VERSION "dbc-export 1 2025.20.8"

NS_ :

BS_:

BU_: ADSP APB APP APS APSB BB BMS CC CMP CMPD CP DAS DI DIF DIR DPB EPAS3P EPAS3S EPASTP EPASTS EPBL EPBR ESP GTW HVP IBST ICR IDB OCS1P ODIN PARK PCS PLG PM PMF PMR PTC RADC RCM RCM2 RCU SCCM SDCR TAS TCU TPMS TRCM UDS UI UIS UMC USM VC VCFRONT VCLEFT VCRIGHT VCSEC

BO_ 1520 USM_alertLog: 8 USM
 SG_ USM_alertID M : 0|8@1+ (1,0) [0|255] "" Vector__XXX
 SG_ USM_alertState : 15|1@1+ (1,0) [0|1] "" Vector__XXX
 SG_ USM_a001_InternalWatchdog m1 : 16|1@1+ (1,0) [0|1] "" Vector__XXX
 SG_ USM_a002_CPUUndervoltage m2 : 16|1@1+ (1,0) [0|1] "" Vector__XXX
 SG_ USM_a002_PowerOnReset m2 : 17|1@1+ (1,0) [0|1] "" Vector__XXX
 SG_ USM_a015_NVMMMemOverflow m15 : 16|1@1+ (1,0) [0|1] "" Vector__XXX
 SG_ USM_a015_NVMMFilesystemError m15 : 17|1@1+ (1,0) [0|1] "" Vector__XXX
 SG_ USM_a015_NVMMRecordIDError m15 : 18|1@1+ (1,0) [0|1] "" Vector__XXX
 SG_ USM_a057_VEH_cpControl m57 : 16|1@1+ (1,0) [0|1] "" Vector__XXX
 SG_ USM_a059_voltageDrop m59 : 16|12@1+ (0.005443676,0) [0|22.29185322] "V" Vector__XXX
 SG_ USM_a059_resistanceEstimate m59 : 28|12@1+ (0.00244,0) [0|9.9918] "Ohms" Vector__XXX
 SG_ USM_a059_current m59 : 40|12@1+ (0.05,0) [0|204.75] "A" Vector__XXX
 SG_ USM_a063_switchChannel m63 : 16|8@1+ (1,0) [0|255] "" Vector__XXX
 SG_ USM_a063_switchType m63 : 24|8@1+ (1,0) [0|255] "" Vector__XXX
 SG_ USM_a063_ADCVoltage m63 : 32|8@1+ (0.025,0) [0|6.375] "V" Vector__XXX
 SG_ USM_a063_disconnected m63 : 40|1@1+ (1,0) [0|1] "" Vector__XXX
 SG_ USM_a063_indeterminate m63 : 41|1@1+ (1,0) [0|1] "" Vector__XXX
 SG_ USM_a063_stuckActive m63 : 42|1@1+ (1,0) [0|1] "" Vector__XXX
 SG_ USM_a063_faulted m63 : 43|1@1+ (1,0) [0|1] "" Vector__XXX
 SG_ USM_a082_RIPC_epbPrivateState m82 : 16|1@1+ (1,0) [0|1] "" Vector__XXX
 SG_ USM_a082_RIPC_remoteHSD m82 : 17|1@1+ (1,0) [0|1] "" Vector__XXX
 SG_ USM_a082_RIPC_railStatus m82 : 18|1@1+ (1,0) [0|1] "" Vector__XXX
 SG_ USM_a082_RIPC_remoteMux m82 : 19|1@1+ (1,0) [0|1] "" Vector__XXX
 SG_ USM_a083_LIPC_epbPrivateState m83 : 16|1@1+ (1,0) [0|1] "" Vector__XXX
 SG_ USM_a083_LIPC_remoteHSD m83 : 17|1@1+ (1,0) [0|1] "" Vector__XXX
 SG_ USM_a083_LIPC_railStatus m83 : 18|1@1+ (1,0) [0|1] "" Vector__XXX
 SG_ USM_a083_LIPC_HSDFaults m83 : 19|1@1+ (1,0) [0|1] "" Vector__XXX
 SG_ USM_a084_CH_StatusC m84 : 16|1@1+ (1,0) [0|1] "" Vector__XXX
 SG_ USM_a085_PARTY_buttonStatus m85 : 16|1@1+ (1,0) [0|1] "" Vector__XXX
 SG_ USM_a086_VEH_LVBMS_statusHigh m86 : 16|1@1+ (1,0) [0|1] "" Vector__XXX
 SG_ USM_a086_VEH_LVBMS_statusLow m86 : 17|1@1+ (1,0) [0|1] "" Vector__XXX
 SG_ USM_a086_VEH_status m86 : 18|1@1+ (1,0) [0|1] "" Vector__XXX
 SG_ USM_a086_VEH_12VBatteryStatus m86 : 19|1@1+ (1,0) [0|1] "" Vector__XXX
 SG_ USM_a086_VEH_LVPowerState m86 : 20|1@1+ (1,0) [0|1] "" Vector__XXX
 SG_ USM_a086_VEH_lightStatus m86 : 21|1@1+ (1,0) [0|1] "" Vector__XXX
 SG_ USM_a086_VEH_systemStatus m86 : 22|1@1+ (1,0) [0|1] "" Vector__XXX
 SG_ USM_a086_VEH_thermalStatus m86 : 23|1@1+ (1,0) [0|1] "" Vector__XXX
 SG_ USM_a086_VEH_vehNm m86 : 24|1@1+ (1,0) [0|1] "" Vector__XXX
 SG_ USM_a087_VEH_temperature m87 : 16|1@1+ (1,0) [0|1] "" Vector__XXX
 SG_ USM_a087_VEH_thermalControl m87 : 17|1@1+ (1,0) [0|1] "" Vector__XXX
 SG_ USM_a087_VEH_torque m87 : 18|1@1+ (1,0) [0|1] "" Vector__XXX
 SG_ USM_a087_VEH_status m87 : 19|1@1+ (1,0) [0|1] "" Vector__XXX
 SG_ USM_a087_PARTY_torque m87 : 20|1@1+ (1,0) [0|1] "" Vector__XXX
 SG_ USM_a087_PARTY_status m87 : 21|1@1+ (1,0) [0|1] "" Vector__XXX
 SG_ USM_a087_PARTY_temperature m87 : 22|1@1+ (1,0) [0|1] "" Vector__XXX
 SG_ USM_a087_PARTY_thermalControl m87 : 23|1@1+ (1,0) [0|1] "" Vector__XXX
 SG_ USM_a088_VEH_temperature m88 : 16|1@1+ (1,0) [0|1] "" Vector__XXX
 SG_ USM_a088_VEH_thermalControl m88 : 17|1@1+ (1,0) [0|1] "" Vector__XXX
 SG_ USM_a088_VEH_torque m88 : 18|1@1+ (1,0) [0|1] "" Vector__XXX
 SG_ USM_a088_VEH_status m88 : 19|1@1+ (1,0) [0|1] "" Vector__XXX
 SG_ USM_a088_PARTY_torque m88 : 20|1@1+ (1,0) [0|1] "" Vector__XXX
 SG_ USM_a088_PARTY_status m88 : 21|1@1+ (1,0) [0|1] "" Vector__XXX
 SG_ USM_a088_PARTY_temperature m88 : 22|1@1+ (1,0) [0|1] "" Vector__XXX
 SG_ USM_a088_PARTY_thermalControl m88 : 23|1@1+ (1,0) [0|1] "" Vector__XXX
 SG_ USM_a089_PARTY_party1 m89 : 16|1@1+ (1,0) [0|1] "" Vector__XXX
 SG_ USM_a089_PARTY_status m89 : 17|1@1+ (1,0) [0|1] "" Vector__XXX
 SG_ USM_a089_VEH_status m89 : 18|1@1+ (1,0) [0|1] "" Vector__XXX
 SG_ USM_a089_BDY_party1 m89 : 19|1@1+ (1,0) [0|1] "" Vector__XXX
 SG_ USM_a089_BDY_status m89 : 20|1@1+ (1,0) [0|1] "" Vector__XXX
 SG_ USM_a089_CH_status m89 : 21|1@1+ (1,0) [0|1] "" Vector__XXX
 SG_ USM_a089_CH_party1 m89 : 22|1@1+ (1,0) [0|1] "" Vector__XXX
 SG_ USM_a089_CH_party3 m89 : 23|1@1+ (1,0) [0|1] "" Vector__XXX
 SG_ USM_a089_VEH_party1 m89 : 24|1@1+ (1,0) [0|1] "" Vector__XXX
 SG_ USM_a089_VEH_party3 m89 : 25|1@1+ (1,0) [0|1] "" Vector__XXX
 SG_ USM_a091_VEH_faultsAndExtras m91 : 16|1@1+ (1,0) [0|1] "" Vector__XXX
 SG_ USM_a091_VEH_info m91 : 17|1@1+ (1,0) [0|1] "" Vector__XXX
 SG_ USM_a091_VEH_state m91 : 18|1@1+ (1,0) [0|1] "" Vector__XXX
 SG_ USM_a092_VEH_restraintStatus m92 : 16|1@1+ (1,0) [0|1] "" Vector__XXX
 SG_ USM_a092_VEH_switchStatus m92 : 17|1@1+ (1,0) [0|1] "" Vector__XXX
 SG_ USM_a092_VEH_seatStatus2 m92 : 18|1@1+ (1,0) [0|1] "" Vector__XXX
 SG_ USM_a092_VEH_vehNm m92 : 19|1@1+ (1,0) [0|1] "" Vector__XXX
 SG_ USM_a093_VEH_restraintStatus m93 : 16|1@1+ (1,0) [0|1] "" Vector__XXX
 SG_ USM_a093_VEH_switchStatus m93 : 17|1@1+ (1,0) [0|1] "" Vector__XXX
 SG_ USM_a093_VEH_seatStatus2 m93 : 18|1@1+ (1,0) [0|1] "" Vector__XXX
 SG_ USM_a093_VEH_vehNm m93 : 19|1@1+ (1,0) [0|1] "" Vector__XXX
 SG_ USM_a094_VEH_sysStatus m94 : 16|1@1+ (1,0) [0|1] "" Vector__XXX
 SG_ USM_a094_PARTY_sysStatus m94 : 17|1@1+ (1,0) [0|1] "" Vector__XXX
 SG_ USM_a095_PT_ptNm m95 : 16|1@1+ (1,0) [0|1] "" Vector__XXX
 SG_ USM_a095_PT_status m95 : 17|1@1+ (1,0) [0|1] "" Vector__XXX
 SG_ USM_a096_VEH_status m96 : 16|1@1+ (1,0) [0|1] "" Vector__XXX
 SG_ USM_a096_CH_status m96 : 17|1@1+ (1,0) [0|1] "" Vector__XXX
 SG_ USM_a098_CH_torque m98 : 16|1@1+ (1,0) [0|1] "" Vector__XXX
 SG_ USM_a098_VEH_hvStatus m98 : 17|1@1+ (1,0) [0|1] "" Vector__XXX
 SG_ USM_a098_VEH_status m98 : 18|1@1+ (1,0) [0|1] "" Vector__XXX
 SG_ USM_a098_VEH_thermalControl m98 : 19|1@1+ (1,0) [0|1] "" Vector__XXX
 SG_ USM_a098_VEH_temperature m98 : 20|1@1+ (1,0) [0|1] "" Vector__XXX
 SG_ USM_a098_VEH_torque m98 : 21|1@1+ (1,0) [0|1] "" Vector__XXX
 SG_ USM_a098_PARTY_status m98 : 22|1@1+ (1,0) [0|1] "" Vector__XXX
 SG_ USM_a098_PARTY_temperature m98 : 23|1@1+ (1,0) [0|1] "" Vector__XXX
 SG_ USM_a098_PARTY_thermalControl m98 : 24|1@1+ (1,0) [0|1] "" Vector__XXX
 SG_ USM_a098_PARTY_torque m98 : 25|1@1+ (1,0) [0|1] "" Vector__XXX
 SG_ USM_a098_PT_thermalControl m98 : 26|1@1+ (1,0) [0|1] "" Vector__XXX
 SG_ USM_a098_PT_temperature m98 : 27|1@1+ (1,0) [0|1] "" Vector__XXX
 SG_ USM_a099_VEH_oocStatus m99 : 16|1@1+ (1,0) [0|1] "" Vector__XXX
 SG_ USM_a100_VEH m100 : 16|1@1+ (1,0) [0|1] "" Vector__XXX
 SG_ USM_a100_PARTY m100 : 17|1@1+ (1,0) [0|1] "" Vector__XXX
 SG_ USM_a100_PT m100 : 18|1@1+ (1,0) [0|1] "" Vector__XXX
 SG_ USM_a100_CH m100 : 19|1@1+ (1,0) [0|1] "" Vector__XXX
 SG_ USM_a100_OBD m100 : 20|1@1+ (1,0) [0|1] "" Vector__XXX
 SG_ USM_a101_VEH_state m101 : 16|1@1+ (1,0) [0|1] "" Vector__XXX
 SG_ USM_a101_PARTY_locState m101 : 17|1@1+ (1,0) [0|1] "" Vector__XXX
 SG_ USM_a101_LIPC_externalWatchdogHe m101 : 18|1@1+ (1,0) [0|1] "" Vector__XXX
 SG_ USM_a101_VEH_locState m101 : 19|1@1+ (1,0) [0|1] "" Vector__XXX
 SG_ USM_a101_BDY_locState m101 : 20|1@1+ (1,0) [0|1] "" Vector__XXX
 SG_ USM_a102_VEH_faultsAndExtras m102 : 16|1@1+ (1,0) [0|1] "" Vector__XXX
 SG_ USM_a102_VEH_feedbackStatus m102 : 17|1@1+ (1,0) [0|1] "" Vector__XXX
 SG_ USM_a102_VEH_sensorStatus m102 : 18|1@1+ (1,0) [0|1] "" Vector__XXX
 SG_ USM_a102_VEH_rods m102 : 19|1@1+ (1,0) [0|1] "" Vector__XXX
 SG_ USM_a103_VEH_hvsNm m103 : 16|1@1+ (1,0) [0|1] "" Vector__XXX
 SG_ USM_a103_VEH_vehNm m103 : 17|1@1+ (1,0) [0|1] "" Vector__XXX
 SG_ USM_a103_VEH_status m103 : 18|1@1+ (1,0) [0|1] "" Vector__XXX
 SG_ USM_a103_PT_ptNm m103 : 19|1@1+ (1,0) [0|1] "" Vector__XXX
 SG_ USM_a103_PT_status m103 : 20|1@1+ (1,0) [0|1] "" Vector__XXX
 SG_ USM_a103_VEH_evseStatus m103 : 21|1@1+ (1,0) [0|1] "" Vector__XXX
 SG_ USM_a105_VEH_states m105 : 16|1@1+ (1,0) [0|1] "" Vector__XXX
 SG_ USM_a105_VEH_chNm m105 : 17|1@1+ (1,0) [0|1] "" Vector__XXX
 SG_ USM_a105_VEH_dampingStates m105 : 18|1@1+ (1,0) [0|1] "" Vector__XXX
 SG_ USM_a106_VEH_dcdcStatus m106 : 16|1@1+ (1,0) [0|1] "" Vector__XXX
 SG_ USM_a106_VEH_thermalControl m106 : 17|1@1+ (1,0) [0|1] "" Vector__XXX
 SG_ USM_a106_VEH_thermalInterface m106 : 18|1@1+ (1,0) [0|1] "" Vector__XXX
 SG_ USM_a106_VEH_dcdcRailStatus m106 : 19|1@1+ (1,0) [0|1] "" Vector__XXX
 SG_ USM_a106_CH_dcdcRailStatus m106 : 20|1@1+ (1,0) [0|1] "" Vector__XXX
 SG_ USM_a106_CH_alertMatrix m106 : 21|1@1+ (1,0) [0|1] "" Vector__XXX
 SG_ USM_a107_VEH_hvsNm m107 : 16|1@1+ (1,0) [0|1] "" Vector__XXX
 SG_ USM_a107_VEH_vehNm m107 : 17|1@1+ (1,0) [0|1] "" Vector__XXX
 SG_ USM_a107_VEH_status m107 : 18|1@1+ (1,0) [0|1] "" Vector__XXX
 SG_ USM_a107_VEH_thermalStatus m107 : 19|1@1+ (1,0) [0|1] "" Vector__XXX
 SG_ USM_a107_VEH_thermalStatus2 m107 : 20|1@1+ (1,0) [0|1] "" Vector__XXX
 SG_ USM_a107_VEH_bmbMinMax m107 : 21|1@1+ (1,0) [0|1] "" Vector__XXX
 SG_ USM_a107_VEH_powerAvailable m107 : 22|1@1+ (1,0) [0|1] "" Vector__XXX
 SG_ USM_a107_PT_ptNm m107 : 23|1@1+ (1,0) [0|1] "" Vector__XXX
 SG_ USM_a107_PT_status m107 : 24|1@1+ (1,0) [0|1] "" Vector__XXX
 SG_ USM_a107_PT_thermalStatus m107 : 25|1@1+ (1,0) [0|1] "" Vector__XXX
 SG_ USM_a107_PT_socStatus m107 : 26|1@1+ (1,0) [0|1] "" Vector__XXX
 SG_ USM_a107_VEH_socStatus m107 : 27|1@1+ (1,0) [0|1] "" Vector__XXX
 SG_ USM_a107_VEH_packConfig m107 : 28|1@1+ (1,0) [0|1] "" Vector__XXX
 SG_ USM_a107_VEH_energyStatus m107 : 29|1@1+ (1,0) [0|1] "" Vector__XXX
 SG_ USM_a107_VEH_chargeInfo m107 : 30|1@1+ (1,0) [0|1] "" Vector__XXX
 SG_ USM_a108_VEH_hvStatus m108 : 16|1@1+ (1,0) [0|1] "" Vector__XXX
 SG_ USM_a108_VEH_temperature m108 : 17|1@1+ (1,0) [0|1] "" Vector__XXX
 SG_ USM_a108_VEH_thermalControl m108 : 18|1@1+ (1,0) [0|1] "" Vector__XXX
 SG_ USM_a108_VEH_torque m108 : 19|1@1+ (1,0) [0|1] "" Vector__XXX
 SG_ USM_a108_VEH_status m108 : 20|1@1+ (1,0) [0|1] "" Vector__XXX
 SG_ USM_a108_PARTY_torque m108 : 21|1@1+ (1,0) [0|1] "" Vector__XXX
 SG_ USM_a108_PARTY_status m108 : 22|1@1+ (1,0) [0|1] "" Vector__XXX
 SG_ USM_a108_PARTY_temperature m108 : 23|1@1+ (1,0) [0|1] "" Vector__XXX
 SG_ USM_a108_PARTY_thermalControl m108 : 24|1@1+ (1,0) [0|1] "" Vector__XXX
 SG_ USM_a108_PT_temperature m108 : 25|1@1+ (1,0) [0|1] "" Vector__XXX
 SG_ USM_a108_PT_thermalControl m108 : 26|1@1+ (1,0) [0|1] "" Vector__XXX
 SG_ USM_a109_PARTY_status m109 : 16|1@1+ (1,0) [0|1] "" Vector__XXX
 SG_ USM_a109_PARTY_inertial2 m109 : 17|1@1+ (1,0) [0|1] "" Vector__XXX
 SG_ USM_a109_PARTY_nearDeploy m109 : 18|1@1+ (1,0) [0|1] "" Vector__XXX
 SG_ USM_a109_PARTY_collision m109 : 19|1@1+ (1,0) [0|1] "" Vector__XXX
 SG_ USM_a109_VEH_status m109 : 20|1@1+ (1,0) [0|1] "" Vector__XXX
 SG_ USM_a109_VEH_imuOffsets m109 : 21|1@1+ (1,0) [0|1] "" Vector__XXX
 SG_ USM_a109_PARTY_inertial1 m109 : 22|1@1+ (1,0) [0|1] "" Vector__XXX
 SG_ USM_a109_BDY_imuOffsets m109 : 23|1@1+ (1,0) [0|1] "" Vector__XXX
 SG_ USM_a109_BDY_inertial1 m109 : 24|1@1+ (1,0) [0|1] "" Vector__XXX
 SG_ USM_a109_BDY_inertial2 m109 : 25|1@1+ (1,0) [0|1] "" Vector__XXX
 SG_ USM_a109_BDY_status m109 : 26|1@1+ (1,0) [0|1] "" Vector__XXX
 SG_ USM_a109_VEH_inertial1 m109 : 27|1@1+ (1,0) [0|1] "" Vector__XXX
 SG_ USM_a109_VEH_inertial2 m109 : 28|1@1+ (1,0) [0|1] "" Vector__XXX
 SG_ USM_a109_CH_inertial1 m109 : 29|1@1+ (1,0) [0|1] "" Vector__XXX
 SG_ USM_a109_CH_inertial2 m109 : 30|1@1+ (1,0) [0|1] "" Vector__XXX
 SG_ USM_a109_CH_status m109 : 31|1@1+ (1,0) [0|1] "" Vector__XXX
 SG_ USM_a110_VEH_carState m110 : 16|1@1+ (1,0) [0|1] "" Vector__XXX
 SG_ USM_a110_VEH_carConfig m110 : 17|1@1+ (1,0) [0|1] "" Vector__XXX
 SG_ USM_a110_VEH_time m110 : 18|1@1+ (1,0) [0|1] "" Vector__XXX
 SG_ USM_a110_VEH_updateStatus m110 : 19|1@1+ (1,0) [0|1] "" Vector__XXX
 SG_ USM_a110_VEH_vehNm m110 : 20|1@1+ (1,0) [0|1] "" Vector__XXX
 SG_ USM_a110_VEH_mismatchFault m110 : 21|1@1+ (1,0) [0|1] "" Vector__XXX
 SG_ USM_a110_VEH_vin m110 : 22|1@1+ (1,0) [0|1] "" Vector__XXX
 SG_ USM_a110_VEH_bmpDebug m110 : 23|1@1+ (1,0) [0|1] "" Vector__XXX
 SG_ USM_a110_VEH_gearControl m110 : 24|1@1+ (1,0) [0|1] "" Vector__XXX
 SG_ USM_a110_VEH_canLogAvailability m110 : 25|1@1+ (1,0) [0|1] "" Vector__XXX
 SG_ USM_a110_CH_airbagCutoffStatus m110 : 26|1@1+ (1,0) [0|1] "" Vector__XXX
 SG_ USM_a110_CH_carConfig m110 : 27|1@1+ (1,0) [0|1] "" Vector__XXX
 SG_ USM_a110_CH_carState m110 : 28|1@1+ (1,0) [0|1] "" Vector__XXX
 SG_ USM_a110_CH_vin m110 : 29|1@1+ (1,0) [0|1] "" Vector__XXX
 SG_ USM_a110_CH_chNm m110 : 30|1@1+ (1,0) [0|1] "" Vector__XXX
 SG_ USM_a110_CH_epochTimeGtw m110 : 31|1@1+ (1,0) [0|1] "" Vector__XXX
 SG_ USM_a111_VEH_internalStatus m111 : 16|1@1+ (1,0) [0|1] "" Vector__XXX
 SG_ USM_a111_VEH_status m111 : 17|1@1+ (1,0) [0|1] "" Vector__XXX
 SG_ USM_a111_VEH_vehNm m111 : 18|1@1+ (1,0) [0|1] "" Vector__XXX
 SG_ USM_a111_RIPC_LVPowerState m111 : 19|1@1+ (1,0) [0|1] "" Vector__XXX
 SG_ USM_a111_RIPC_epbPrivateState m111 : 20|1@1+ (1,0) [0|1] "" Vector__XXX
 SG_ USM_a111_RIPC_railStatus m111 : 21|1@1+ (1,0) [0|1] "" Vector__XXX
 SG_ USM_a111_RIPC_remoteADC m111 : 22|1@1+ (1,0) [0|1] "" Vector__XXX
 SG_ USM_a111_RIPC_switchStatus m111 : 23|1@1+ (1,0) [0|1] "" Vector__XXX
 SG_ USM_a111_VEH_LVPowerState m111 : 24|1@1+ (1,0) [0|1] "" Vector__XXX
 SG_ USM_a111_VEH_seatStatus m111 : 25|1@1+ (1,0) [0|1] "" Vector__XXX
 SG_ USM_a111_PARTY_status m111 : 26|1@1+ (1,0) [0|1] "" Vector__XXX
 SG_ USM_a111_CH_status m111 : 27|1@1+ (1,0) [0|1] "" Vector__XXX
 SG_ USM_a112_VEH_internalStatus m112 : 16|1@1+ (1,0) [0|1] "" Vector__XXX
 SG_ USM_a112_VEH_status m112 : 17|1@1+ (1,0) [0|1] "" Vector__XXX
 SG_ USM_a112_VEH_vehNm m112 : 18|1@1+ (1,0) [0|1] "" Vector__XXX
 SG_ USM_a112_LIPC_LVPowerState m112 : 19|1@1+ (1,0) [0|1] "" Vector__XXX
 SG_ USM_a112_LIPC_epbPrivateState m112 : 20|1@1+ (1,0) [0|1] "" Vector__XXX
 SG_ USM_a112_LIPC_railStatus m112 : 21|1@1+ (1,0) [0|1] "" Vector__XXX
 SG_ USM_a112_LIPC_remoteADC m112 : 22|1@1+ (1,0) [0|1] "" Vector__XXX
 SG_ USM_a112_LIPC_switchStatus m112 : 23|1@1+ (1,0) [0|1] "" Vector__XXX
 SG_ USM_a112_VEH_LVPowerState m112 : 24|1@1+ (1,0) [0|1] "" Vector__XXX
 SG_ USM_a112_PARTY_status m112 : 25|1@1+ (1,0) [0|1] "" Vector__XXX
 SG_ USM_a112_CH_status m112 : 26|1@1+ (1,0) [0|1] "" Vector__XXX
 SG_ USM_a114_PARTY_status m114 : 16|1@1+ (1,0) [0|1] "" Vector__XXX
 SG_ USM_a114_PARTY_wheelSpeeds m114 : 17|1@1+ (1,0) [0|1] "" Vector__XXX
 SG_ USM_a114_VEH_wheelSpeeds m114 : 18|1@1+ (1,0) [0|1] "" Vector__XXX
 SG_ USM_a114_CH_wheelSpeeds m114 : 19|1@1+ (1,0) [0|1] "" Vector__XXX
 SG_ USM_a114_PARTY_party3 m114 : 20|1@1+ (1,0) [0|1] "" Vector__XXX
 SG_ USM_a114_VEH_party3 m114 : 21|1@1+ (1,0) [0|1] "" Vector__XXX
 SG_ USM_a114_VEH_status m114 : 22|1@1+ (1,0) [0|1] "" Vector__XXX
 SG_ USM_a114_PARTY_wheelRotation m114 : 23|1@1+ (1,0) [0|1] "" Vector__XXX
 SG_ USM_a114_CH_wheelRotation m114 : 24|1@1+ (1,0) [0|1] "" Vector__XXX
 SG_ USM_a114_VEH_wheelRotation m114 : 25|1@1+ (1,0) [0|1] "" Vector__XXX
 SG_ USM_a114_PARTY_brakeTorque m114 : 26|1@1+ (1,0) [0|1] "" Vector__XXX
 SG_ USM_a114_PARTY_offsets m114 : 27|1@1+ (1,0) [0|1] "" Vector__XXX
 SG_ USM_a114_BDY_offsets m114 : 28|1@1+ (1,0) [0|1] "" Vector__XXX
 SG_ USM_a114_BDY_party3 m114 : 29|1@1+ (1,0) [0|1] "" Vector__XXX
 SG_ USM_a114_BDY_status m114 : 30|1@1+ (1,0) [0|1] "" Vector__XXX
 SG_ USM_a114_BDY_wheelRotation m114 : 31|1@1+ (1,0) [0|1] "" Vector__XXX
 SG_ USM_a114_BDY_wheelSpeeds m114 : 32|1@1+ (1,0) [0|1] "" Vector__XXX
 SG_ USM_a114_CH_party1 m114 : 33|1@1+ (1,0) [0|1] "" Vector__XXX
 SG_ USM_a114_CH_party3 m114 : 34|1@1+ (1,0) [0|1] "" Vector__XXX
 SG_ USM_a114_CH_status m114 : 35|1@1+ (1,0) [0|1] "" Vector__XXX
 SG_ USM_a115_VEH_vehNm m115 : 16|1@1+ (1,0) [0|1] "" Vector__XXX
 SG_ USM_a115_VEH_authentication m115 : 17|1@1+ (1,0) [0|1] "" Vector__XXX
 SG_ USM_a115_VEH_BLEResetRequest m115 : 18|1@1+ (1,0) [0|1] "" Vector__XXX
 SG_ USM_a115_VEH_requests m115 : 19|1@1+ (1,0) [0|1] "" Vector__XXX
 SG_ USM_a115_VEH_requests2 m115 : 20|1@1+ (1,0) [0|1] "" Vector__XXX
 SG_ USM_a115_REM_authentication m115 : 21|1@1+ (1,0) [0|1] "" Vector__XXX
 SG_ USM_a115_UI_corianderVehicleCont m115 : 22|1@1+ (1,0) [0|1] "" Vector__XXX
 SG_ USM_a115_CH_TPMSDisplay m115 : 23|1@1+ (1,0) [0|1] "" Vector__XXX
 SG_ USM_a116_PARTY_epbmStatus m116 : 16|1@1+ (1,0) [0|1] "" Vector__XXX
 SG_ USM_a116_VEH_vehNm m116 : 17|1@1+ (1,0) [0|1] "" Vector__XXX
 SG_ USM_a116_VEH_hvacRequest m116 : 18|1@1+ (1,0) [0|1] "" Vector__XXX
 SG_ USM_a116_VEH_hvacStatus m116 : 19|1@1+ (1,0) [0|1] "" Vector__XXX
 SG_ USM_a116_VEH_LVPowerState m116 : 20|1@1+ (1,0) [0|1] "" Vector__XXX
 SG_ USM_a116_VEH_lightStatus m116 : 21|1@1+ (1,0) [0|1] "" Vector__XXX
 SG_ USM_a116_VEH_seatStatus m116 : 22|1@1+ (1,0) [0|1] "" Vector__XXX
 SG_ USM_a116_VEH_thsStatus m116 : 23|1@1+ (1,0) [0|1] "" Vector__XXX
 SG_ USM_a116_VEH_doorStatus m116 : 24|1@1+ (1,0) [0|1] "" Vector__XXX
 SG_ USM_a116_VEH_seatHeatStatus m116 : 25|1@1+ (1,0) [0|1] "" Vector__XXX
 SG_ USM_a116_VEH_restraintStatus m116 : 26|1@1+ (1,0) [0|1] "" Vector__XXX
 SG_ USM_a116_VEH_switchStatus m116 : 27|1@1+ (1,0) [0|1] "" Vector__XXX
 SG_ USM_a116_VEH_logging1Hz m116 : 28|1@1+ (1,0) [0|1] "" Vector__XXX
 SG_ USM_a116_VEH_seatStatus2 m116 : 29|1@1+ (1,0) [0|1] "" Vector__XXX
 SG_ USM_a116_VEH_status m116 : 30|1@1+ (1,0) [0|1] "" Vector__XXX
 SG_ USM_a116_VEH_thermalCommand m116 : 31|1@1+ (1,0) [0|1] "" Vector__XXX
 SG_ USM_a116_VEH_windowStatus m116 : 32|1@1+ (1,0) [0|1] "" Vector__XXX
 SG_ USM_a116_PARTY_restraintStatus m116 : 33|1@1+ (1,0) [0|1] "" Vector__XXX
 SG_ USM_a116_PARTY_doorStatus m116 : 34|1@1+ (1,0) [0|1] "" Vector__XXX
 SG_ USM_a116_BDY_epbmStatus m116 : 35|1@1+ (1,0) [0|1] "" Vector__XXX
 SG_ USM_a116_BDY_restraintStatus m116 : 36|1@1+ (1,0) [0|1] "" Vector__XXX
 SG_ USM_a117_BDY_epbmStatus m117 : 16|1@1+ (1,0) [0|1] "" Vector__XXX
 SG_ USM_a117_BDY_restraintStatus m117 : 17|1@1+ (1,0) [0|1] "" Vector__XXX
 SG_ USM_a117_VEH_prndStatus m117 : 18|1@1+ (1,0) [0|1] "" Vector__XXX
 SG_ USM_a117_PARTY_epbmStatus m117 : 19|1@1+ (1,0) [0|1] "" Vector__XXX
 SG_ USM_a117_VEH_vehNm m117 : 20|1@1+ (1,0) [0|1] "" Vector__XXX
 SG_ USM_a117_VEH_hvacBlowerFdb m117 : 21|1@1+ (1,0) [0|1] "" Vector__XXX
 SG_ USM_a117_VEH_LVPowerState m117 : 22|1@1+ (1,0) [0|1] "" Vector__XXX
 SG_ USM_a117_VEH_restraintStatus m117 : 23|1@1+ (1,0) [0|1] "" Vector__XXX
 SG_ USM_a117_VEH_lightStatus m117 : 24|1@1+ (1,0) [0|1] "" Vector__XXX
 SG_ USM_a117_VEH_seatStatus m117 : 25|1@1+ (1,0) [0|1] "" Vector__XXX
 SG_ USM_a117_BDY_falconSwitchStatus m117 : 26|1@1+ (1,0) [0|1] "" Vector__XXX
 SG_ USM_a117_VEH_doorStatus m117 : 27|1@1+ (1,0) [0|1] "" Vector__XXX
 SG_ USM_a117_VEH_doorStatus2 m117 : 28|1@1+ (1,0) [0|1] "" Vector__XXX
 SG_ USM_a117_VEH_windowStatus m117 : 29|1@1+ (1,0) [0|1] "" Vector__XXX
 SG_ USM_a117_VEH_switchStatus m117 : 30|1@1+ (1,0) [0|1] "" Vector__XXX
 SG_ USM_a117_VEH_intrusionSensorStat m117 : 31|1@1+ (1,0) [0|1] "" Vector__XXX
 SG_ USM_a117_VEH_liftgateStatus m117 : 32|1@1+ (1,0) [0|1] "" Vector__XXX
 SG_ USM_a117_VEH_seatStatus2 m117 : 33|1@1+ (1,0) [0|1] "" Vector__XXX
 SG_ USM_a117_PARTY_restraintStatus m117 : 34|1@1+ (1,0) [0|1] "" Vector__XXX
 SG_ USM_a117_VEH_thermalStatus m117 : 35|1@1+ (1,0) [0|1] "" Vector__XXX
 SG_ USM_a117_PARTY_doorStatus m117 : 36|1@1+ (1,0) [0|1] "" Vector__XXX
 SG_ USM_a117_VEH_status m117 : 37|1@1+ (1,0) [0|1] "" Vector__XXX
 SG_ USM_a117_PARTY_prndStatus m117 : 38|1@1+ (1,0) [0|1] "" Vector__XXX
 SG_ USM_a118_VEH_vehNm m118 : 16|1@1+ (1,0) [0|1] "" Vector__XXX
 SG_ USM_a118_VEH_lighting m118 : 17|1@1+ (1,0) [0|1] "" Vector__XXX
 SG_ USM_a118_VEH_sensors m118 : 18|1@1+ (1,0) [0|1] "" Vector__XXX
 SG_ USM_a118_VEH_status m118 : 19|1@1+ (1,0) [0|1] "" Vector__XXX
 SG_ USM_a118_VEH_okToUseHighPwr m118 : 20|1@1+ (1,0) [0|1] "" Vector__XXX
 SG_ USM_a118_VEH_LVPowerState m118 : 21|1@1+ (1,0) [0|1] "" Vector__XXX
 SG_ USM_a118_VEH_coolant m118 : 22|1@1+ (1,0) [0|1] "" Vector__XXX
 SG_ USM_a118_VEH_vehicleStatus m118 : 23|1@1+ (1,0) [0|1] "" Vector__XXX
 SG_ USM_a118_VEH_12VBatteryStatus m118 : 24|1@1+ (1,0) [0|1] "" Vector__XXX
 SG_ USM_a118_VEH_systemStatus m118 : 25|1@1+ (1,0) [0|1] "" Vector__XXX
 SG_ USM_a118_PARTY_LVPowerState m118 : 26|1@1+ (1,0) [0|1] "" Vector__XXX
 SG_ USM_a118_PARTY_outputPowerStatus m118 : 27|1@1+ (1,0) [0|1] "" Vector__XXX
 SG_ USM_a118_PARTY_vehicleTime m118 : 28|1@1+ (1,0) [0|1] "" Vector__XXX
 SG_ USM_a118_VEH_thermalCommand m118 : 29|1@1+ (1,0) [0|1] "" Vector__XXX
 SG_ USM_a118_CH_LVPowerState m118 : 30|1@1+ (1,0) [0|1] "" Vector__XXX
 SG_ USM_a118_PARTY_sensors m118 : 31|1@1+ (1,0) [0|1] "" Vector__XXX
 SG_ USM_a118_CH_sensors m118 : 32|1@1+ (1,0) [0|1] "" Vector__XXX
 SG_ USM_a118_VEH_interNodeResistance m118 : 33|1@1+ (1,0) [0|1] "" Vector__XXX
 SG_ USM_a118_CH_lighting m118 : 34|1@1+ (1,0) [0|1] "" Vector__XXX
 SG_ USM_a118_VEH_lightStatus m118 : 35|1@1+ (1,0) [0|1] "" Vector__XXX
 SG_ USM_a118_PARTY_vehNm m118 : 36|1@1+ (1,0) [0|1] "" Vector__XXX
 SG_ USM_a118_CH_12VBatteryStatus m118 : 37|1@1+ (1,0) [0|1] "" Vector__XXX
 SG_ USM_a118_CH_LVBMS_statusHigh m118 : 38|1@1+ (1,0) [0|1] "" Vector__XXX
 SG_ USM_a118_CH_alertMatrix m118 : 39|1@1+ (1,0) [0|1] "" Vector__XXX
 SG_ USM_a118_BDY_outputPowerStatus m118 : 40|1@1+ (1,0) [0|1] "" Vector__XXX
 SG_ USM_a118_BDY_vehicleTime m118 : 41|1@1+ (1,0) [0|1] "" Vector__XXX
 SG_ USM_a118_PARTY_AP_vehicleState1H m118 : 42|1@1+ (1,0) [0|1] "" Vector__XXX
 SG_ USM_a118_BDY_AP_vehicleState1HzM m118 : 43|1@1+ (1,0) [0|1] "" Vector__XXX
 SG_ USM_a119_VEH_steerAngle m119 : 16|1@1+ (1,0) [0|1] "" Vector__XXX
 SG_ USM_a119_VEH_leftStalk m119 : 17|1@1+ (1,0) [0|1] "" Vector__XXX
 SG_ USM_a119_VEH_rightStalk m119 : 18|1@1+ (1,0) [0|1] "" Vector__XXX
 SG_ USM_a119_PARTY_rightStalk m119 : 19|1@1+ (1,0) [0|1] "" Vector__XXX
 SG_ USM_a119_CH_steerAngle m119 : 20|1@1+ (1,0) [0|1] "" Vector__XXX
 SG_ USM_a119_PARTY_steerAngle m119 : 21|1@1+ (1,0) [0|1] "" Vector__XXX
 SG_ USM_a120_PARTY_chassisCntl m120 : 16|1@1+ (1,0) [0|1] "" Vector__XXX
 SG_ USM_a120_VEH_systemStatus m120 : 17|1@1+ (1,0) [0|1] "" Vector__XXX
 SG_ USM_a120_CH_chassisCntl m120 : 18|1@1+ (1,0) [0|1] "" Vector__XXX
 SG_ USM_a120_PARTY_systemStatus m120 : 19|1@1+ (1,0) [0|1] "" Vector__XXX
 SG_ USM_a120_PARTY_torque m120 : 20|1@1+ (1,0) [0|1] "" Vector__XXX
 SG_ USM_a120_VEH_torque m120 : 21|1@1+ (1,0) [0|1] "" Vector__XXX
 SG_ USM_a120_PARTY_locStatus m120 : 22|1@1+ (1,0) [0|1] "" Vector__XXX
 SG_ USM_a120_PARTY_speed m120 : 23|1@1+ (1,0) [0|1] "" Vector__XXX
 SG_ USM_a120_VEH_speed m120 : 24|1@1+ (1,0) [0|1] "" Vector__XXX
 SG_ USM_a120_PARTY_status m120 : 25|1@1+ (1,0) [0|1] "" Vector__XXX
 SG_ USM_a120_PT_speed m120 : 26|1@1+ (1,0) [0|1] "" Vector__XXX
 SG_ USM_a120_PT_systemStatus m120 : 27|1@1+ (1,0) [0|1] "" Vector__XXX
 SG_ USM_a120_PARTY_vehicleEstimates m120 : 28|1@1+ (1,0) [0|1] "" Vector__XXX
 SG_ USM_a120_VEH_aggregatedAxleSpeed m120 : 29|1@1+ (1,0) [0|1] "" Vector__XXX
 SG_ USM_a120_PARTY_aggregatedAxleSpe m120 : 30|1@1+ (1,0) [0|1] "" Vector__XXX
 SG_ USM_a120_VEH_systemPower m120 : 31|1@1+ (1,0) [0|1] "" Vector__XXX
 SG_ USM_a120_PT_systemPower m120 : 32|1@1+ (1,0) [0|1] "" Vector__XXX
 SG_ USM_a120_PARTY_stalklessInterfac m120 : 33|1@1+ (1,0) [0|1] "" Vector__XXX
 SG_ USM_a120_CH_speed m120 : 34|1@1+ (1,0) [0|1] "" Vector__XXX
 SG_ USM_a120_VEH_estimatedBrakeTemp m120 : 35|1@1+ (1,0) [0|1] "" Vector__XXX
 SG_ USM_a120_PARTY_prndControl m120 : 36|1@1+ (1,0) [0|1] "" Vector__XXX
 SG_ USM_a120_PARTY_locStatus2 m120 : 37|1@1+ (1,0) [0|1] "" Vector__XXX
 SG_ USM_a120_VEH_chassisCntl m120 : 38|1@1+ (1,0) [0|1] "" Vector__XXX
 SG_ USM_a120_VEH_locStatus m120 : 39|1@1+ (1,0) [0|1] "" Vector__XXX
 SG_ USM_a120_VEH_locStatus2 m120 : 40|1@1+ (1,0) [0|1] "" Vector__XXX
 SG_ USM_a120_VEH_prndControl m120 : 41|1@1+ (1,0) [0|1] "" Vector__XXX
 SG_ USM_a120_VEH_vehicleEstimates m120 : 42|1@1+ (1,0) [0|1] "" Vector__XXX
 SG_ USM_a131_inDrivePowerState m131 : 16|1@1+ (1,0) [0|1] "" Vector__XXX
 SG_ USM_a131_timeSinceInit m131 : 24|16@1+ (1,0) [0|65535] "secs" Vector__XXX
 SG_ USM_a131_timeSincePwrStateTransi m131 : 40|16@1+ (1,0) [0|65535] "secs" Vector__XXX
 SG_ USM_a131_numComErrSinceInit m131 : 56|8@1+ (1,0) [0|255] "" Vector__XXX
 SG_ USM_a132_inDrivePowerState m132 : 16|1@1+ (1,0) [0|1] "" Vector__XXX
 SG_ USM_a132_timeSinceInit m132 : 24|16@1+ (1,0) [0|65535] "secs" Vector__XXX
 SG_ USM_a132_timeSincePwrStateTransi m132 : 40|16@1+ (1,0) [0|65535] "secs" Vector__XXX
 SG_ USM_a132_numComErrSinceInit m132 : 56|8@1+ (1,0) [0|255] "" Vector__XXX
 SG_ USM_a133_inDrivePowerState m133 : 16|1@1+ (1,0) [0|1] "" Vector__XXX
 SG_ USM_a133_timeSinceInit m133 : 24|16@1+ (1,0) [0|65535] "secs" Vector__XXX
 SG_ USM_a133_timeSincePwrStateTransi m133 : 40|16@1+ (1,0) [0|65535] "secs" Vector__XXX
 SG_ USM_a133_numComErrSinceInit m133 : 56|8@1+ (1,0) [0|255] "" Vector__XXX
 SG_ USM_a134_inDrivePowerState m134 : 16|1@1+ (1,0) [0|1] "" Vector__XXX
 SG_ USM_a134_timeSinceInit m134 : 24|16@1+ (1,0) [0|65535] "secs" Vector__XXX
 SG_ USM_a134_timeSincePwrStateTransi m134 : 40|16@1+ (1,0) [0|65535] "secs" Vector__XXX
 SG_ USM_a134_numComErrSinceInit m134 : 56|8@1+ (1,0) [0|255] "" Vector__XXX
 SG_ USM_a135_inDrivePowerState m135 : 16|1@1+ (1,0) [0|1] "" Vector__XXX
 SG_ USM_a135_timeSinceInit m135 : 24|16@1+ (1,0) [0|65535] "secs" Vector__XXX
 SG_ USM_a135_timeSincePwrStateTransi m135 : 40|16@1+ (1,0) [0|65535] "secs" Vector__XXX
 SG_ USM_a135_numComErrSinceInit m135 : 56|8@1+ (1,0) [0|255] "" Vector__XXX
 SG_ USM_a136_inDrivePowerState m136 : 16|1@1+ (1,0) [0|1] "" Vector__XXX
 SG_ USM_a136_timeSinceInit m136 : 24|16@1+ (1,0) [0|65535] "secs" Vector__XXX
 SG_ USM_a136_timeSincePwrStateTransi m136 : 40|16@1+ (1,0) [0|65535] "secs" Vector__XXX
 SG_ USM_a136_numComErrSinceInit m136 : 56|8@1+ (1,0) [0|255] "" Vector__XXX
 SG_ USM_a137_inDrivePowerState m137 : 16|1@1+ (1,0) [0|1] "" Vector__XXX
 SG_ USM_a137_timeSinceInit m137 : 24|16@1+ (1,0) [0|65535] "secs" Vector__XXX
 SG_ USM_a137_timeSincePwrStateTransi m137 : 40|16@1+ (1,0) [0|65535] "secs" Vector__XXX
 SG_ USM_a137_numComErrSinceInit m137 : 56|8@1+ (1,0) [0|255] "" Vector__XXX
 SG_ USM_a138_inDrivePowerState m138 : 16|1@1+ (1,0) [0|1] "" Vector__XXX
 SG_ USM_a138_timeSinceInit m138 : 24|16@1+ (1,0) [0|65535] "secs" Vector__XXX
 SG_ USM_a138_timeSincePwrStateTransi m138 : 40|16@1+ (1,0) [0|65535] "secs" Vector__XXX
 SG_ USM_a138_numComErrSinceInit m138 : 56|8@1+ (1,0) [0|255] "" Vector__XXX
 SG_ USM_a139_inDrivePowerState m139 : 16|1@1+ (1,0) [0|1] "" Vector__XXX
 SG_ USM_a139_timeSinceInit m139 : 24|16@1+ (1,0) [0|65535] "secs" Vector__XXX
 SG_ USM_a139_timeSincePwrStateTransi m139 : 40|16@1+ (1,0) [0|65535] "secs" Vector__XXX
 SG_ USM_a139_numComErrSinceInit m139 : 56|8@1+ (1,0) [0|255] "" Vector__XXX
 SG_ USM_a140_inDrivePowerState m140 : 16|1@1+ (1,0) [0|1] "" Vector__XXX
 SG_ USM_a140_timeSinceInit m140 : 24|16@1+ (1,0) [0|65535] "secs" Vector__XXX
 SG_ USM_a140_timeSincePwrStateTransi m140 : 40|16@1+ (1,0) [0|65535] "secs" Vector__XXX
 SG_ USM_a140_numComErrSinceInit m140 : 56|8@1+ (1,0) [0|255] "" Vector__XXX
 SG_ USM_a141_inDrivePowerState m141 : 16|1@1+ (1,0) [0|1] "" Vector__XXX
 SG_ USM_a141_timeSinceInit m141 : 24|16@1+ (1,0) [0|65535] "secs" Vector__XXX
 SG_ USM_a141_timeSincePwrStateTransi m141 : 40|16@1+ (1,0) [0|65535] "secs" Vector__XXX
 SG_ USM_a141_numComErrSinceInit m141 : 56|8@1+ (1,0) [0|255] "" Vector__XXX
 SG_ USM_a142_inDrivePowerState m142 : 16|1@1+ (1,0) [0|1] "" Vector__XXX
 SG_ USM_a142_timeSinceInit m142 : 24|16@1+ (1,0) [0|65535] "secs" Vector__XXX
 SG_ USM_a142_timeSincePwrStateTransi m142 : 40|16@1+ (1,0) [0|65535] "secs" Vector__XXX
 SG_ USM_a142_numComErrSinceInit m142 : 56|8@1+ (1,0) [0|255] "" Vector__XXX
 SG_ USM_a143_inDrivePowerState m143 : 16|1@1+ (1,0) [0|1] "" Vector__XXX
 SG_ USM_a143_timeSinceInit m143 : 24|16@1+ (1,0) [0|65535] "secs" Vector__XXX
 SG_ USM_a143_timeSincePwrStateTransi m143 : 40|16@1+ (1,0) [0|65535] "secs" Vector__XXX
 SG_ USM_a143_numHwErrSinceInit m143 : 56|8@1+ (1,0) [0|255] "" Vector__XXX
 SG_ USM_a144_inDrivePowerState m144 : 16|1@1+ (1,0) [0|1] "" Vector__XXX
 SG_ USM_a144_timeSinceInit m144 : 24|16@1+ (1,0) [0|65535] "secs" Vector__XXX
 SG_ USM_a144_timeSincePwrStateTransi m144 : 40|16@1+ (1,0) [0|65535] "secs" Vector__XXX
 SG_ USM_a144_numHwErrSinceInit m144 : 56|8@1+ (1,0) [0|255] "" Vector__XXX
 SG_ USM_a145_inDrivePowerState m145 : 16|1@1+ (1,0) [0|1] "" Vector__XXX
 SG_ USM_a145_timeSinceInit m145 : 24|16@1+ (1,0) [0|65535] "secs" Vector__XXX
 SG_ USM_a145_timeSincePwrStateTransi m145 : 40|16@1+ (1,0) [0|65535] "secs" Vector__XXX
 SG_ USM_a145_numHwErrSinceInit m145 : 56|8@1+ (1,0) [0|255] "" Vector__XXX
 SG_ USM_a146_inDrivePowerState m146 : 16|1@1+ (1,0) [0|1] "" Vector__XXX
 SG_ USM_a146_timeSinceInit m146 : 24|16@1+ (1,0) [0|65535] "secs" Vector__XXX
 SG_ USM_a146_timeSincePwrStateTransi m146 : 40|16@1+ (1,0) [0|65535] "secs" Vector__XXX
 SG_ USM_a146_numHwErrSinceInit m146 : 56|8@1+ (1,0) [0|255] "" Vector__XXX
 SG_ USM_a147_inDrivePowerState m147 : 16|1@1+ (1,0) [0|1] "" Vector__XXX
 SG_ USM_a147_timeSinceInit m147 : 24|16@1+ (1,0) [0|65535] "secs" Vector__XXX
 SG_ USM_a147_timeSincePwrStateTransi m147 : 40|16@1+ (1,0) [0|65535] "secs" Vector__XXX
 SG_ USM_a147_numHwErrSinceInit m147 : 56|8@1+ (1,0) [0|255] "" Vector__XXX
 SG_ USM_a148_inDrivePowerState m148 : 16|1@1+ (1,0) [0|1] "" Vector__XXX
 SG_ USM_a148_timeSinceInit m148 : 24|16@1+ (1,0) [0|65535] "secs" Vector__XXX
 SG_ USM_a148_timeSincePwrStateTransi m148 : 40|16@1+ (1,0) [0|65535] "secs" Vector__XXX
 SG_ USM_a148_numHwErrSinceInit m148 : 56|8@1+ (1,0) [0|255] "" Vector__XXX
 SG_ USM_a149_inDrivePowerState m149 : 16|1@1+ (1,0) [0|1] "" Vector__XXX
 SG_ USM_a149_timeSinceInit m149 : 24|16@1+ (1,0) [0|65535] "secs" Vector__XXX
 SG_ USM_a149_timeSincePwrStateTransi m149 : 40|16@1+ (1,0) [0|65535] "secs" Vector__XXX
 SG_ USM_a149_numHwErrSinceInit m149 : 56|8@1+ (1,0) [0|255] "" Vector__XXX
 SG_ USM_a150_inDrivePowerState m150 : 16|1@1+ (1,0) [0|1] "" Vector__XXX
 SG_ USM_a150_timeSinceInit m150 : 24|16@1+ (1,0) [0|65535] "secs" Vector__XXX
 SG_ USM_a150_timeSincePwrStateTransi m150 : 40|16@1+ (1,0) [0|65535] "secs" Vector__XXX
 SG_ USM_a150_numHwErrSinceInit m150 : 56|8@1+ (1,0) [0|255] "" Vector__XXX
 SG_ USM_a151_inDrivePowerState m151 : 16|1@1+ (1,0) [0|1] "" Vector__XXX
 SG_ USM_a151_timeSinceInit m151 : 24|16@1+ (1,0) [0|65535] "secs" Vector__XXX
 SG_ USM_a151_timeSincePwrStateTransi m151 : 40|16@1+ (1,0) [0|65535] "secs" Vector__XXX
 SG_ USM_a151_numHwErrSinceInit m151 : 56|8@1+ (1,0) [0|255] "" Vector__XXX
 SG_ USM_a152_inDrivePowerState m152 : 16|1@1+ (1,0) [0|1] "" Vector__XXX
 SG_ USM_a152_timeSinceInit m152 : 24|16@1+ (1,0) [0|65535] "secs" Vector__XXX
 SG_ USM_a152_timeSincePwrStateTransi m152 : 40|16@1+ (1,0) [0|65535] "secs" Vector__XXX
 SG_ USM_a152_numHwErrSinceInit m152 : 56|8@1+ (1,0) [0|255] "" Vector__XXX
 SG_ USM_a153_inDrivePowerState m153 : 16|1@1+ (1,0) [0|1] "" Vector__XXX
 SG_ USM_a153_timeSinceInit m153 : 24|16@1+ (1,0) [0|65535] "secs" Vector__XXX
 SG_ USM_a153_timeSincePwrStateTransi m153 : 40|16@1+ (1,0) [0|65535] "secs" Vector__XXX
 SG_ USM_a153_numHwErrSinceInit m153 : 56|8@1+ (1,0) [0|255] "" Vector__XXX
 SG_ USM_a154_inDrivePowerState m154 : 16|1@1+ (1,0) [0|1] "" Vector__XXX
 SG_ USM_a154_timeSinceInit m154 : 24|16@1+ (1,0) [0|65535] "secs" Vector__XXX
 SG_ USM_a154_timeSincePwrStateTransi m154 : 40|16@1+ (1,0) [0|65535] "secs" Vector__XXX
 SG_ USM_a154_numHwErrSinceInit m154 : 56|8@1+ (1,0) [0|255] "" Vector__XXX
 SG_ USM_a155_temperature m155 : 16|8@1- (1,33) [-95|160] "degC" Vector__XXX
 SG_ USM_a156_temperature m156 : 16|8@1- (1,33) [-95|160] "degC" Vector__XXX
 SG_ USM_a157_temperature m157 : 16|8@1- (1,33) [-95|160] "degC" Vector__XXX
 SG_ USM_a158_temperature m158 : 16|8@1- (1,33) [-95|160] "degC" Vector__XXX
 SG_ USM_a159_temperature m159 : 16|8@1- (1,33) [-95|160] "degC" Vector__XXX
 SG_ USM_a160_temperature m160 : 16|8@1- (1,33) [-95|160] "degC" Vector__XXX
 SG_ USM_a161_temperature m161 : 16|8@1- (1,33) [-95|160] "degC" Vector__XXX
 SG_ USM_a162_temperature m162 : 16|8@1- (1,33) [-95|160] "degC" Vector__XXX
 SG_ USM_a163_temperature m163 : 16|8@1- (1,33) [-95|160] "degC" Vector__XXX
 SG_ USM_a164_temperature m164 : 16|8@1- (1,33) [-95|160] "degC" Vector__XXX
 SG_ USM_a165_temperature m165 : 16|8@1- (1,33) [-95|160] "degC" Vector__XXX
 SG_ USM_a166_temperature m166 : 16|8@1- (1,33) [-95|160] "degC" Vector__XXX
 SG_ USM_a177_rtmCompensated m177 : 16|8@1+ (8,0) [0|2040] "us" Vector__XXX
 SG_ USM_a177_rtmOffset m177 : 24|8@1- (2,0) [-256|254] "us" Vector__XXX
 SG_ USM_a177_rtmOffsetFromInit m177 : 32|1@1+ (1,0) [0|1] "" Vector__XXX
 SG_ USM_a177_ambientTemperature m177 : 40|8@1+ (0.5,-40) [-39.5|87.5] "degC" Vector__XXX
 SG_ USM_a177_sensorTemperature m177 : 48|8@1- (1,33) [-95|160] "degC" Vector__XXX
 SG_ USM_a178_rtmCompensated m178 : 16|8@1+ (8,0) [0|2040] "us" Vector__XXX
 SG_ USM_a178_rtmOffset m178 : 24|8@1- (2,0) [-256|254] "us" Vector__XXX
 SG_ USM_a178_rtmOffsetFromInit m178 : 32|1@1+ (1,0) [0|1] "" Vector__XXX
 SG_ USM_a178_ambientTemperature m178 : 40|8@1+ (0.5,-40) [-39.5|87.5] "degC" Vector__XXX
 SG_ USM_a178_sensorTemperature m178 : 48|8@1- (1,33) [-95|160] "degC" Vector__XXX
 SG_ USM_a179_rtmCompensated m179 : 16|8@1+ (8,0) [0|2040] "us" Vector__XXX
 SG_ USM_a179_rtmOffset m179 : 24|8@1- (2,0) [-256|254] "us" Vector__XXX
 SG_ USM_a179_rtmOffsetFromInit m179 : 32|1@1+ (1,0) [0|1] "" Vector__XXX
 SG_ USM_a179_ambientTemperature m179 : 40|8@1+ (0.5,-40) [-39.5|87.5] "degC" Vector__XXX
 SG_ USM_a179_sensorTemperature m179 : 48|8@1- (1,33) [-95|160] "degC" Vector__XXX
 SG_ USM_a180_rtmCompensated m180 : 16|8@1+ (8,0) [0|2040] "us" Vector__XXX
 SG_ USM_a180_rtmOffset m180 : 24|8@1- (2,0) [-256|254] "us" Vector__XXX
 SG_ USM_a180_rtmOffsetFromInit m180 : 32|1@1+ (1,0) [0|1] "" Vector__XXX
 SG_ USM_a180_ambientTemperature m180 : 40|8@1+ (0.5,-40) [-39.5|87.5] "degC" Vector__XXX
 SG_ USM_a180_sensorTemperature m180 : 48|8@1- (1,33) [-95|160] "degC" Vector__XXX
 SG_ USM_a181_rtmCompensated m181 : 16|8@1+ (8,0) [0|2040] "us" Vector__XXX
 SG_ USM_a181_rtmOffset m181 : 24|8@1- (2,0) [-256|254] "us" Vector__XXX
 SG_ USM_a181_rtmOffsetFromInit m181 : 32|1@1+ (1,0) [0|1] "" Vector__XXX
 SG_ USM_a181_ambientTemperature m181 : 40|8@1+ (0.5,-40) [-39.5|87.5] "degC" Vector__XXX
 SG_ USM_a181_sensorTemperature m181 : 48|8@1- (1,33) [-95|160] "degC" Vector__XXX
 SG_ USM_a182_rtmCompensated m182 : 16|8@1+ (8,0) [0|2040] "us" Vector__XXX
 SG_ USM_a182_rtmOffset m182 : 24|8@1- (2,0) [-256|254] "us" Vector__XXX
 SG_ USM_a182_rtmOffsetFromInit m182 : 32|1@1+ (1,0) [0|1] "" Vector__XXX
 SG_ USM_a182_ambientTemperature m182 : 40|8@1+ (0.5,-40) [-39.5|87.5] "degC" Vector__XXX
 SG_ USM_a182_sensorTemperature m182 : 48|8@1- (1,33) [-95|160] "degC" Vector__XXX
 SG_ USM_a183_rtmCompensated m183 : 16|8@1+ (8,0) [0|2040] "us" Vector__XXX
 SG_ USM_a183_rtmOffset m183 : 24|8@1- (2,0) [-256|254] "us" Vector__XXX
 SG_ USM_a183_rtmOffsetFromInit m183 : 32|1@1+ (1,0) [0|1] "" Vector__XXX
 SG_ USM_a183_ambientTemperature m183 : 40|8@1+ (0.5,-40) [-39.5|87.5] "degC" Vector__XXX
 SG_ USM_a183_sensorTemperature m183 : 48|8@1- (1,33) [-95|160] "degC" Vector__XXX
 SG_ USM_a184_rtmCompensated m184 : 16|8@1+ (8,0) [0|2040] "us" Vector__XXX
 SG_ USM_a184_rtmOffset m184 : 24|8@1- (2,0) [-256|254] "us" Vector__XXX
 SG_ USM_a184_rtmOffsetFromInit m184 : 32|1@1+ (1,0) [0|1] "" Vector__XXX
 SG_ USM_a184_ambientTemperature m184 : 40|8@1+ (0.5,-40) [-39.5|87.5] "degC" Vector__XXX
 SG_ USM_a184_sensorTemperature m184 : 48|8@1- (1,33) [-95|160] "degC" Vector__XXX
 SG_ USM_a185_rtmCompensated m185 : 16|8@1+ (8,0) [0|2040] "us" Vector__XXX
 SG_ USM_a185_rtmOffset m185 : 24|8@1- (2,0) [-256|254] "us" Vector__XXX
 SG_ USM_a185_rtmOffsetFromInit m185 : 32|1@1+ (1,0) [0|1] "" Vector__XXX
 SG_ USM_a185_ambientTemperature m185 : 40|8@1+ (0.5,-40) [-39.5|87.5] "degC" Vector__XXX
 SG_ USM_a185_sensorTemperature m185 : 48|8@1- (1,33) [-95|160] "degC" Vector__XXX
 SG_ USM_a186_rtmCompensated m186 : 16|8@1+ (8,0) [0|2040] "us" Vector__XXX
 SG_ USM_a186_rtmOffset m186 : 24|8@1- (2,0) [-256|254] "us" Vector__XXX
 SG_ USM_a186_rtmOffsetFromInit m186 : 32|1@1+ (1,0) [0|1] "" Vector__XXX
 SG_ USM_a186_ambientTemperature m186 : 40|8@1+ (0.5,-40) [-39.5|87.5] "degC" Vector__XXX
 SG_ USM_a186_sensorTemperature m186 : 48|8@1- (1,33) [-95|160] "degC" Vector__XXX
 SG_ USM_a187_rtmCompensated m187 : 16|8@1+ (8,0) [0|2040] "us" Vector__XXX
 SG_ USM_a187_rtmOffset m187 : 24|8@1- (2,0) [-256|254] "us" Vector__XXX
 SG_ USM_a187_rtmOffsetFromInit m187 : 32|1@1+ (1,0) [0|1] "" Vector__XXX
 SG_ USM_a187_ambientTemperature m187 : 40|8@1+ (0.5,-40) [-39.5|87.5] "degC" Vector__XXX
 SG_ USM_a187_sensorTemperature m187 : 48|8@1- (1,33) [-95|160] "degC" Vector__XXX
 SG_ USM_a188_rtmCompensated m188 : 16|8@1+ (8,0) [0|2040] "us" Vector__XXX
 SG_ USM_a188_rtmOffset m188 : 24|8@1- (2,0) [-256|254] "us" Vector__XXX
 SG_ USM_a188_rtmOffsetFromInit m188 : 32|1@1+ (1,0) [0|1] "" Vector__XXX
 SG_ USM_a188_ambientTemperature m188 : 40|8@1+ (0.5,-40) [-39.5|87.5] "degC" Vector__XXX
 SG_ USM_a188_sensorTemperature m188 : 48|8@1- (1,33) [-95|160] "degC" Vector__XXX
 SG_ USM_a201_channel m201 : 16|2@1+ (1,0) [0|3] "" Vector__XXX
 SG_ USM_a201_OT m201 : 18|1@1+ (1,0) [0|1] "" Vector__XXX
 SG_ USM_a201_VCCUV_RFCB m201 : 19|1@1+ (1,0) [0|1] "" Vector__XXX
 SG_ USM_a201_CLKREF_ERROR m201 : 20|1@1+ (1,0) [0|1] "" Vector__XXX
 SG_ USM_a201_CMD_INC m201 : 21|1@1+ (1,0) [0|1] "" Vector__XXX
 SG_ USM_a201_CRC_ERROR m201 : 22|1@1+ (1,0) [0|1] "" Vector__XXX
 SG_ USM_a201_UND_CMD m201 : 23|1@1+ (1,0) [0|1] "" Vector__XXX
 SG_ USM_a201_DSI1_CMD_OVR m201 : 24|1@1+ (1,0) [0|1] "" Vector__XXX
 SG_ USM_a201_DSI2_CMD_OVR m201 : 25|1@1+ (1,0) [0|1] "" Vector__XXX
 SG_ USM_a201_DSI1_UV m201 : 26|1@1+ (1,0) [0|1] "" Vector__XXX
 SG_ USM_a201_DSI2_UV m201 : 27|1@1+ (1,0) [0|1] "" Vector__XXX
 SG_ USM_a201_DSI1_ND m201 : 28|1@1+ (1,0) [0|1] "" Vector__XXX
 SG_ USM_a201_DSI2_ND m201 : 29|1@1+ (1,0) [0|1] "" Vector__XXX
 SG_ USM_a201_DSI1_OR m201 : 30|1@1+ (1,0) [0|1] "" Vector__XXX
 SG_ USM_a201_DSI2_OR m201 : 31|1@1+ (1,0) [0|1] "" Vector__XXX
 SG_ USM_a201_DSI1_DL m201 : 32|1@1+ (1,0) [0|1] "" Vector__XXX
 SG_ USM_a201_DSI2_DL m201 : 33|1@1+ (1,0) [0|1] "" Vector__XXX
 SG_ USM_a201_DSI1_PC m201 : 34|1@1+ (1,0) [0|1] "" Vector__XXX
 SG_ USM_a201_DSI2_PC m201 : 35|1@1+ (1,0) [0|1] "" Vector__XXX
 SG_ USM_a202_channel m202 : 16|4@1+ (1,0) [0|15] "" Vector__XXX
 SG_ USM_a202_EE m202 : 20|1@1+ (1,0) [0|1] "" Vector__XXX
 SG_ USM_a202_LE m202 : 21|1@1+ (1,0) [0|1] "" Vector__XXX
 SG_ USM_a202_SC m202 : 22|1@1+ (1,0) [0|1] "" Vector__XXX
 SG_ USM_a202_CR m202 : 23|1@1+ (1,0) [0|1] "" Vector__XXX
 SG_ USM_a202_SP m202 : 24|1@1+ (1,0) [0|1] "" Vector__XXX
 SG_ USM_a202_SE m202 : 25|1@1+ (1,0) [0|1] "" Vector__XXX
 SG_ USM_a202_UV m202 : 26|1@1+ (1,0) [0|1] "" Vector__XXX
 SG_ USM_a202_CE m202 : 27|1@1+ (1,0) [0|1] "" Vector__XXX
 SG_ USM_a227_reset m227 : 16|1@1+ (1,0) [0|1] "" Vector__XXX
 SG_ USM_a227_otpCrcError m227 : 17|1@1+ (1,0) [0|1] "" Vector__XXX
 SG_ USM_a227_trimRegParityErr m227 : 18|1@1+ (1,0) [0|1] "" Vector__XXX
 SG_ USM_a227_sramParityErr m227 : 19|1@1+ (1,0) [0|1] "" Vector__XXX
 SG_ USM_a227_crcMismatchInOtp m227 : 20|1@1+ (1,0) [0|1] "" Vector__XXX
 SG_ USM_a227_crcMismatchInSysrom m227 : 21|1@1+ (1,0) [0|1] "" Vector__XXX
 SG_ USM_a227_crcMismatchInEeprom m227 : 22|1@1+ (1,0) [0|1] "" Vector__XXX
 SG_ USM_a227_capLossVdddOutOfRange m227 : 23|1@1+ (1,0) [0|1] "" Vector__XXX
 SG_ USM_a227_capLossVddaOutOfRange m227 : 24|1@1+ (1,0) [0|1] "" Vector__XXX
 SG_ USM_a227_referenceVoltOutOfRange m227 : 25|1@1+ (1,0) [0|1] "" Vector__XXX
 SG_ USM_a227_vdddVoltOutOfRange m227 : 26|1@1+ (1,0) [0|1] "" Vector__XXX
 SG_ USM_a227_vrefVoldOfOtpOutOfRange m227 : 27|1@1+ (1,0) [0|1] "" Vector__XXX
 SG_ USM_a227_eepromProgFail m227 : 28|1@1+ (1,0) [0|1] "" Vector__XXX
 SG_ USM_a227_eepromProgBuys m227 : 29|1@1+ (1,0) [0|1] "" Vector__XXX
 SG_ USM_a227_vsupVoltOutOfRange m227 : 30|1@1+ (1,0) [0|1] "" Vector__XXX
 SG_ USM_a227_tempSensOutOfRange m227 : 31|1@1+ (1,0) [0|1] "" Vector__XXX
 SG_ USM_a227_underVoltAtVtankDuringB m227 : 32|1@1+ (1,0) [0|1] "" Vector__XXX
 SG_ USM_a227_overVoltAtVtankDuringBu m227 : 33|1@1+ (1,0) [0|1] "" Vector__XXX
 SG_ USM_a227_drvsFailDuringBurst m227 : 34|1@1+ (1,0) [0|1] "" Vector__XXX
 SG_ USM_a227_drv1FailDuringBurst m227 : 35|1@1+ (1,0) [0|1] "" Vector__XXX
 SG_ USM_a227_drv2FailDuringBurst m227 : 36|1@1+ (1,0) [0|1] "" Vector__XXX
 SG_ USM_a227_crcMismatchInRam m227 : 37|1@1+ (1,0) [0|1] "" Vector__XXX
 SG_ USM_a227_verificationOfConfigAnd m227 : 38|1@1+ (1,0) [0|1] "" Vector__XXX
 SG_ USM_a227_wdgClockFreqOutOfRange m227 : 39|1@1+ (1,0) [0|1] "" Vector__XXX
 SG_ USM_a227_atgNoiseMeasOutOfRange m227 : 40|1@1+ (1,0) [0|1] "" Vector__XXX
 SG_ USM_a227_syncCountError m227 : 41|1@1+ (1,0) [0|1] "" Vector__XXX
 SG_ USM_a227_invalidStartEdge m227 : 42|1@1+ (1,0) [0|1] "" Vector__XXX
 SG_ USM_a227_receiverReachedErrorSta m227 : 43|1@1+ (1,0) [0|1] "" Vector__XXX
 SG_ USM_a227_pdcmPulseInvalid m227 : 44|1@1+ (1,0) [0|1] "" Vector__XXX
 SG_ USM_a227_crcOfReceivedCmdInvalid m227 : 45|1@1+ (1,0) [0|1] "" Vector__XXX
 SG_ USM_a227_passwordWrong m227 : 46|1@1+ (1,0) [0|1] "" Vector__XXX
 SG_ USM_a227_timeIntBetween2PulsesEr m227 : 47|1@1+ (1,0) [0|1] "" Vector__XXX
 SG_ USM_a227_numInvalidStartEdgeSinc m227 : 48|4@1+ (1,0) [0|15] "" Vector__XXX
 SG_ USM_a227_numAtgNoiseErrorsSinceI m227 : 52|4@1+ (1,0) [0|15] "" Vector__XXX
 SG_ USM_a228_reset m228 : 16|1@1+ (1,0) [0|1] "" Vector__XXX
 SG_ USM_a228_otpCrcError m228 : 17|1@1+ (1,0) [0|1] "" Vector__XXX
 SG_ USM_a228_trimRegParityErr m228 : 18|1@1+ (1,0) [0|1] "" Vector__XXX
 SG_ USM_a228_sramParityErr m228 : 19|1@1+ (1,0) [0|1] "" Vector__XXX
 SG_ USM_a228_crcMismatchInOtp m228 : 20|1@1+ (1,0) [0|1] "" Vector__XXX
 SG_ USM_a228_crcMismatchInSysrom m228 : 21|1@1+ (1,0) [0|1] "" Vector__XXX
 SG_ USM_a228_crcMismatchInEeprom m228 : 22|1@1+ (1,0) [0|1] "" Vector__XXX
 SG_ USM_a228_capLossVdddOutOfRange m228 : 23|1@1+ (1,0) [0|1] "" Vector__XXX
 SG_ USM_a228_capLossVddaOutOfRange m228 : 24|1@1+ (1,0) [0|1] "" Vector__XXX
 SG_ USM_a228_referenceVoltOutOfRange m228 : 25|1@1+ (1,0) [0|1] "" Vector__XXX
 SG_ USM_a228_vdddVoltOutOfRange m228 : 26|1@1+ (1,0) [0|1] "" Vector__XXX
 SG_ USM_a228_vrefVoldOfOtpOutOfRange m228 : 27|1@1+ (1,0) [0|1] "" Vector__XXX
 SG_ USM_a228_eepromProgFail m228 : 28|1@1+ (1,0) [0|1] "" Vector__XXX
 SG_ USM_a228_eepromProgBuys m228 : 29|1@1+ (1,0) [0|1] "" Vector__XXX
 SG_ USM_a228_vsupVoltOutOfRange m228 : 30|1@1+ (1,0) [0|1] "" Vector__XXX
 SG_ USM_a228_tempSensOutOfRange m228 : 31|1@1+ (1,0) [0|1] "" Vector__XXX
 SG_ USM_a228_underVoltAtVtankDuringB m228 : 32|1@1+ (1,0) [0|1] "" Vector__XXX
 SG_ USM_a228_overVoltAtVtankDuringBu m228 : 33|1@1+ (1,0) [0|1] "" Vector__XXX
 SG_ USM_a228_drvsFailDuringBurst m228 : 34|1@1+ (1,0) [0|1] "" Vector__XXX
 SG_ USM_a228_drv1FailDuringBurst m228 : 35|1@1+ (1,0) [0|1] "" Vector__XXX
 SG_ USM_a228_drv2FailDuringBurst m228 : 36|1@1+ (1,0) [0|1] "" Vector__XXX
 SG_ USM_a228_crcMismatchInRam m228 : 37|1@1+ (1,0) [0|1] "" Vector__XXX
 SG_ USM_a228_verificationOfConfigAnd m228 : 38|1@1+ (1,0) [0|1] "" Vector__XXX
 SG_ USM_a228_wdgClockFreqOutOfRange m228 : 39|1@1+ (1,0) [0|1] "" Vector__XXX
 SG_ USM_a228_atgNoiseMeasOutOfRange m228 : 40|1@1+ (1,0) [0|1] "" Vector__XXX
 SG_ USM_a228_syncCountError m228 : 41|1@1+ (1,0) [0|1] "" Vector__XXX
 SG_ USM_a228_invalidStartEdge m228 : 42|1@1+ (1,0) [0|1] "" Vector__XXX
 SG_ USM_a228_receiverReachedErrorSta m228 : 43|1@1+ (1,0) [0|1] "" Vector__XXX
 SG_ USM_a228_pdcmPulseInvalid m228 : 44|1@1+ (1,0) [0|1] "" Vector__XXX
 SG_ USM_a228_crcOfReceivedCmdInvalid m228 : 45|1@1+ (1,0) [0|1] "" Vector__XXX
 SG_ USM_a228_passwordWrong m228 : 46|1@1+ (1,0) [0|1] "" Vector__XXX
 SG_ USM_a228_timeIntBetween2PulsesEr m228 : 47|1@1+ (1,0) [0|1] "" Vector__XXX
 SG_ USM_a228_numInvalidStartEdgeSinc m228 : 48|4@1+ (1,0) [0|15] "" Vector__XXX
 SG_ USM_a228_numAtgNoiseErrorsSinceI m228 : 52|4@1+ (1,0) [0|15] "" Vector__XXX
 SG_ USM_a229_reset m229 : 16|1@1+ (1,0) [0|1] "" Vector__XXX
 SG_ USM_a229_otpCrcError m229 : 17|1@1+ (1,0) [0|1] "" Vector__XXX
 SG_ USM_a229_trimRegParityErr m229 : 18|1@1+ (1,0) [0|1] "" Vector__XXX
 SG_ USM_a229_sramParityErr m229 : 19|1@1+ (1,0) [0|1] "" Vector__XXX
 SG_ USM_a229_crcMismatchInOtp m229 : 20|1@1+ (1,0) [0|1] "" Vector__XXX
 SG_ USM_a229_crcMismatchInSysrom m229 : 21|1@1+ (1,0) [0|1] "" Vector__XXX
 SG_ USM_a229_crcMismatchInEeprom m229 : 22|1@1+ (1,0) [0|1] "" Vector__XXX
 SG_ USM_a229_capLossVdddOutOfRange m229 : 23|1@1+ (1,0) [0|1] "" Vector__XXX
 SG_ USM_a229_capLossVddaOutOfRange m229 : 24|1@1+ (1,0) [0|1] "" Vector__XXX
 SG_ USM_a229_referenceVoltOutOfRange m229 : 25|1@1+ (1,0) [0|1] "" Vector__XXX
 SG_ USM_a229_vdddVoltOutOfRange m229 : 26|1@1+ (1,0) [0|1] "" Vector__XXX
 SG_ USM_a229_vrefVoldOfOtpOutOfRange m229 : 27|1@1+ (1,0) [0|1] "" Vector__XXX
 SG_ USM_a229_eepromProgFail m229 : 28|1@1+ (1,0) [0|1] "" Vector__XXX
 SG_ USM_a229_eepromProgBuys m229 : 29|1@1+ (1,0) [0|1] "" Vector__XXX
 SG_ USM_a229_vsupVoltOutOfRange m229 : 30|1@1+ (1,0) [0|1] "" Vector__XXX
 SG_ USM_a229_tempSensOutOfRange m229 : 31|1@1+ (1,0) [0|1] "" Vector__XXX
 SG_ USM_a229_underVoltAtVtankDuringB m229 : 32|1@1+ (1,0) [0|1] "" Vector__XXX
 SG_ USM_a229_overVoltAtVtankDuringBu m229 : 33|1@1+ (1,0) [0|1] "" Vector__XXX
 SG_ USM_a229_drvsFailDuringBurst m229 : 34|1@1+ (1,0) [0|1] "" Vector__XXX
 SG_ USM_a229_drv1FailDuringBurst m229 : 35|1@1+ (1,0) [0|1] "" Vector__XXX
 SG_ USM_a229_drv2FailDuringBurst m229 : 36|1@1+ (1,0) [0|1] "" Vector__XXX
 SG_ USM_a229_crcMismatchInRam m229 : 37|1@1+ (1,0) [0|1] "" Vector__XXX
 SG_ USM_a229_verificationOfConfigAnd m229 : 38|1@1+ (1,0) [0|1] "" Vector__XXX
 SG_ USM_a229_wdgClockFreqOutOfRange m229 : 39|1@1+ (1,0) [0|1] "" Vector__XXX
 SG_ USM_a229_atgNoiseMeasOutOfRange m229 : 40|1@1+ (1,0) [0|1] "" Vector__XXX
 SG_ USM_a229_syncCountError m229 : 41|1@1+ (1,0) [0|1] "" Vector__XXX
 SG_ USM_a229_invalidStartEdge m229 : 42|1@1+ (1,0) [0|1] "" Vector__XXX
 SG_ USM_a229_receiverReachedErrorSta m229 : 43|1@1+ (1,0) [0|1] "" Vector__XXX
 SG_ USM_a229_pdcmPulseInvalid m229 : 44|1@1+ (1,0) [0|1] "" Vector__XXX
 SG_ USM_a229_crcOfReceivedCmdInvalid m229 : 45|1@1+ (1,0) [0|1] "" Vector__XXX
 SG_ USM_a229_passwordWrong m229 : 46|1@1+ (1,0) [0|1] "" Vector__XXX
 SG_ USM_a229_timeIntBetween2PulsesEr m229 : 47|1@1+ (1,0) [0|1] "" Vector__XXX
 SG_ USM_a229_numInvalidStartEdgeSinc m229 : 48|4@1+ (1,0) [0|15] "" Vector__XXX
 SG_ USM_a229_numAtgNoiseErrorsSinceI m229 : 52|4@1+ (1,0) [0|15] "" Vector__XXX
 SG_ USM_a230_reset m230 : 16|1@1+ (1,0) [0|1] "" Vector__XXX
 SG_ USM_a230_otpCrcError m230 : 17|1@1+ (1,0) [0|1] "" Vector__XXX
 SG_ USM_a230_trimRegParityErr m230 : 18|1@1+ (1,0) [0|1] "" Vector__XXX
 SG_ USM_a230_sramParityErr m230 : 19|1@1+ (1,0) [0|1] "" Vector__XXX
 SG_ USM_a230_crcMismatchInOtp m230 : 20|1@1+ (1,0) [0|1] "" Vector__XXX
 SG_ USM_a230_crcMismatchInSysrom m230 : 21|1@1+ (1,0) [0|1] "" Vector__XXX
 SG_ USM_a230_crcMismatchInEeprom m230 : 22|1@1+ (1,0) [0|1] "" Vector__XXX
 SG_ USM_a230_capLossVdddOutOfRange m230 : 23|1@1+ (1,0) [0|1] "" Vector__XXX
 SG_ USM_a230_capLossVddaOutOfRange m230 : 24|1@1+ (1,0) [0|1] "" Vector__XXX
 SG_ USM_a230_referenceVoltOutOfRange m230 : 25|1@1+ (1,0) [0|1] "" Vector__XXX
 SG_ USM_a230_vdddVoltOutOfRange m230 : 26|1@1+ (1,0) [0|1] "" Vector__XXX
 SG_ USM_a230_vrefVoldOfOtpOutOfRange m230 : 27|1@1+ (1,0) [0|1] "" Vector__XXX
 SG_ USM_a230_eepromProgFail m230 : 28|1@1+ (1,0) [0|1] "" Vector__XXX
 SG_ USM_a230_eepromProgBuys m230 : 29|1@1+ (1,0) [0|1] "" Vector__XXX
 SG_ USM_a230_vsupVoltOutOfRange m230 : 30|1@1+ (1,0) [0|1] "" Vector__XXX
 SG_ USM_a230_tempSensOutOfRange m230 : 31|1@1+ (1,0) [0|1] "" Vector__XXX
 SG_ USM_a230_underVoltAtVtankDuringB m230 : 32|1@1+ (1,0) [0|1] "" Vector__XXX
 SG_ USM_a230_overVoltAtVtankDuringBu m230 : 33|1@1+ (1,0) [0|1] "" Vector__XXX
 SG_ USM_a230_drvsFailDuringBurst m230 : 34|1@1+ (1,0) [0|1] "" Vector__XXX
 SG_ USM_a230_drv1FailDuringBurst m230 : 35|1@1+ (1,0) [0|1] "" Vector__XXX
 SG_ USM_a230_drv2FailDuringBurst m230 : 36|1@1+ (1,0) [0|1] "" Vector__XXX
 SG_ USM_a230_crcMismatchInRam m230 : 37|1@1+ (1,0) [0|1] "" Vector__XXX
 SG_ USM_a230_verificationOfConfigAnd m230 : 38|1@1+ (1,0) [0|1] "" Vector__XXX
 SG_ USM_a230_wdgClockFreqOutOfRange m230 : 39|1@1+ (1,0) [0|1] "" Vector__XXX
 SG_ USM_a230_atgNoiseMeasOutOfRange m230 : 40|1@1+ (1,0) [0|1] "" Vector__XXX
 SG_ USM_a230_syncCountError m230 : 41|1@1+ (1,0) [0|1] "" Vector__XXX
 SG_ USM_a230_invalidStartEdge m230 : 42|1@1+ (1,0) [0|1] "" Vector__XXX
 SG_ USM_a230_receiverReachedErrorSta m230 : 43|1@1+ (1,0) [0|1] "" Vector__XXX
 SG_ USM_a230_pdcmPulseInvalid m230 : 44|1@1+ (1,0) [0|1] "" Vector__XXX
 SG_ USM_a230_crcOfReceivedCmdInvalid m230 : 45|1@1+ (1,0) [0|1] "" Vector__XXX
 SG_ USM_a230_passwordWrong m230 : 46|1@1+ (1,0) [0|1] "" Vector__XXX
 SG_ USM_a230_timeIntBetween2PulsesEr m230 : 47|1@1+ (1,0) [0|1] "" Vector__XXX
 SG_ USM_a230_numInvalidStartEdgeSinc m230 : 48|4@1+ (1,0) [0|15] "" Vector__XXX
 SG_ USM_a230_numAtgNoiseErrorsSinceI m230 : 52|4@1+ (1,0) [0|15] "" Vector__XXX
 SG_ USM_a231_reset m231 : 16|1@1+ (1,0) [0|1] "" Vector__XXX
 SG_ USM_a231_otpCrcError m231 : 17|1@1+ (1,0) [0|1] "" Vector__XXX
 SG_ USM_a231_trimRegParityErr m231 : 18|1@1+ (1,0) [0|1] "" Vector__XXX
 SG_ USM_a231_sramParityErr m231 : 19|1@1+ (1,0) [0|1] "" Vector__XXX
 SG_ USM_a231_crcMismatchInOtp m231 : 20|1@1+ (1,0) [0|1] "" Vector__XXX
 SG_ USM_a231_crcMismatchInSysrom m231 : 21|1@1+ (1,0) [0|1] "" Vector__XXX
 SG_ USM_a231_crcMismatchInEeprom m231 : 22|1@1+ (1,0) [0|1] "" Vector__XXX
 SG_ USM_a231_capLossVdddOutOfRange m231 : 23|1@1+ (1,0) [0|1] "" Vector__XXX
 SG_ USM_a231_capLossVddaOutOfRange m231 : 24|1@1+ (1,0) [0|1] "" Vector__XXX
 SG_ USM_a231_referenceVoltOutOfRange m231 : 25|1@1+ (1,0) [0|1] "" Vector__XXX
 SG_ USM_a231_vdddVoltOutOfRange m231 : 26|1@1+ (1,0) [0|1] "" Vector__XXX
 SG_ USM_a231_vrefVoldOfOtpOutOfRange m231 : 27|1@1+ (1,0) [0|1] "" Vector__XXX
 SG_ USM_a231_eepromProgFail m231 : 28|1@1+ (1,0) [0|1] "" Vector__XXX
 SG_ USM_a231_eepromProgBuys m231 : 29|1@1+ (1,0) [0|1] "" Vector__XXX
 SG_ USM_a231_vsupVoltOutOfRange m231 : 30|1@1+ (1,0) [0|1] "" Vector__XXX
 SG_ USM_a231_tempSensOutOfRange m231 : 31|1@1+ (1,0) [0|1] "" Vector__XXX
 SG_ USM_a231_underVoltAtVtankDuringB m231 : 32|1@1+ (1,0) [0|1] "" Vector__XXX
 SG_ USM_a231_overVoltAtVtankDuringBu m231 : 33|1@1+ (1,0) [0|1] "" Vector__XXX
 SG_ USM_a231_drvsFailDuringBurst m231 : 34|1@1+ (1,0) [0|1] "" Vector__XXX
 SG_ USM_a231_drv1FailDuringBurst m231 : 35|1@1+ (1,0) [0|1] "" Vector__XXX
 SG_ USM_a231_drv2FailDuringBurst m231 : 36|1@1+ (1,0) [0|1] "" Vector__XXX
 SG_ USM_a231_crcMismatchInRam m231 : 37|1@1+ (1,0) [0|1] "" Vector__XXX
 SG_ USM_a231_verificationOfConfigAnd m231 : 38|1@1+ (1,0) [0|1] "" Vector__XXX
 SG_ USM_a231_wdgClockFreqOutOfRange m231 : 39|1@1+ (1,0) [0|1] "" Vector__XXX
 SG_ USM_a231_atgNoiseMeasOutOfRange m231 : 40|1@1+ (1,0) [0|1] "" Vector__XXX
 SG_ USM_a231_syncCountError m231 : 41|1@1+ (1,0) [0|1] "" Vector__XXX
 SG_ USM_a231_invalidStartEdge m231 : 42|1@1+ (1,0) [0|1] "" Vector__XXX
 SG_ USM_a231_receiverReachedErrorSta m231 : 43|1@1+ (1,0) [0|1] "" Vector__XXX
 SG_ USM_a231_pdcmPulseInvalid m231 : 44|1@1+ (1,0) [0|1] "" Vector__XXX
 SG_ USM_a231_crcOfReceivedCmdInvalid m231 : 45|1@1+ (1,0) [0|1] "" Vector__XXX
 SG_ USM_a231_passwordWrong m231 : 46|1@1+ (1,0) [0|1] "" Vector__XXX
 SG_ USM_a231_timeIntBetween2PulsesEr m231 : 47|1@1+ (1,0) [0|1] "" Vector__XXX
 SG_ USM_a231_numInvalidStartEdgeSinc m231 : 48|4@1+ (1,0) [0|15] "" Vector__XXX
 SG_ USM_a231_numAtgNoiseErrorsSinceI m231 : 52|4@1+ (1,0) [0|15] "" Vector__XXX
 SG_ USM_a232_reset m232 : 16|1@1+ (1,0) [0|1] "" Vector__XXX
 SG_ USM_a232_otpCrcError m232 : 17|1@1+ (1,0) [0|1] "" Vector__XXX
 SG_ USM_a232_trimRegParityErr m232 : 18|1@1+ (1,0) [0|1] "" Vector__XXX
 SG_ USM_a232_sramParityErr m232 : 19|1@1+ (1,0) [0|1] "" Vector__XXX
 SG_ USM_a232_crcMismatchInOtp m232 : 20|1@1+ (1,0) [0|1] "" Vector__XXX
 SG_ USM_a232_crcMismatchInSysrom m232 : 21|1@1+ (1,0) [0|1] "" Vector__XXX
 SG_ USM_a232_crcMismatchInEeprom m232 : 22|1@1+ (1,0) [0|1] "" Vector__XXX
 SG_ USM_a232_capLossVdddOutOfRange m232 : 23|1@1+ (1,0) [0|1] "" Vector__XXX
 SG_ USM_a232_capLossVddaOutOfRange m232 : 24|1@1+ (1,0) [0|1] "" Vector__XXX
 SG_ USM_a232_referenceVoltOutOfRange m232 : 25|1@1+ (1,0) [0|1] "" Vector__XXX
 SG_ USM_a232_vdddVoltOutOfRange m232 : 26|1@1+ (1,0) [0|1] "" Vector__XXX
 SG_ USM_a232_vrefVoldOfOtpOutOfRange m232 : 27|1@1+ (1,0) [0|1] "" Vector__XXX
 SG_ USM_a232_eepromProgFail m232 : 28|1@1+ (1,0) [0|1] "" Vector__XXX
 SG_ USM_a232_eepromProgBuys m232 : 29|1@1+ (1,0) [0|1] "" Vector__XXX
 SG_ USM_a232_vsupVoltOutOfRange m232 : 30|1@1+ (1,0) [0|1] "" Vector__XXX
 SG_ USM_a232_tempSensOutOfRange m232 : 31|1@1+ (1,0) [0|1] "" Vector__XXX
 SG_ USM_a232_underVoltAtVtankDuringB m232 : 32|1@1+ (1,0) [0|1] "" Vector__XXX
 SG_ USM_a232_overVoltAtVtankDuringBu m232 : 33|1@1+ (1,0) [0|1] "" Vector__XXX
 SG_ USM_a232_drvsFailDuringBurst m232 : 34|1@1+ (1,0) [0|1] "" Vector__XXX
 SG_ USM_a232_drv1FailDuringBurst m232 : 35|1@1+ (1,0) [0|1] "" Vector__XXX
 SG_ USM_a232_drv2FailDuringBurst m232 : 36|1@1+ (1,0) [0|1] "" Vector__XXX
 SG_ USM_a232_crcMismatchInRam m232 : 37|1@1+ (1,0) [0|1] "" Vector__XXX
 SG_ USM_a232_verificationOfConfigAnd m232 : 38|1@1+ (1,0) [0|1] "" Vector__XXX
 SG_ USM_a232_wdgClockFreqOutOfRange m232 : 39|1@1+ (1,0) [0|1] "" Vector__XXX
 SG_ USM_a232_atgNoiseMeasOutOfRange m232 : 40|1@1+ (1,0) [0|1] "" Vector__XXX
 SG_ USM_a232_syncCountError m232 : 41|1@1+ (1,0) [0|1] "" Vector__XXX
 SG_ USM_a232_invalidStartEdge m232 : 42|1@1+ (1,0) [0|1] "" Vector__XXX
 SG_ USM_a232_receiverReachedErrorSta m232 : 43|1@1+ (1,0) [0|1] "" Vector__XXX
 SG_ USM_a232_pdcmPulseInvalid m232 : 44|1@1+ (1,0) [0|1] "" Vector__XXX
 SG_ USM_a232_crcOfReceivedCmdInvalid m232 : 45|1@1+ (1,0) [0|1] "" Vector__XXX
 SG_ USM_a232_passwordWrong m232 : 46|1@1+ (1,0) [0|1] "" Vector__XXX
 SG_ USM_a232_timeIntBetween2PulsesEr m232 : 47|1@1+ (1,0) [0|1] "" Vector__XXX
 SG_ USM_a232_numInvalidStartEdgeSinc m232 : 48|4@1+ (1,0) [0|15] "" Vector__XXX
 SG_ USM_a232_numAtgNoiseErrorsSinceI m232 : 52|4@1+ (1,0) [0|15] "" Vector__XXX
 SG_ USM_a233_reset m233 : 16|1@1+ (1,0) [0|1] "" Vector__XXX
 SG_ USM_a233_otpCrcError m233 : 17|1@1+ (1,0) [0|1] "" Vector__XXX
 SG_ USM_a233_trimRegParityErr m233 : 18|1@1+ (1,0) [0|1] "" Vector__XXX
 SG_ USM_a233_sramParityErr m233 : 19|1@1+ (1,0) [0|1] "" Vector__XXX
 SG_ USM_a233_crcMismatchInOtp m233 : 20|1@1+ (1,0) [0|1] "" Vector__XXX
 SG_ USM_a233_crcMismatchInSysrom m233 : 21|1@1+ (1,0) [0|1] "" Vector__XXX
 SG_ USM_a233_crcMismatchInEeprom m233 : 22|1@1+ (1,0) [0|1] "" Vector__XXX
 SG_ USM_a233_capLossVdddOutOfRange m233 : 23|1@1+ (1,0) [0|1] "" Vector__XXX
 SG_ USM_a233_capLossVddaOutOfRange m233 : 24|1@1+ (1,0) [0|1] "" Vector__XXX
 SG_ USM_a233_referenceVoltOutOfRange m233 : 25|1@1+ (1,0) [0|1] "" Vector__XXX
 SG_ USM_a233_vdddVoltOutOfRange m233 : 26|1@1+ (1,0) [0|1] "" Vector__XXX
 SG_ USM_a233_vrefVoldOfOtpOutOfRange m233 : 27|1@1+ (1,0) [0|1] "" Vector__XXX
 SG_ USM_a233_eepromProgFail m233 : 28|1@1+ (1,0) [0|1] "" Vector__XXX
 SG_ USM_a233_eepromProgBuys m233 : 29|1@1+ (1,0) [0|1] "" Vector__XXX
 SG_ USM_a233_vsupVoltOutOfRange m233 : 30|1@1+ (1,0) [0|1] "" Vector__XXX
 SG_ USM_a233_tempSensOutOfRange m233 : 31|1@1+ (1,0) [0|1] "" Vector__XXX
 SG_ USM_a233_underVoltAtVtankDuringB m233 : 32|1@1+ (1,0) [0|1] "" Vector__XXX
 SG_ USM_a233_overVoltAtVtankDuringBu m233 : 33|1@1+ (1,0) [0|1] "" Vector__XXX
 SG_ USM_a233_drvsFailDuringBurst m233 : 34|1@1+ (1,0) [0|1] "" Vector__XXX
 SG_ USM_a233_drv1FailDuringBurst m233 : 35|1@1+ (1,0) [0|1] "" Vector__XXX
 SG_ USM_a233_drv2FailDuringBurst m233 : 36|1@1+ (1,0) [0|1] "" Vector__XXX
 SG_ USM_a233_crcMismatchInRam m233 : 37|1@1+ (1,0) [0|1] "" Vector__XXX
 SG_ USM_a233_verificationOfConfigAnd m233 : 38|1@1+ (1,0) [0|1] "" Vector__XXX
 SG_ USM_a233_wdgClockFreqOutOfRange m233 : 39|1@1+ (1,0) [0|1] "" Vector__XXX
 SG_ USM_a233_atgNoiseMeasOutOfRange m233 : 40|1@1+ (1,0) [0|1] "" Vector__XXX
 SG_ USM_a233_syncCountError m233 : 41|1@1+ (1,0) [0|1] "" Vector__XXX
 SG_ USM_a233_invalidStartEdge m233 : 42|1@1+ (1,0) [0|1] "" Vector__XXX
 SG_ USM_a233_receiverReachedErrorSta m233 : 43|1@1+ (1,0) [0|1] "" Vector__XXX
 SG_ USM_a233_pdcmPulseInvalid m233 : 44|1@1+ (1,0) [0|1] "" Vector__XXX
 SG_ USM_a233_crcOfReceivedCmdInvalid m233 : 45|1@1+ (1,0) [0|1] "" Vector__XXX
 SG_ USM_a233_passwordWrong m233 : 46|1@1+ (1,0) [0|1] "" Vector__XXX
 SG_ USM_a233_timeIntBetween2PulsesEr m233 : 47|1@1+ (1,0) [0|1] "" Vector__XXX
 SG_ USM_a233_numInvalidStartEdgeSinc m233 : 48|4@1+ (1,0) [0|15] "" Vector__XXX
 SG_ USM_a233_numAtgNoiseErrorsSinceI m233 : 52|4@1+ (1,0) [0|15] "" Vector__XXX
 SG_ USM_a234_reset m234 : 16|1@1+ (1,0) [0|1] "" Vector__XXX
 SG_ USM_a234_otpCrcError m234 : 17|1@1+ (1,0) [0|1] "" Vector__XXX
 SG_ USM_a234_trimRegParityErr m234 : 18|1@1+ (1,0) [0|1] "" Vector__XXX
 SG_ USM_a234_sramParityErr m234 : 19|1@1+ (1,0) [0|1] "" Vector__XXX
 SG_ USM_a234_crcMismatchInOtp m234 : 20|1@1+ (1,0) [0|1] "" Vector__XXX
 SG_ USM_a234_crcMismatchInSysrom m234 : 21|1@1+ (1,0) [0|1] "" Vector__XXX
 SG_ USM_a234_crcMismatchInEeprom m234 : 22|1@1+ (1,0) [0|1] "" Vector__XXX
 SG_ USM_a234_capLossVdddOutOfRange m234 : 23|1@1+ (1,0) [0|1] "" Vector__XXX
 SG_ USM_a234_capLossVddaOutOfRange m234 : 24|1@1+ (1,0) [0|1] "" Vector__XXX
 SG_ USM_a234_referenceVoltOutOfRange m234 : 25|1@1+ (1,0) [0|1] "" Vector__XXX
 SG_ USM_a234_vdddVoltOutOfRange m234 : 26|1@1+ (1,0) [0|1] "" Vector__XXX
 SG_ USM_a234_vrefVoldOfOtpOutOfRange m234 : 27|1@1+ (1,0) [0|1] "" Vector__XXX
 SG_ USM_a234_eepromProgFail m234 : 28|1@1+ (1,0) [0|1] "" Vector__XXX
 SG_ USM_a234_eepromProgBuys m234 : 29|1@1+ (1,0) [0|1] "" Vector__XXX
 SG_ USM_a234_vsupVoltOutOfRange m234 : 30|1@1+ (1,0) [0|1] "" Vector__XXX
 SG_ USM_a234_tempSensOutOfRange m234 : 31|1@1+ (1,0) [0|1] "" Vector__XXX
 SG_ USM_a234_underVoltAtVtankDuringB m234 : 32|1@1+ (1,0) [0|1] "" Vector__XXX
 SG_ USM_a234_overVoltAtVtankDuringBu m234 : 33|1@1+ (1,0) [0|1] "" Vector__XXX
 SG_ USM_a234_drvsFailDuringBurst m234 : 34|1@1+ (1,0) [0|1] "" Vector__XXX
 SG_ USM_a234_drv1FailDuringBurst m234 : 35|1@1+ (1,0) [0|1] "" Vector__XXX
 SG_ USM_a234_drv2FailDuringBurst m234 : 36|1@1+ (1,0) [0|1] "" Vector__XXX
 SG_ USM_a234_crcMismatchInRam m234 : 37|1@1+ (1,0) [0|1] "" Vector__XXX
 SG_ USM_a234_verificationOfConfigAnd m234 : 38|1@1+ (1,0) [0|1] "" Vector__XXX
 SG_ USM_a234_wdgClockFreqOutOfRange m234 : 39|1@1+ (1,0) [0|1] "" Vector__XXX
 SG_ USM_a234_atgNoiseMeasOutOfRange m234 : 40|1@1+ (1,0) [0|1] "" Vector__XXX
 SG_ USM_a234_syncCountError m234 : 41|1@1+ (1,0) [0|1] "" Vector__XXX
 SG_ USM_a234_invalidStartEdge m234 : 42|1@1+ (1,0) [0|1] "" Vector__XXX
 SG_ USM_a234_receiverReachedErrorSta m234 : 43|1@1+ (1,0) [0|1] "" Vector__XXX
 SG_ USM_a234_pdcmPulseInvalid m234 : 44|1@1+ (1,0) [0|1] "" Vector__XXX
 SG_ USM_a234_crcOfReceivedCmdInvalid m234 : 45|1@1+ (1,0) [0|1] "" Vector__XXX
 SG_ USM_a234_passwordWrong m234 : 46|1@1+ (1,0) [0|1] "" Vector__XXX
 SG_ USM_a234_timeIntBetween2PulsesEr m234 : 47|1@1+ (1,0) [0|1] "" Vector__XXX
 SG_ USM_a234_numInvalidStartEdgeSinc m234 : 48|4@1+ (1,0) [0|15] "" Vector__XXX
 SG_ USM_a234_numAtgNoiseErrorsSinceI m234 : 52|4@1+ (1,0) [0|15] "" Vector__XXX
 SG_ USM_a235_reset m235 : 16|1@1+ (1,0) [0|1] "" Vector__XXX
 SG_ USM_a235_otpCrcError m235 : 17|1@1+ (1,0) [0|1] "" Vector__XXX
 SG_ USM_a235_trimRegParityErr m235 : 18|1@1+ (1,0) [0|1] "" Vector__XXX
 SG_ USM_a235_sramParityErr m235 : 19|1@1+ (1,0) [0|1] "" Vector__XXX
 SG_ USM_a235_crcMismatchInOtp m235 : 20|1@1+ (1,0) [0|1] "" Vector__XXX
 SG_ USM_a235_crcMismatchInSysrom m235 : 21|1@1+ (1,0) [0|1] "" Vector__XXX
 SG_ USM_a235_crcMismatchInEeprom m235 : 22|1@1+ (1,0) [0|1] "" Vector__XXX
 SG_ USM_a235_capLossVdddOutOfRange m235 : 23|1@1+ (1,0) [0|1] "" Vector__XXX
 SG_ USM_a235_capLossVddaOutOfRange m235 : 24|1@1+ (1,0) [0|1] "" Vector__XXX
 SG_ USM_a235_referenceVoltOutOfRange m235 : 25|1@1+ (1,0) [0|1] "" Vector__XXX
 SG_ USM_a235_vdddVoltOutOfRange m235 : 26|1@1+ (1,0) [0|1] "" Vector__XXX
 SG_ USM_a235_vrefVoldOfOtpOutOfRange m235 : 27|1@1+ (1,0) [0|1] "" Vector__XXX
 SG_ USM_a235_eepromProgFail m235 : 28|1@1+ (1,0) [0|1] "" Vector__XXX
 SG_ USM_a235_eepromProgBuys m235 : 29|1@1+ (1,0) [0|1] "" Vector__XXX
 SG_ USM_a235_vsupVoltOutOfRange m235 : 30|1@1+ (1,0) [0|1] "" Vector__XXX
 SG_ USM_a235_tempSensOutOfRange m235 : 31|1@1+ (1,0) [0|1] "" Vector__XXX
 SG_ USM_a235_underVoltAtVtankDuringB m235 : 32|1@1+ (1,0) [0|1] "" Vector__XXX
 SG_ USM_a235_overVoltAtVtankDuringBu m235 : 33|1@1+ (1,0) [0|1] "" Vector__XXX
 SG_ USM_a235_drvsFailDuringBurst m235 : 34|1@1+ (1,0) [0|1] "" Vector__XXX
 SG_ USM_a235_drv1FailDuringBurst m235 : 35|1@1+ (1,0) [0|1] "" Vector__XXX
 SG_ USM_a235_drv2FailDuringBurst m235 : 36|1@1+ (1,0) [0|1] "" Vector__XXX
 SG_ USM_a235_crcMismatchInRam m235 : 37|1@1+ (1,0) [0|1] "" Vector__XXX
 SG_ USM_a235_verificationOfConfigAnd m235 : 38|1@1+ (1,0) [0|1] "" Vector__XXX
 SG_ USM_a235_wdgClockFreqOutOfRange m235 : 39|1@1+ (1,0) [0|1] "" Vector__XXX
 SG_ USM_a235_atgNoiseMeasOutOfRange m235 : 40|1@1+ (1,0) [0|1] "" Vector__XXX
 SG_ USM_a235_syncCountError m235 : 41|1@1+ (1,0) [0|1] "" Vector__XXX
 SG_ USM_a235_invalidStartEdge m235 : 42|1@1+ (1,0) [0|1] "" Vector__XXX
 SG_ USM_a235_receiverReachedErrorSta m235 : 43|1@1+ (1,0) [0|1] "" Vector__XXX
 SG_ USM_a235_pdcmPulseInvalid m235 : 44|1@1+ (1,0) [0|1] "" Vector__XXX
 SG_ USM_a235_crcOfReceivedCmdInvalid m235 : 45|1@1+ (1,0) [0|1] "" Vector__XXX
 SG_ USM_a235_passwordWrong m235 : 46|1@1+ (1,0) [0|1] "" Vector__XXX
 SG_ USM_a235_timeIntBetween2PulsesEr m235 : 47|1@1+ (1,0) [0|1] "" Vector__XXX
 SG_ USM_a235_numInvalidStartEdgeSinc m235 : 48|4@1+ (1,0) [0|15] "" Vector__XXX
 SG_ USM_a235_numAtgNoiseErrorsSinceI m235 : 52|4@1+ (1,0) [0|15] "" Vector__XXX
 SG_ USM_a236_reset m236 : 16|1@1+ (1,0) [0|1] "" Vector__XXX
 SG_ USM_a236_otpCrcError m236 : 17|1@1+ (1,0) [0|1] "" Vector__XXX
 SG_ USM_a236_trimRegParityErr m236 : 18|1@1+ (1,0) [0|1] "" Vector__XXX
 SG_ USM_a236_sramParityErr m236 : 19|1@1+ (1,0) [0|1] "" Vector__XXX
 SG_ USM_a236_crcMismatchInOtp m236 : 20|1@1+ (1,0) [0|1] "" Vector__XXX
 SG_ USM_a236_crcMismatchInSysrom m236 : 21|1@1+ (1,0) [0|1] "" Vector__XXX
 SG_ USM_a236_crcMismatchInEeprom m236 : 22|1@1+ (1,0) [0|1] "" Vector__XXX
 SG_ USM_a236_capLossVdddOutOfRange m236 : 23|1@1+ (1,0) [0|1] "" Vector__XXX
 SG_ USM_a236_capLossVddaOutOfRange m236 : 24|1@1+ (1,0) [0|1] "" Vector__XXX
 SG_ USM_a236_referenceVoltOutOfRange m236 : 25|1@1+ (1,0) [0|1] "" Vector__XXX
 SG_ USM_a236_vdddVoltOutOfRange m236 : 26|1@1+ (1,0) [0|1] "" Vector__XXX
 SG_ USM_a236_vrefVoldOfOtpOutOfRange m236 : 27|1@1+ (1,0) [0|1] "" Vector__XXX
 SG_ USM_a236_eepromProgFail m236 : 28|1@1+ (1,0) [0|1] "" Vector__XXX
 SG_ USM_a236_eepromProgBuys m236 : 29|1@1+ (1,0) [0|1] "" Vector__XXX
 SG_ USM_a236_vsupVoltOutOfRange m236 : 30|1@1+ (1,0) [0|1] "" Vector__XXX
 SG_ USM_a236_tempSensOutOfRange m236 : 31|1@1+ (1,0) [0|1] "" Vector__XXX
 SG_ USM_a236_underVoltAtVtankDuringB m236 : 32|1@1+ (1,0) [0|1] "" Vector__XXX
 SG_ USM_a236_overVoltAtVtankDuringBu m236 : 33|1@1+ (1,0) [0|1] "" Vector__XXX
 SG_ USM_a236_drvsFailDuringBurst m236 : 34|1@1+ (1,0) [0|1] "" Vector__XXX
 SG_ USM_a236_drv1FailDuringBurst m236 : 35|1@1+ (1,0) [0|1] "" Vector__XXX
 SG_ USM_a236_drv2FailDuringBurst m236 : 36|1@1+ (1,0) [0|1] "" Vector__XXX
 SG_ USM_a236_crcMismatchInRam m236 : 37|1@1+ (1,0) [0|1] "" Vector__XXX
 SG_ USM_a236_verificationOfConfigAnd m236 : 38|1@1+ (1,0) [0|1] "" Vector__XXX
 SG_ USM_a236_wdgClockFreqOutOfRange m236 : 39|1@1+ (1,0) [0|1] "" Vector__XXX
 SG_ USM_a236_atgNoiseMeasOutOfRange m236 : 40|1@1+ (1,0) [0|1] "" Vector__XXX
 SG_ USM_a236_syncCountError m236 : 41|1@1+ (1,0) [0|1] "" Vector__XXX
 SG_ USM_a236_invalidStartEdge m236 : 42|1@1+ (1,0) [0|1] "" Vector__XXX
 SG_ USM_a236_receiverReachedErrorSta m236 : 43|1@1+ (1,0) [0|1] "" Vector__XXX
 SG_ USM_a236_pdcmPulseInvalid m236 : 44|1@1+ (1,0) [0|1] "" Vector__XXX
 SG_ USM_a236_crcOfReceivedCmdInvalid m236 : 45|1@1+ (1,0) [0|1] "" Vector__XXX
 SG_ USM_a236_passwordWrong m236 : 46|1@1+ (1,0) [0|1] "" Vector__XXX
 SG_ USM_a236_timeIntBetween2PulsesEr m236 : 47|1@1+ (1,0) [0|1] "" Vector__XXX
 SG_ USM_a236_numInvalidStartEdgeSinc m236 : 48|4@1+ (1,0) [0|15] "" Vector__XXX
 SG_ USM_a236_numAtgNoiseErrorsSinceI m236 : 52|4@1+ (1,0) [0|15] "" Vector__XXX
 SG_ USM_a237_reset m237 : 16|1@1+ (1,0) [0|1] "" Vector__XXX
 SG_ USM_a237_otpCrcError m237 : 17|1@1+ (1,0) [0|1] "" Vector__XXX
 SG_ USM_a237_trimRegParityErr m237 : 18|1@1+ (1,0) [0|1] "" Vector__XXX
 SG_ USM_a237_sramParityErr m237 : 19|1@1+ (1,0) [0|1] "" Vector__XXX
 SG_ USM_a237_crcMismatchInOtp m237 : 20|1@1+ (1,0) [0|1] "" Vector__XXX
 SG_ USM_a237_crcMismatchInSysrom m237 : 21|1@1+ (1,0) [0|1] "" Vector__XXX
 SG_ USM_a237_crcMismatchInEeprom m237 : 22|1@1+ (1,0) [0|1] "" Vector__XXX
 SG_ USM_a237_capLossVdddOutOfRange m237 : 23|1@1+ (1,0) [0|1] "" Vector__XXX
 SG_ USM_a237_capLossVddaOutOfRange m237 : 24|1@1+ (1,0) [0|1] "" Vector__XXX
 SG_ USM_a237_referenceVoltOutOfRange m237 : 25|1@1+ (1,0) [0|1] "" Vector__XXX
 SG_ USM_a237_vdddVoltOutOfRange m237 : 26|1@1+ (1,0) [0|1] "" Vector__XXX
 SG_ USM_a237_vrefVoldOfOtpOutOfRange m237 : 27|1@1+ (1,0) [0|1] "" Vector__XXX
 SG_ USM_a237_eepromProgFail m237 : 28|1@1+ (1,0) [0|1] "" Vector__XXX
 SG_ USM_a237_eepromProgBuys m237 : 29|1@1+ (1,0) [0|1] "" Vector__XXX
 SG_ USM_a237_vsupVoltOutOfRange m237 : 30|1@1+ (1,0) [0|1] "" Vector__XXX
 SG_ USM_a237_tempSensOutOfRange m237 : 31|1@1+ (1,0) [0|1] "" Vector__XXX
 SG_ USM_a237_underVoltAtVtankDuringB m237 : 32|1@1+ (1,0) [0|1] "" Vector__XXX
 SG_ USM_a237_overVoltAtVtankDuringBu m237 : 33|1@1+ (1,0) [0|1] "" Vector__XXX
 SG_ USM_a237_drvsFailDuringBurst m237 : 34|1@1+ (1,0) [0|1] "" Vector__XXX
 SG_ USM_a237_drv1FailDuringBurst m237 : 35|1@1+ (1,0) [0|1] "" Vector__XXX
 SG_ USM_a237_drv2FailDuringBurst m237 : 36|1@1+ (1,0) [0|1] "" Vector__XXX
 SG_ USM_a237_crcMismatchInRam m237 : 37|1@1+ (1,0) [0|1] "" Vector__XXX
 SG_ USM_a237_verificationOfConfigAnd m237 : 38|1@1+ (1,0) [0|1] "" Vector__XXX
 SG_ USM_a237_wdgClockFreqOutOfRange m237 : 39|1@1+ (1,0) [0|1] "" Vector__XXX
 SG_ USM_a237_atgNoiseMeasOutOfRange m237 : 40|1@1+ (1,0) [0|1] "" Vector__XXX
 SG_ USM_a237_syncCountError m237 : 41|1@1+ (1,0) [0|1] "" Vector__XXX
 SG_ USM_a237_invalidStartEdge m237 : 42|1@1+ (1,0) [0|1] "" Vector__XXX
 SG_ USM_a237_receiverReachedErrorSta m237 : 43|1@1+ (1,0) [0|1] "" Vector__XXX
 SG_ USM_a237_pdcmPulseInvalid m237 : 44|1@1+ (1,0) [0|1] "" Vector__XXX
 SG_ USM_a237_crcOfReceivedCmdInvalid m237 : 45|1@1+ (1,0) [0|1] "" Vector__XXX
 SG_ USM_a237_passwordWrong m237 : 46|1@1+ (1,0) [0|1] "" Vector__XXX
 SG_ USM_a237_timeIntBetween2PulsesEr m237 : 47|1@1+ (1,0) [0|1] "" Vector__XXX
 SG_ USM_a237_numInvalidStartEdgeSinc m237 : 48|4@1+ (1,0) [0|15] "" Vector__XXX
 SG_ USM_a237_numAtgNoiseErrorsSinceI m237 : 52|4@1+ (1,0) [0|15] "" Vector__XXX
 SG_ USM_a238_reset m238 : 16|1@1+ (1,0) [0|1] "" Vector__XXX
 SG_ USM_a238_otpCrcError m238 : 17|1@1+ (1,0) [0|1] "" Vector__XXX
 SG_ USM_a238_trimRegParityErr m238 : 18|1@1+ (1,0) [0|1] "" Vector__XXX
 SG_ USM_a238_sramParityErr m238 : 19|1@1+ (1,0) [0|1] "" Vector__XXX
 SG_ USM_a238_crcMismatchInOtp m238 : 20|1@1+ (1,0) [0|1] "" Vector__XXX
 SG_ USM_a238_crcMismatchInSysrom m238 : 21|1@1+ (1,0) [0|1] "" Vector__XXX
 SG_ USM_a238_crcMismatchInEeprom m238 : 22|1@1+ (1,0) [0|1] "" Vector__XXX
 SG_ USM_a238_capLossVdddOutOfRange m238 : 23|1@1+ (1,0) [0|1] "" Vector__XXX
 SG_ USM_a238_capLossVddaOutOfRange m238 : 24|1@1+ (1,0) [0|1] "" Vector__XXX
 SG_ USM_a238_referenceVoltOutOfRange m238 : 25|1@1+ (1,0) [0|1] "" Vector__XXX
 SG_ USM_a238_vdddVoltOutOfRange m238 : 26|1@1+ (1,0) [0|1] "" Vector__XXX
 SG_ USM_a238_vrefVoldOfOtpOutOfRange m238 : 27|1@1+ (1,0) [0|1] "" Vector__XXX
 SG_ USM_a238_eepromProgFail m238 : 28|1@1+ (1,0) [0|1] "" Vector__XXX
 SG_ USM_a238_eepromProgBuys m238 : 29|1@1+ (1,0) [0|1] "" Vector__XXX
 SG_ USM_a238_vsupVoltOutOfRange m238 : 30|1@1+ (1,0) [0|1] "" Vector__XXX
 SG_ USM_a238_tempSensOutOfRange m238 : 31|1@1+ (1,0) [0|1] "" Vector__XXX
 SG_ USM_a238_underVoltAtVtankDuringB m238 : 32|1@1+ (1,0) [0|1] "" Vector__XXX
 SG_ USM_a238_overVoltAtVtankDuringBu m238 : 33|1@1+ (1,0) [0|1] "" Vector__XXX
 SG_ USM_a238_drvsFailDuringBurst m238 : 34|1@1+ (1,0) [0|1] "" Vector__XXX
 SG_ USM_a238_drv1FailDuringBurst m238 : 35|1@1+ (1,0) [0|1] "" Vector__XXX
 SG_ USM_a238_drv2FailDuringBurst m238 : 36|1@1+ (1,0) [0|1] "" Vector__XXX
 SG_ USM_a238_crcMismatchInRam m238 : 37|1@1+ (1,0) [0|1] "" Vector__XXX
 SG_ USM_a238_verificationOfConfigAnd m238 : 38|1@1+ (1,0) [0|1] "" Vector__XXX
 SG_ USM_a238_wdgClockFreqOutOfRange m238 : 39|1@1+ (1,0) [0|1] "" Vector__XXX
 SG_ USM_a238_atgNoiseMeasOutOfRange m238 : 40|1@1+ (1,0) [0|1] "" Vector__XXX
 SG_ USM_a238_syncCountError m238 : 41|1@1+ (1,0) [0|1] "" Vector__XXX
 SG_ USM_a238_invalidStartEdge m238 : 42|1@1+ (1,0) [0|1] "" Vector__XXX
 SG_ USM_a238_receiverReachedErrorSta m238 : 43|1@1+ (1,0) [0|1] "" Vector__XXX
 SG_ USM_a238_pdcmPulseInvalid m238 : 44|1@1+ (1,0) [0|1] "" Vector__XXX
 SG_ USM_a238_crcOfReceivedCmdInvalid m238 : 45|1@1+ (1,0) [0|1] "" Vector__XXX
 SG_ USM_a238_passwordWrong m238 : 46|1@1+ (1,0) [0|1] "" Vector__XXX
 SG_ USM_a238_timeIntBetween2PulsesEr m238 : 47|1@1+ (1,0) [0|1] "" Vector__XXX
 SG_ USM_a238_numInvalidStartEdgeSinc m238 : 48|4@1+ (1,0) [0|15] "" Vector__XXX
 SG_ USM_a238_numAtgNoiseErrorsSinceI m238 : 52|4@1+ (1,0) [0|15] "" Vector__XXX

BO_ 609 VCFRONT_12VBatteryStatus: 8 VCFRONT
 SG_ VCFRONT_12VBatteryStatusIndex M : 0|3@1+ (1,0) [0|7] "" Vector__XXX
 SG_ VCFRONT_good12VforUpdate : 46|1@1+ (1,0) [0|1] "" Vector__XXX
 SG_ VCFRONT_LVLoadRequest : 47|1@1+ (1,0) [0|1] "" Vector__XXX
 SG_ VCFRONT_12VBatteryStatusCounter : 52|4@1+ (1,0) [0|15] "" Vector__XXX
 SG_ VCFRONT_12VBatteryStatusChecksum : 56|8@1+ (1,0) [0|255] "" Vector__XXX
 SG_ VCFRONT_batterySupportRequest m1 : 3|1@1+ (1,0) [0|1] "" Vector__XXX
 SG_ VCFRONT_batterySMState m1 : 4|4@1+ (1,0) [0|15] "" Vector__XXX
 SG_ VCFRONT_eFuseRecoveryStateDBG m1 : 8|3@1+ (1,0) [0|7] "" Vector__XXX
 SG_ VCFRONT_batteryLINScheduleDBG m1 : 11|3@1+ (1,0) [0|6] "" Vector__XXX
 SG_ VCFRONT_resistanceEstimationTest m1 : 14|2@1+ (1,0) [0|3] "" Vector__XXX
 SG_ VCFRONT_IBSCurrent m1 : 16|16@1- (0.005,0) [-163.84|163.835] "A" Vector__XXX
 SG_ VCFRONT_IBSVoltage m1 : 32|14@1+ (0.005443676,0) [0|65.535] "V" Vector__XXX
 SG_ VCFRONT_reverseBatteryFault m1 : 48|1@1+ (1,0) [0|1] "" Vector__XXX
 SG_ VCFRONT_LVBatterySupported m1 : 49|1@1+ (1,0) [0|1] "" Vector__XXX
 SG_ VCFRONT_LVBatteryCannotSupportVe m1 : 50|1@1+ (1,0) [0|1] "" Vector__XXX
 SG_ VCFRONT_goodTemp12VforUpdate m1 : 51|1@1+ (1,0) [0|1] "" Vector__XXX
 SG_ VCFRONT_12VBatteryTargetVoltage m2 : 3|13@1+ (0.01,0) [0|65.535] "V" Vector__XXX
 SG_ VCFRONT_IBSTemperature m2 : 16|11@1+ (0.1,-24) [-24|124] "degC" Vector__XXX
 SG_ VCFRONT_currentSensorMismatchLea m2 : 27|7@1+ (2,0) [0|254] "PCT" Vector__XXX
 SG_ VCFRONT_LVBatteryEnergyRemaining m2 : 37|7@1+ (1,0) [0|127] "%" Vector__XXX
 SG_ VCFRONT_LVBatteryStatusForDrive m2 : 44|2@1+ (1,0) [0|3] "" Vector__XXX
 SG_ VCFRONT_LVBatteryType m2 : 48|3@1+ (1,0) [0|7] "" Vector__XXX
 SG_ VCFRONT_resistanceEstimationNeed m2 : 51|1@1+ (1,0) [0|1] "" Vector__XXX
 SG_ VCFRONT_IBSVoltageFiltered m3 : 3|14@1+ (0.005443676,0) [0|65.535] "V" Vector__XXX
 SG_ VCFRONT_LVBMS_LVBusVoltageSource m3 : 17|2@1+ (1,0) [0|3] "" Vector__XXX
 SG_ VCFRONT_LVBMS_LVPackCurrentSourc m3 : 19|2@1+ (1,0) [0|3] "" Vector__XXX
 SG_ VCFRONT_LVBatterySupportRqrdTrig m3 : 24|14@1+ (1,0) [0|16383] "" Vector__XXX
 SG_ VCFRONT_goodForPCSPowerCycleLeak m3 : 40|5@1+ (0.0005,0) [0|0.0155] "Ah" Vector__XXX
 SG_ VCFRONT_LVBusControlsFutile m3 : 45|1@1+ (1,0) [0|1] "" Vector__XXX
 SG_ VCFRONT_resistanceEstimatio_0001 m3 : 48|1@1+ (1,0) [0|1] "" Vector__XXX
 SG_ VCFRONT_resistanceEstimatio_0002 m3 : 49|1@1+ (1,0) [0|1] "" Vector__XXX
 SG_ VCFRONT_goodLVChargeForUpdate m3 : 50|1@1+ (1,0) [0|1] "" Vector__XXX
 SG_ VCFRONT_opportunisticDCRTestNeed m3 : 51|1@1+ (1,0) [0|1] "" Vector__XXX
 SG_ VCFRONT_voltageProfile m4 : 3|2@1+ (1,0) [0|3] "" Vector__XXX
 SG_ VCFRONT_IBSAmpHours m4 : 5|14@1- (0.005,0) [-40.96|40.955] "Ah" Vector__XXX
 SG_ VCFRONT_IBSVoltageRawDBG m4 : 19|14@1+ (0.005443676,0) [0|65.535] "V" Vector__XXX
 SG_ VCFRONT_LVBatteryLINCommsDetecte m4 : 33|1@1+ (1,0) [0|1] "" Vector__XXX
 SG_ VCFRONT_voltageSensorMismatchLea m4 : 34|7@1+ (2,0) [0|254] "PCT" Vector__XXX
 SG_ VCFRONT_LVBatteryFctryLimOverrid m4 : 50|1@1+ (1,0) [0|1] "" Vector__XXX
 SG_ VCFRONT_LVBatterySPICommsDetecte m4 : 51|1@1+ (1,0) [0|1] "" Vector__XXX
 SG_ VCFRONT_targetCurrent m5 : 3|11@1+ (0.125,-127) [0|120] "A" Vector__XXX
 SG_ VCFRONT_PCSMia m5 : 14|1@1+ (1,0) [0|1] "" Vector__XXX
 SG_ VCFRONT_chargeNeeded m5 : 15|1@1+ (1,0) [0|1] "" Vector__XXX
 SG_ VCFRONT_voltageControlLoopIntegr m5 : 16|14@1+ (0.006,0) [0|65.535] "V" Vector__XXX
 SG_ VCFRONT_currentControlLoopIntegr m5 : 30|14@1+ (0.006,0) [0|65.535] "V" Vector__XXX

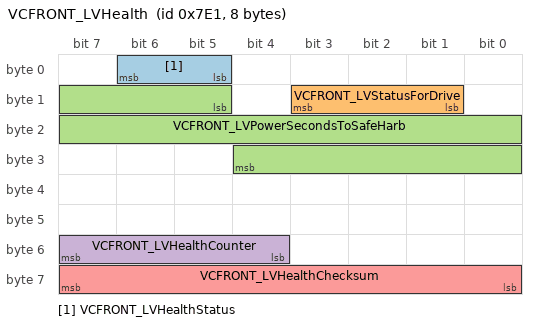
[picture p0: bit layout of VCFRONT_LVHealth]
BO_ 2017 VCFRONT_LVHealth: 8 VCFRONT
 SG_ VCFRONT_LVHealthStatus : 5|2@1+ (1,0) [0|3] "" Vector__XXX
 SG_ VCFRONT_LVStatusForDrive : 9|3@1+ (1,0) [0|7] "" Vector__XXX
 SG_ VCFRONT_LVPowerSecondsToSafeHarb : 13|16@1+ (1,0) [0|65535] "" Vector__XXX
 SG_ VCFRONT_LVHealthCounter : 52|4@1+ (1,0) [0|15] "" Vector__XXX
 SG_ VCFRONT_LVHealthChecksum : 56|8@1+ (1,0) [0|255] "" Vector__XXX

BO_TX_BU_ 1520 : USM;
BO_TX_BU_ 609 : VCFRONT;
BO_TX_BU_ 2017 : VCFRONT;
CM_ BO_ 1520 "USM ECU message: alert log";
CM_ SG_ 1520 USM_alertID "USM ECU: alert ID";
CM_ SG_ 1520 USM_alertState "USM ECU: alert state";
CM_ SG_ 1520 USM_a001_InternalWatchdog "USM ECU: a001 internal watchdog";
CM_ SG_ 1520 USM_a002_CPUUndervoltage "USM ECU: a002 CPU undervoltage";
CM_ SG_ 1520 USM_a002_PowerOnReset "USM ECU: a002 power on reset";
CM_ SG_ 1520 USM_a015_NVMMMemOverflow "USM ECU: a015 NVMM mem overflow";
CM_ SG_ 1520 USM_a015_NVMMFilesystemError "USM ECU: a015 NVMM filesystem error";
CM_ SG_ 1520 USM_a015_NVMMRecordIDError "USM ECU: a015 NVMM record ID error";
CM_ SG_ 1520 USM_a057_VEH_cpControl "USM ECU: a057 VEH cp control";
CM_ SG_ 1520 USM_a059_voltageDrop "USM ECU: a059 voltage drop";
CM_ SG_ 1520 USM_a059_resistanceEstimate "USM ECU: a059 resistance estimate";
CM_ SG_ 1520 USM_a059_current "USM ECU: a059 current";
CM_ SG_ 1520 USM_a063_switchChannel "USM ECU: a063 switch channel";
CM_ SG_ 1520 USM_a063_switchType "USM ECU: a063 switch type";
CM_ SG_ 1520 USM_a063_ADCVoltage "USM ECU: a063 ADC voltage";
CM_ SG_ 1520 USM_a063_disconnected "USM ECU: a063 disconnected";
CM_ SG_ 1520 USM_a063_indeterminate "USM ECU: a063 indeterminate";
CM_ SG_ 1520 USM_a063_stuckActive "USM ECU: a063 stuck active";
CM_ SG_ 1520 USM_a063_faulted "USM ECU: a063 faulted";
CM_ SG_ 1520 USM_a082_RIPC_epbPrivateState "USM ECU: a082 RIPC epb private state";
CM_ SG_ 1520 USM_a082_RIPC_remoteHSD "USM ECU: a082 RIPC remote HSD";
CM_ SG_ 1520 USM_a082_RIPC_railStatus "USM ECU: a082 RIPC rail status";
CM_ SG_ 1520 USM_a082_RIPC_remoteMux "USM ECU: a082 RIPC remote mux";
CM_ SG_ 1520 USM_a083_LIPC_epbPrivateState "USM ECU: a083 LIPC epb private state";
CM_ SG_ 1520 USM_a083_LIPC_remoteHSD "USM ECU: a083 LIPC remote HSD";
CM_ SG_ 1520 USM_a083_LIPC_railStatus "USM ECU: a083 LIPC rail status";
CM_ SG_ 1520 USM_a083_LIPC_HSDFaults "USM ECU: a083 LIPC HSD faults";
CM_ SG_ 1520 USM_a084_CH_StatusC "USM ECU: a084 CH status c";
CM_ SG_ 1520 USM_a085_PARTY_buttonStatus "USM ECU: a085 PARTY button status";
CM_ SG_ 1520 USM_a086_VEH_LVBMS_statusHigh "USM ECU: a086 VEH LVBMS status high";
CM_ SG_ 1520 USM_a086_VEH_LVBMS_statusLow "USM ECU: a086 VEH LVBMS status low";
CM_ SG_ 1520 USM_a086_VEH_status "USM ECU: a086 VEH status";
CM_ SG_ 1520 USM_a086_VEH_12VBatteryStatus "USM ECU: a086 VEH 12 v battery status";
CM_ SG_ 1520 USM_a086_VEH_LVPowerState "USM ECU: a086 VEH LV power state";
CM_ SG_ 1520 USM_a086_VEH_lightStatus "USM ECU: a086 VEH light status";
CM_ SG_ 1520 USM_a086_VEH_systemStatus "USM ECU: a086 VEH system status";
CM_ SG_ 1520 USM_a086_VEH_thermalStatus "USM ECU: a086 VEH thermal status";
CM_ SG_ 1520 USM_a086_VEH_vehNm "USM ECU: a086 VEH veh nm";
CM_ SG_ 1520 USM_a087_VEH_temperature "USM ECU: a087 VEH temperature";
CM_ SG_ 1520 USM_a087_VEH_thermalControl "USM ECU: a087 VEH thermal control";
CM_ SG_ 1520 USM_a087_VEH_torque "USM ECU: a087 VEH torque";
CM_ SG_ 1520 USM_a087_VEH_status "USM ECU: a087 VEH status";
CM_ SG_ 1520 USM_a087_PARTY_torque "USM ECU: a087 PARTY torque";
CM_ SG_ 1520 USM_a087_PARTY_status "USM ECU: a087 PARTY status";
CM_ SG_ 1520 USM_a087_PARTY_temperature "USM ECU: a087 PARTY temperature";
CM_ SG_ 1520 USM_a087_PARTY_thermalControl "USM ECU: a087 PARTY thermal control";
CM_ SG_ 1520 USM_a088_VEH_temperature "USM ECU: a088 VEH temperature";
CM_ SG_ 1520 USM_a088_VEH_thermalControl "USM ECU: a088 VEH thermal control";
CM_ SG_ 1520 USM_a088_VEH_torque "USM ECU: a088 VEH torque";
CM_ SG_ 1520 USM_a088_VEH_status "USM ECU: a088 VEH status";
CM_ SG_ 1520 USM_a088_PARTY_torque "USM ECU: a088 PARTY torque";
CM_ SG_ 1520 USM_a088_PARTY_status "USM ECU: a088 PARTY status";
CM_ SG_ 1520 USM_a088_PARTY_temperature "USM ECU: a088 PARTY temperature";
CM_ SG_ 1520 USM_a088_PARTY_thermalControl "USM ECU: a088 PARTY thermal control";
CM_ SG_ 1520 USM_a089_PARTY_party1 "USM ECU: a089 PARTY party1";
CM_ SG_ 1520 USM_a089_PARTY_status "USM ECU: a089 PARTY status";
CM_ SG_ 1520 USM_a089_VEH_status "USM ECU: a089 VEH status";
CM_ SG_ 1520 USM_a089_BDY_party1 "USM ECU: a089 BDY party1";
CM_ SG_ 1520 USM_a089_BDY_status "USM ECU: a089 BDY status";
CM_ SG_ 1520 USM_a089_CH_status "USM ECU: a089 CH status";
CM_ SG_ 1520 USM_a089_CH_party1 "USM ECU: a089 CH party1";
CM_ SG_ 1520 USM_a089_CH_party3 "USM ECU: a089 CH party3";
CM_ SG_ 1520 USM_a089_VEH_party1 "USM ECU: a089 VEH party1";
CM_ SG_ 1520 USM_a089_VEH_party3 "USM ECU: a089 VEH party3";
CM_ SG_ 1520 USM_a091_VEH_faultsAndExtras "USM ECU: a091 VEH faults and extras";
CM_ SG_ 1520 USM_a091_VEH_info "USM ECU: a091 VEH info";
CM_ SG_ 1520 USM_a091_VEH_state "USM ECU: a091 VEH state";
CM_ SG_ 1520 USM_a092_VEH_restraintStatus "USM ECU: a092 VEH restraint status";
CM_ SG_ 1520 USM_a092_VEH_switchStatus "USM ECU: a092 VEH switch status";
CM_ SG_ 1520 USM_a092_VEH_seatStatus2 "USM ECU: a092 VEH seat status2";
CM_ SG_ 1520 USM_a092_VEH_vehNm "USM ECU: a092 VEH veh nm";
CM_ SG_ 1520 USM_a093_VEH_restraintStatus "USM ECU: a093 VEH restraint status";
CM_ SG_ 1520 USM_a093_VEH_switchStatus "USM ECU: a093 VEH switch status";
CM_ SG_ 1520 USM_a093_VEH_seatStatus2 "USM ECU: a093 VEH seat status2";
CM_ SG_ 1520 USM_a093_VEH_vehNm "USM ECU: a093 VEH veh nm";
CM_ SG_ 1520 USM_a094_VEH_sysStatus "USM ECU: a094 VEH sys status";
CM_ SG_ 1520 USM_a094_PARTY_sysStatus "USM ECU: a094 PARTY sys status";
CM_ SG_ 1520 USM_a095_PT_ptNm "USM ECU: a095 PT pt nm";
CM_ SG_ 1520 USM_a095_PT_status "USM ECU: a095 PT status";
CM_ SG_ 1520 USM_a096_VEH_status "USM ECU: a096 VEH status";
CM_ SG_ 1520 USM_a096_CH_status "USM ECU: a096 CH status";
CM_ SG_ 1520 USM_a098_CH_torque "USM ECU: a098 CH torque";
CM_ SG_ 1520 USM_a098_VEH_hvStatus "USM ECU: a098 VEH hv status";
CM_ SG_ 1520 USM_a098_VEH_status "USM ECU: a098 VEH status";
CM_ SG_ 1520 USM_a098_VEH_thermalControl "USM ECU: a098 VEH thermal control";
CM_ SG_ 1520 USM_a098_VEH_temperature "USM ECU: a098 VEH temperature";
CM_ SG_ 1520 USM_a098_VEH_torque "USM ECU: a098 VEH torque";
CM_ SG_ 1520 USM_a098_PARTY_status "USM ECU: a098 PARTY status";
CM_ SG_ 1520 USM_a098_PARTY_temperature "USM ECU: a098 PARTY temperature";
CM_ SG_ 1520 USM_a098_PARTY_thermalControl "USM ECU: a098 PARTY thermal control";
CM_ SG_ 1520 USM_a098_PARTY_torque "USM ECU: a098 PARTY torque";
CM_ SG_ 1520 USM_a098_PT_thermalControl "USM ECU: a098 PT thermal control";
CM_ SG_ 1520 USM_a098_PT_temperature "USM ECU: a098 PT temperature";
CM_ SG_ 1520 USM_a099_VEH_oocStatus "USM ECU: a099 VEH ooc status";
CM_ SG_ 1520 USM_a100_VEH "USM ECU: a100 VEH";
CM_ SG_ 1520 USM_a100_PARTY "USM ECU: a100 PARTY";
CM_ SG_ 1520 USM_a100_PT "USM ECU: a100 PT";
CM_ SG_ 1520 USM_a100_CH "USM ECU: a100 CH";
CM_ SG_ 1520 USM_a100_OBD "USM ECU: a100 OBD";
CM_ SG_ 1520 USM_a101_VEH_state "USM ECU: a101 VEH state";
CM_ SG_ 1520 USM_a101_PARTY_locState "USM ECU: a101 PARTY loc state";
CM_ SG_ 1520 USM_a101_LIPC_externalWatchdogHe "USM ECU: a101 LIPC external watchdog heart beat";
CM_ SG_ 1520 USM_a101_VEH_locState "USM ECU: a101 VEH loc state";
CM_ SG_ 1520 USM_a101_BDY_locState "USM ECU: a101 BDY loc state";
CM_ SG_ 1520 USM_a102_VEH_faultsAndExtras "USM ECU: a102 VEH faults and extras";
CM_ SG_ 1520 USM_a102_VEH_feedbackStatus "USM ECU: a102 VEH feedback status";
CM_ SG_ 1520 USM_a102_VEH_sensorStatus "USM ECU: a102 VEH sensor status";
CM_ SG_ 1520 USM_a102_VEH_rods "USM ECU: a102 VEH rods";
CM_ SG_ 1520 USM_a103_VEH_hvsNm "USM ECU: a103 VEH hvs nm";
CM_ SG_ 1520 USM_a103_VEH_vehNm "USM ECU: a103 VEH veh nm";
CM_ SG_ 1520 USM_a103_VEH_status "USM ECU: a103 VEH status";
CM_ SG_ 1520 USM_a103_PT_ptNm "USM ECU: a103 PT pt nm";
CM_ SG_ 1520 USM_a103_PT_status "USM ECU: a103 PT status";
CM_ SG_ 1520 USM_a103_VEH_evseStatus "USM ECU: a103 VEH evse status";
CM_ SG_ 1520 USM_a105_VEH_states "USM ECU: a105 VEH states";
CM_ SG_ 1520 USM_a105_VEH_chNm "USM ECU: a105 VEH ch nm";
CM_ SG_ 1520 USM_a105_VEH_dampingStates "USM ECU: a105 VEH damping states";
CM_ SG_ 1520 USM_a106_VEH_dcdcStatus "USM ECU: a106 VEH dcdc status";
CM_ SG_ 1520 USM_a106_VEH_thermalControl "USM ECU: a106 VEH thermal control";
CM_ SG_ 1520 USM_a106_VEH_thermalInterface "USM ECU: a106 VEH thermal interface";
CM_ SG_ 1520 USM_a106_VEH_dcdcRailStatus "USM ECU: a106 VEH dcdc rail status";
CM_ SG_ 1520 USM_a106_CH_dcdcRailStatus "USM ECU: a106 CH dcdc rail status";
CM_ SG_ 1520 USM_a106_CH_alertMatrix "USM ECU: a106 CH alert matrix";
CM_ SG_ 1520 USM_a107_VEH_hvsNm "USM ECU: a107 VEH hvs nm";
CM_ SG_ 1520 USM_a107_VEH_vehNm "USM ECU: a107 VEH veh nm";
CM_ SG_ 1520 USM_a107_VEH_status "USM ECU: a107 VEH status";
CM_ SG_ 1520 USM_a107_VEH_thermalStatus "USM ECU: a107 VEH thermal status";
CM_ SG_ 1520 USM_a107_VEH_thermalStatus2 "USM ECU: a107 VEH thermal status2";
CM_ SG_ 1520 USM_a107_VEH_bmbMinMax "USM ECU: a107 VEH bmb min max";
CM_ SG_ 1520 USM_a107_VEH_powerAvailable "USM ECU: a107 VEH power available";
CM_ SG_ 1520 USM_a107_PT_ptNm "USM ECU: a107 PT pt nm";
CM_ SG_ 1520 USM_a107_PT_status "USM ECU: a107 PT status";
CM_ SG_ 1520 USM_a107_PT_thermalStatus "USM ECU: a107 PT thermal status";
CM_ SG_ 1520 USM_a107_PT_socStatus "USM ECU: a107 PT soc status";
CM_ SG_ 1520 USM_a107_VEH_socStatus "USM ECU: a107 VEH soc status";
CM_ SG_ 1520 USM_a107_VEH_packConfig "USM ECU: a107 VEH pack config";
CM_ SG_ 1520 USM_a107_VEH_energyStatus "USM ECU: a107 VEH energy status";
CM_ SG_ 1520 USM_a107_VEH_chargeInfo "USM ECU: a107 VEH charge info";
CM_ SG_ 1520 USM_a108_VEH_hvStatus "USM ECU: a108 VEH hv status";
CM_ SG_ 1520 USM_a108_VEH_temperature "USM ECU: a108 VEH temperature";
CM_ SG_ 1520 USM_a108_VEH_thermalControl "USM ECU: a108 VEH thermal control";
CM_ SG_ 1520 USM_a108_VEH_torque "USM ECU: a108 VEH torque";
CM_ SG_ 1520 USM_a108_VEH_status "USM ECU: a108 VEH status";
CM_ SG_ 1520 USM_a108_PARTY_torque "USM ECU: a108 PARTY torque";
CM_ SG_ 1520 USM_a108_PARTY_status "USM ECU: a108 PARTY status";
CM_ SG_ 1520 USM_a108_PARTY_temperature "USM ECU: a108 PARTY temperature";
CM_ SG_ 1520 USM_a108_PARTY_thermalControl "USM ECU: a108 PARTY thermal control";
CM_ SG_ 1520 USM_a108_PT_temperature "USM ECU: a108 PT temperature";
CM_ SG_ 1520 USM_a108_PT_thermalControl "USM ECU: a108 PT thermal control";
CM_ SG_ 1520 USM_a109_PARTY_status "USM ECU: a109 PARTY status";
CM_ SG_ 1520 USM_a109_PARTY_inertial2 "USM ECU: a109 PARTY inertial2";
CM_ SG_ 1520 USM_a109_PARTY_nearDeploy "USM ECU: a109 PARTY near deploy";
CM_ SG_ 1520 USM_a109_PARTY_collision "USM ECU: a109 PARTY collision";
CM_ SG_ 1520 USM_a109_VEH_status "USM ECU: a109 VEH status";
CM_ SG_ 1520 USM_a109_VEH_imuOffsets "USM ECU: a109 VEH imu offsets";
CM_ SG_ 1520 USM_a109_PARTY_inertial1 "USM ECU: a109 PARTY inertial1";
CM_ SG_ 1520 USM_a109_BDY_imuOffsets "USM ECU: a109 BDY imu offsets";
CM_ SG_ 1520 USM_a109_BDY_inertial1 "USM ECU: a109 BDY inertial1";
CM_ SG_ 1520 USM_a109_BDY_inertial2 "USM ECU: a109 BDY inertial2";
CM_ SG_ 1520 USM_a109_BDY_status "USM ECU: a109 BDY status";
CM_ SG_ 1520 USM_a109_VEH_inertial1 "USM ECU: a109 VEH inertial1";
CM_ SG_ 1520 USM_a109_VEH_inertial2 "USM ECU: a109 VEH inertial2";
CM_ SG_ 1520 USM_a109_CH_inertial1 "USM ECU: a109 CH inertial1";
CM_ SG_ 1520 USM_a109_CH_inertial2 "USM ECU: a109 CH inertial2";
CM_ SG_ 1520 USM_a109_CH_status "USM ECU: a109 CH status";
CM_ SG_ 1520 USM_a110_VEH_carState "USM ECU: a110 VEH car state";
CM_ SG_ 1520 USM_a110_VEH_carConfig "USM ECU: a110 VEH car config";
CM_ SG_ 1520 USM_a110_VEH_time "USM ECU: a110 VEH time";
CM_ SG_ 1520 USM_a110_VEH_updateStatus "USM ECU: a110 VEH update status";
CM_ SG_ 1520 USM_a110_VEH_vehNm "USM ECU: a110 VEH veh nm";
CM_ SG_ 1520 USM_a110_VEH_mismatchFault "USM ECU: a110 VEH mismatch fault";
CM_ SG_ 1520 USM_a110_VEH_vin "USM ECU: a110 VEH vin";
CM_ SG_ 1520 USM_a110_VEH_bmpDebug "USM ECU: a110 VEH bmp debug";
CM_ SG_ 1520 USM_a110_VEH_gearControl "USM ECU: a110 VEH gear control";
CM_ SG_ 1520 USM_a110_VEH_canLogAvailability "USM ECU: a110 VEH can log availability";
CM_ SG_ 1520 USM_a110_CH_airbagCutoffStatus "USM ECU: a110 CH airbag cutoff status";
CM_ SG_ 1520 USM_a110_CH_carConfig "USM ECU: a110 CH car config";
CM_ SG_ 1520 USM_a110_CH_carState "USM ECU: a110 CH car state";
CM_ SG_ 1520 USM_a110_CH_vin "USM ECU: a110 CH vin";
CM_ SG_ 1520 USM_a110_CH_chNm "USM ECU: a110 CH ch nm";
CM_ SG_ 1520 USM_a110_CH_epochTimeGtw "USM ECU: a110 CH epoch time gtw";
CM_ SG_ 1520 USM_a111_VEH_internalStatus "USM ECU: a111 VEH internal status";
CM_ SG_ 1520 USM_a111_VEH_status "USM ECU: a111 VEH status";
CM_ SG_ 1520 USM_a111_VEH_vehNm "USM ECU: a111 VEH veh nm";
CM_ SG_ 1520 USM_a111_RIPC_LVPowerState "USM ECU: a111 RIPC LV power state";
CM_ SG_ 1520 USM_a111_RIPC_epbPrivateState "USM ECU: a111 RIPC epb private state";
CM_ SG_ 1520 USM_a111_RIPC_railStatus "USM ECU: a111 RIPC rail status";
CM_ SG_ 1520 USM_a111_RIPC_remoteADC "USM ECU: a111 RIPC remote ADC";
CM_ SG_ 1520 USM_a111_RIPC_switchStatus "USM ECU: a111 RIPC switch status";
CM_ SG_ 1520 USM_a111_VEH_LVPowerState "USM ECU: a111 VEH LV power state";
CM_ SG_ 1520 USM_a111_VEH_seatStatus "USM ECU: a111 VEH seat status";
CM_ SG_ 1520 USM_a111_PARTY_status "USM ECU: a111 PARTY status";
CM_ SG_ 1520 USM_a111_CH_status "USM ECU: a111 CH status";
CM_ SG_ 1520 USM_a112_VEH_internalStatus "USM ECU: a112 VEH internal status";
CM_ SG_ 1520 USM_a112_VEH_status "USM ECU: a112 VEH status";
CM_ SG_ 1520 USM_a112_VEH_vehNm "USM ECU: a112 VEH veh nm";
CM_ SG_ 1520 USM_a112_LIPC_LVPowerState "USM ECU: a112 LIPC LV power state";
CM_ SG_ 1520 USM_a112_LIPC_epbPrivateState "USM ECU: a112 LIPC epb private state";
CM_ SG_ 1520 USM_a112_LIPC_railStatus "USM ECU: a112 LIPC rail status";
CM_ SG_ 1520 USM_a112_LIPC_remoteADC "USM ECU: a112 LIPC remote ADC";
CM_ SG_ 1520 USM_a112_LIPC_switchStatus "USM ECU: a112 LIPC switch status";
CM_ SG_ 1520 USM_a112_VEH_LVPowerState "USM ECU: a112 VEH LV power state";
CM_ SG_ 1520 USM_a112_PARTY_status "USM ECU: a112 PARTY status";
CM_ SG_ 1520 USM_a112_CH_status "USM ECU: a112 CH status";
CM_ SG_ 1520 USM_a114_PARTY_status "USM ECU: a114 PARTY status";
CM_ SG_ 1520 USM_a114_PARTY_wheelSpeeds "USM ECU: a114 PARTY wheel speeds";
CM_ SG_ 1520 USM_a114_VEH_wheelSpeeds "USM ECU: a114 VEH wheel speeds";
CM_ SG_ 1520 USM_a114_CH_wheelSpeeds "USM ECU: a114 CH wheel speeds";
CM_ SG_ 1520 USM_a114_PARTY_party3 "USM ECU: a114 PARTY party3";
CM_ SG_ 1520 USM_a114_VEH_party3 "USM ECU: a114 VEH party3";
CM_ SG_ 1520 USM_a114_VEH_status "USM ECU: a114 VEH status";
CM_ SG_ 1520 USM_a114_PARTY_wheelRotation "USM ECU: a114 PARTY wheel rotation";
CM_ SG_ 1520 USM_a114_CH_wheelRotation "USM ECU: a114 CH wheel rotation";
CM_ SG_ 1520 USM_a114_VEH_wheelRotation "USM ECU: a114 VEH wheel rotation";
CM_ SG_ 1520 USM_a114_PARTY_brakeTorque "USM ECU: a114 PARTY brake torque";
CM_ SG_ 1520 USM_a114_PARTY_offsets "USM ECU: a114 PARTY offsets";
CM_ SG_ 1520 USM_a114_BDY_offsets "USM ECU: a114 BDY offsets";
CM_ SG_ 1520 USM_a114_BDY_party3 "USM ECU: a114 BDY party3";
CM_ SG_ 1520 USM_a114_BDY_status "USM ECU: a114 BDY status";
CM_ SG_ 1520 USM_a114_BDY_wheelRotation "USM ECU: a114 BDY wheel rotation";
CM_ SG_ 1520 USM_a114_BDY_wheelSpeeds "USM ECU: a114 BDY wheel speeds";
CM_ SG_ 1520 USM_a114_CH_party1 "USM ECU: a114 CH party1";
CM_ SG_ 1520 USM_a114_CH_party3 "USM ECU: a114 CH party3";
CM_ SG_ 1520 USM_a114_CH_status "USM ECU: a114 CH status";
CM_ SG_ 1520 USM_a115_VEH_vehNm "USM ECU: a115 VEH veh nm";
CM_ SG_ 1520 USM_a115_VEH_authentication "USM ECU: a115 VEH authentication";
CM_ SG_ 1520 USM_a115_VEH_BLEResetRequest "USM ECU: a115 VEH BLE reset request";
CM_ SG_ 1520 USM_a115_VEH_requests "USM ECU: a115 VEH requests";
CM_ SG_ 1520 USM_a115_VEH_requests2 "USM ECU: a115 VEH requests2";
CM_ SG_ 1520 USM_a115_REM_authentication "USM ECU: a115 REM authentication";
CM_ SG_ 1520 USM_a115_UI_corianderVehicleCont "USM ECU: a115 UI coriander vehicle control";
CM_ SG_ 1520 USM_a115_CH_TPMSDisplay "USM ECU: a115 CH TPMS display";
CM_ SG_ 1520 USM_a116_PARTY_epbmStatus "USM ECU: a116 PARTY epbm status";
CM_ SG_ 1520 USM_a116_VEH_vehNm "USM ECU: a116 VEH veh nm";
CM_ SG_ 1520 USM_a116_VEH_hvacRequest "USM ECU: a116 VEH hvac request";
CM_ SG_ 1520 USM_a116_VEH_hvacStatus "USM ECU: a116 VEH hvac status";
CM_ SG_ 1520 USM_a116_VEH_LVPowerState "USM ECU: a116 VEH LV power state";
CM_ SG_ 1520 USM_a116_VEH_lightStatus "USM ECU: a116 VEH light status";
CM_ SG_ 1520 USM_a116_VEH_seatStatus "USM ECU: a116 VEH seat status";
CM_ SG_ 1520 USM_a116_VEH_thsStatus "USM ECU: a116 VEH ths status";
CM_ SG_ 1520 USM_a116_VEH_doorStatus "USM ECU: a116 VEH door status";
CM_ SG_ 1520 USM_a116_VEH_seatHeatStatus "USM ECU: a116 VEH seat heat status";
CM_ SG_ 1520 USM_a116_VEH_restraintStatus "USM ECU: a116 VEH restraint status";
CM_ SG_ 1520 USM_a116_VEH_switchStatus "USM ECU: a116 VEH switch status";
CM_ SG_ 1520 USM_a116_VEH_logging1Hz "USM ECU: a116 VEH logging1 hz";
CM_ SG_ 1520 USM_a116_VEH_seatStatus2 "USM ECU: a116 VEH seat status2";
CM_ SG_ 1520 USM_a116_VEH_status "USM ECU: a116 VEH status";
CM_ SG_ 1520 USM_a116_VEH_thermalCommand "USM ECU: a116 VEH thermal command";
CM_ SG_ 1520 USM_a116_VEH_windowStatus "USM ECU: a116 VEH window status";
CM_ SG_ 1520 USM_a116_PARTY_restraintStatus "USM ECU: a116 PARTY restraint status";
CM_ SG_ 1520 USM_a116_PARTY_doorStatus "USM ECU: a116 PARTY door status";
CM_ SG_ 1520 USM_a116_BDY_epbmStatus "USM ECU: a116 BDY epbm status";
CM_ SG_ 1520 USM_a116_BDY_restraintStatus "USM ECU: a116 BDY restraint status";
CM_ SG_ 1520 USM_a117_BDY_epbmStatus "USM ECU: a117 BDY epbm status";
CM_ SG_ 1520 USM_a117_BDY_restraintStatus "USM ECU: a117 BDY restraint status";
CM_ SG_ 1520 USM_a117_VEH_prndStatus "USM ECU: a117 VEH prnd status";
CM_ SG_ 1520 USM_a117_PARTY_epbmStatus "USM ECU: a117 PARTY epbm status";
CM_ SG_ 1520 USM_a117_VEH_vehNm "USM ECU: a117 VEH veh nm";
CM_ SG_ 1520 USM_a117_VEH_hvacBlowerFdb "USM ECU: a117 VEH hvac blower fdb";
CM_ SG_ 1520 USM_a117_VEH_LVPowerState "USM ECU: a117 VEH LV power state";
CM_ SG_ 1520 USM_a117_VEH_restraintStatus "USM ECU: a117 VEH restraint status";
CM_ SG_ 1520 USM_a117_VEH_lightStatus "USM ECU: a117 VEH light status";
CM_ SG_ 1520 USM_a117_VEH_seatStatus "USM ECU: a117 VEH seat status";
CM_ SG_ 1520 USM_a117_BDY_falconSwitchStatus "USM ECU: a117 BDY falcon switch status";
CM_ SG_ 1520 USM_a117_VEH_doorStatus "USM ECU: a117 VEH door status";
CM_ SG_ 1520 USM_a117_VEH_doorStatus2 "USM ECU: a117 VEH door status2";
CM_ SG_ 1520 USM_a117_VEH_windowStatus "USM ECU: a117 VEH window status";
CM_ SG_ 1520 USM_a117_VEH_switchStatus "USM ECU: a117 VEH switch status";
CM_ SG_ 1520 USM_a117_VEH_intrusionSensorStat "USM ECU: a117 VEH intrusion sensor status";
CM_ SG_ 1520 USM_a117_VEH_liftgateStatus "USM ECU: a117 VEH liftgate status";
CM_ SG_ 1520 USM_a117_VEH_seatStatus2 "USM ECU: a117 VEH seat status2";
CM_ SG_ 1520 USM_a117_PARTY_restraintStatus "USM ECU: a117 PARTY restraint status";
CM_ SG_ 1520 USM_a117_VEH_thermalStatus "USM ECU: a117 VEH thermal status";
CM_ SG_ 1520 USM_a117_PARTY_doorStatus "USM ECU: a117 PARTY door status";
CM_ SG_ 1520 USM_a117_VEH_status "USM ECU: a117 VEH status";
CM_ SG_ 1520 USM_a117_PARTY_prndStatus "USM ECU: a117 PARTY prnd status";
CM_ SG_ 1520 USM_a118_VEH_vehNm "USM ECU: a118 VEH veh nm";
CM_ SG_ 1520 USM_a118_VEH_lighting "USM ECU: a118 VEH lighting";
CM_ SG_ 1520 USM_a118_VEH_sensors "USM ECU: a118 VEH sensors";
CM_ SG_ 1520 USM_a118_VEH_status "USM ECU: a118 VEH status";
CM_ SG_ 1520 USM_a118_VEH_okToUseHighPwr "USM ECU: a118 VEH ok to use high pwr";
CM_ SG_ 1520 USM_a118_VEH_LVPowerState "USM ECU: a118 VEH LV power state";
CM_ SG_ 1520 USM_a118_VEH_coolant "USM ECU: a118 VEH coolant";
CM_ SG_ 1520 USM_a118_VEH_vehicleStatus "USM ECU: a118 VEH vehicle status";
CM_ SG_ 1520 USM_a118_VEH_12VBatteryStatus "USM ECU: a118 VEH 12 v battery status";
CM_ SG_ 1520 USM_a118_VEH_systemStatus "USM ECU: a118 VEH system status";
CM_ SG_ 1520 USM_a118_PARTY_LVPowerState "USM ECU: a118 PARTY LV power state";
CM_ SG_ 1520 USM_a118_PARTY_outputPowerStatus "USM ECU: a118 PARTY output power status";
CM_ SG_ 1520 USM_a118_PARTY_vehicleTime "USM ECU: a118 PARTY vehicle time";
CM_ SG_ 1520 USM_a118_VEH_thermalCommand "USM ECU: a118 VEH thermal command";
CM_ SG_ 1520 USM_a118_CH_LVPowerState "USM ECU: a118 CH LV power state";
CM_ SG_ 1520 USM_a118_PARTY_sensors "USM ECU: a118 PARTY sensors";
CM_ SG_ 1520 USM_a118_CH_sensors "USM ECU: a118 CH sensors";
CM_ SG_ 1520 USM_a118_VEH_interNodeResistance "USM ECU: a118 VEH inter node resistance";
CM_ SG_ 1520 USM_a118_CH_lighting "USM ECU: a118 CH lighting";
CM_ SG_ 1520 USM_a118_VEH_lightStatus "USM ECU: a118 VEH light status";
CM_ SG_ 1520 USM_a118_PARTY_vehNm "USM ECU: a118 PARTY veh nm";
CM_ SG_ 1520 USM_a118_CH_12VBatteryStatus "USM ECU: a118 CH 12 v battery status";
CM_ SG_ 1520 USM_a118_CH_LVBMS_statusHigh "USM ECU: a118 CH LVBMS status high";
CM_ SG_ 1520 USM_a118_CH_alertMatrix "USM ECU: a118 CH alert matrix";
CM_ SG_ 1520 USM_a118_BDY_outputPowerStatus "USM ECU: a118 BDY output power status";
CM_ SG_ 1520 USM_a118_BDY_vehicleTime "USM ECU: a118 BDY vehicle time";
CM_ SG_ 1520 USM_a118_PARTY_AP_vehicleState1H "USM ECU: a118 PARTY AP vehicle state1 hz muxed";
CM_ SG_ 1520 USM_a118_BDY_AP_vehicleState1HzM "USM ECU: a118 BDY AP vehicle state1 hz muxed";
CM_ SG_ 1520 USM_a119_VEH_steerAngle "USM ECU: a119 VEH steer angle";
CM_ SG_ 1520 USM_a119_VEH_leftStalk "USM ECU: a119 VEH left stalk";
CM_ SG_ 1520 USM_a119_VEH_rightStalk "USM ECU: a119 VEH right stalk";
CM_ SG_ 1520 USM_a119_PARTY_rightStalk "USM ECU: a119 PARTY right stalk";
CM_ SG_ 1520 USM_a119_CH_steerAngle "USM ECU: a119 CH steer angle";
CM_ SG_ 1520 USM_a119_PARTY_steerAngle "USM ECU: a119 PARTY steer angle";
CM_ SG_ 1520 USM_a120_PARTY_chassisCntl "USM ECU: a120 PARTY chassis cntl";
CM_ SG_ 1520 USM_a120_VEH_systemStatus "USM ECU: a120 VEH system status";
CM_ SG_ 1520 USM_a120_CH_chassisCntl "USM ECU: a120 CH chassis cntl";
CM_ SG_ 1520 USM_a120_PARTY_systemStatus "USM ECU: a120 PARTY system status";
CM_ SG_ 1520 USM_a120_PARTY_torque "USM ECU: a120 PARTY torque";
CM_ SG_ 1520 USM_a120_VEH_torque "USM ECU: a120 VEH torque";
CM_ SG_ 1520 USM_a120_PARTY_locStatus "USM ECU: a120 PARTY loc status";
CM_ SG_ 1520 USM_a120_PARTY_speed "USM ECU: a120 PARTY speed";
CM_ SG_ 1520 USM_a120_VEH_speed "USM ECU: a120 VEH speed";
CM_ SG_ 1520 USM_a120_PARTY_status "USM ECU: a120 PARTY status";
CM_ SG_ 1520 USM_a120_PT_speed "USM ECU: a120 PT speed";
CM_ SG_ 1520 USM_a120_PT_systemStatus "USM ECU: a120 PT system status";
CM_ SG_ 1520 USM_a120_PARTY_vehicleEstimates "USM ECU: a120 PARTY vehicle estimates";
CM_ SG_ 1520 USM_a120_VEH_aggregatedAxleSpeed "USM ECU: a120 VEH aggregated axle speed";
CM_ SG_ 1520 USM_a120_PARTY_aggregatedAxleSpe "USM ECU: a120 PARTY aggregated axle speed";
CM_ SG_ 1520 USM_a120_VEH_systemPower "USM ECU: a120 VEH system power";
CM_ SG_ 1520 USM_a120_PT_systemPower "USM ECU: a120 PT system power";
CM_ SG_ 1520 USM_a120_PARTY_stalklessInterfac "USM ECU: a120 PARTY stalkless interfaces";
CM_ SG_ 1520 USM_a120_CH_speed "USM ECU: a120 CH speed";
CM_ SG_ 1520 USM_a120_VEH_estimatedBrakeTemp "USM ECU: a120 VEH estimated brake temp";
CM_ SG_ 1520 USM_a120_PARTY_prndControl "USM ECU: a120 PARTY prnd control";
CM_ SG_ 1520 USM_a120_PARTY_locStatus2 "USM ECU: a120 PARTY loc status2";
CM_ SG_ 1520 USM_a120_VEH_chassisCntl "USM ECU: a120 VEH chassis cntl";
CM_ SG_ 1520 USM_a120_VEH_locStatus "USM ECU: a120 VEH loc status";
CM_ SG_ 1520 USM_a120_VEH_locStatus2 "USM ECU: a120 VEH loc status2";
CM_ SG_ 1520 USM_a120_VEH_prndControl "USM ECU: a120 VEH prnd control";
CM_ SG_ 1520 USM_a120_VEH_vehicleEstimates "USM ECU: a120 VEH vehicle estimates";
CM_ SG_ 1520 USM_a131_inDrivePowerState "USM ECU: a131 in drive power state";
CM_ SG_ 1520 USM_a131_timeSinceInit "USM ECU: a131 time since init";
CM_ SG_ 1520 USM_a131_timeSincePwrStateTransi "USM ECU: a131 time since pwr state transition";
CM_ SG_ 1520 USM_a131_numComErrSinceInit "USM ECU: a131 num com err since init";
CM_ SG_ 1520 USM_a132_inDrivePowerState "USM ECU: a132 in drive power state";
CM_ SG_ 1520 USM_a132_timeSinceInit "USM ECU: a132 time since init";
CM_ SG_ 1520 USM_a132_timeSincePwrStateTransi "USM ECU: a132 time since pwr state transition";
CM_ SG_ 1520 USM_a132_numComErrSinceInit "USM ECU: a132 num com err since init";
CM_ SG_ 1520 USM_a133_inDrivePowerState "USM ECU: a133 in drive power state";
CM_ SG_ 1520 USM_a133_timeSinceInit "USM ECU: a133 time since init";
CM_ SG_ 1520 USM_a133_timeSincePwrStateTransi "USM ECU: a133 time since pwr state transition";
CM_ SG_ 1520 USM_a133_numComErrSinceInit "USM ECU: a133 num com err since init";
CM_ SG_ 1520 USM_a134_inDrivePowerState "USM ECU: a134 in drive power state";
CM_ SG_ 1520 USM_a134_timeSinceInit "USM ECU: a134 time since init";
CM_ SG_ 1520 USM_a134_timeSincePwrStateTransi "USM ECU: a134 time since pwr state transition";
CM_ SG_ 1520 USM_a134_numComErrSinceInit "USM ECU: a134 num com err since init";
CM_ SG_ 1520 USM_a135_inDrivePowerState "USM ECU: a135 in drive power state";
CM_ SG_ 1520 USM_a135_timeSinceInit "USM ECU: a135 time since init";
CM_ SG_ 1520 USM_a135_timeSincePwrStateTransi "USM ECU: a135 time since pwr state transition";
CM_ SG_ 1520 USM_a135_numComErrSinceInit "USM ECU: a135 num com err since init";
CM_ SG_ 1520 USM_a136_inDrivePowerState "USM ECU: a136 in drive power state";
CM_ SG_ 1520 USM_a136_timeSinceInit "USM ECU: a136 time since init";
CM_ SG_ 1520 USM_a136_timeSincePwrStateTransi "USM ECU: a136 time since pwr state transition";
CM_ SG_ 1520 USM_a136_numComErrSinceInit "USM ECU: a136 num com err since init";
CM_ SG_ 1520 USM_a137_inDrivePowerState "USM ECU: a137 in drive power state";
CM_ SG_ 1520 USM_a137_timeSinceInit "USM ECU: a137 time since init";
CM_ SG_ 1520 USM_a137_timeSincePwrStateTransi "USM ECU: a137 time since pwr state transition";
CM_ SG_ 1520 USM_a137_numComErrSinceInit "USM ECU: a137 num com err since init";
CM_ SG_ 1520 USM_a138_inDrivePowerState "USM ECU: a138 in drive power state";
CM_ SG_ 1520 USM_a138_timeSinceInit "USM ECU: a138 time since init";
CM_ SG_ 1520 USM_a138_timeSincePwrStateTransi "USM ECU: a138 time since pwr state transition";
CM_ SG_ 1520 USM_a138_numComErrSinceInit "USM ECU: a138 num com err since init";
CM_ SG_ 1520 USM_a139_inDrivePowerState "USM ECU: a139 in drive power state";
CM_ SG_ 1520 USM_a139_timeSinceInit "USM ECU: a139 time since init";
CM_ SG_ 1520 USM_a139_timeSincePwrStateTransi "USM ECU: a139 time since pwr state transition";
CM_ SG_ 1520 USM_a139_numComErrSinceInit "USM ECU: a139 num com err since init";
CM_ SG_ 1520 USM_a140_inDrivePowerState "USM ECU: a140 in drive power state";
CM_ SG_ 1520 USM_a140_timeSinceInit "USM ECU: a140 time since init";
CM_ SG_ 1520 USM_a140_timeSincePwrStateTransi "USM ECU: a140 time since pwr state transition";
CM_ SG_ 1520 USM_a140_numComErrSinceInit "USM ECU: a140 num com err since init";
CM_ SG_ 1520 USM_a141_inDrivePowerState "USM ECU: a141 in drive power state";
CM_ SG_ 1520 USM_a141_timeSinceInit "USM ECU: a141 time since init";
CM_ SG_ 1520 USM_a141_timeSincePwrStateTransi "USM ECU: a141 time since pwr state transition";
CM_ SG_ 1520 USM_a141_numComErrSinceInit "USM ECU: a141 num com err since init";
CM_ SG_ 1520 USM_a142_inDrivePowerState "USM ECU: a142 in drive power state";
CM_ SG_ 1520 USM_a142_timeSinceInit "USM ECU: a142 time since init";
CM_ SG_ 1520 USM_a142_timeSincePwrStateTransi "USM ECU: a142 time since pwr state transition";
CM_ SG_ 1520 USM_a142_numComErrSinceInit "USM ECU: a142 num com err since init";
CM_ SG_ 1520 USM_a143_inDrivePowerState "USM ECU: a143 in drive power state";
CM_ SG_ 1520 USM_a143_timeSinceInit "USM ECU: a143 time since init";
CM_ SG_ 1520 USM_a143_timeSincePwrStateTransi "USM ECU: a143 time since pwr state transition";
CM_ SG_ 1520 USM_a143_numHwErrSinceInit "USM ECU: a143 num hw err since init";
CM_ SG_ 1520 USM_a144_inDrivePowerState "USM ECU: a144 in drive power state";
CM_ SG_ 1520 USM_a144_timeSinceInit "USM ECU: a144 time since init";
CM_ SG_ 1520 USM_a144_timeSincePwrStateTransi "USM ECU: a144 time since pwr state transition";
CM_ SG_ 1520 USM_a144_numHwErrSinceInit "USM ECU: a144 num hw err since init";
CM_ SG_ 1520 USM_a145_inDrivePowerState "USM ECU: a145 in drive power state";
CM_ SG_ 1520 USM_a145_timeSinceInit "USM ECU: a145 time since init";
CM_ SG_ 1520 USM_a145_timeSincePwrStateTransi "USM ECU: a145 time since pwr state transition";
CM_ SG_ 1520 USM_a145_numHwErrSinceInit "USM ECU: a145 num hw err since init";
CM_ SG_ 1520 USM_a146_inDrivePowerState "USM ECU: a146 in drive power state";
CM_ SG_ 1520 USM_a146_timeSinceInit "USM ECU: a146 time since init";
CM_ SG_ 1520 USM_a146_timeSincePwrStateTransi "USM ECU: a146 time since pwr state transition";
CM_ SG_ 1520 USM_a146_numHwErrSinceInit "USM ECU: a146 num hw err since init";
CM_ SG_ 1520 USM_a147_inDrivePowerState "USM ECU: a147 in drive power state";
CM_ SG_ 1520 USM_a147_timeSinceInit "USM ECU: a147 time since init";
CM_ SG_ 1520 USM_a147_timeSincePwrStateTransi "USM ECU: a147 time since pwr state transition";
CM_ SG_ 1520 USM_a147_numHwErrSinceInit "USM ECU: a147 num hw err since init";
CM_ SG_ 1520 USM_a148_inDrivePowerState "USM ECU: a148 in drive power state";
CM_ SG_ 1520 USM_a148_timeSinceInit "USM ECU: a148 time since init";
CM_ SG_ 1520 USM_a148_timeSincePwrStateTransi "USM ECU: a148 time since pwr state transition";
CM_ SG_ 1520 USM_a148_numHwErrSinceInit "USM ECU: a148 num hw err since init";
CM_ SG_ 1520 USM_a149_inDrivePowerState "USM ECU: a149 in drive power state";
CM_ SG_ 1520 USM_a149_timeSinceInit "USM ECU: a149 time since init";
CM_ SG_ 1520 USM_a149_timeSincePwrStateTransi "USM ECU: a149 time since pwr state transition";
CM_ SG_ 1520 USM_a149_numHwErrSinceInit "USM ECU: a149 num hw err since init";
CM_ SG_ 1520 USM_a150_inDrivePowerState "USM ECU: a150 in drive power state";
CM_ SG_ 1520 USM_a150_timeSinceInit "USM ECU: a150 time since init";
CM_ SG_ 1520 USM_a150_timeSincePwrStateTransi "USM ECU: a150 time since pwr state transition";
CM_ SG_ 1520 USM_a150_numHwErrSinceInit "USM ECU: a150 num hw err since init";
CM_ SG_ 1520 USM_a151_inDrivePowerState "USM ECU: a151 in drive power state";
CM_ SG_ 1520 USM_a151_timeSinceInit "USM ECU: a151 time since init";
CM_ SG_ 1520 USM_a151_timeSincePwrStateTransi "USM ECU: a151 time since pwr state transition";
CM_ SG_ 1520 USM_a151_numHwErrSinceInit "USM ECU: a151 num hw err since init";
CM_ SG_ 1520 USM_a152_inDrivePowerState "USM ECU: a152 in drive power state";
CM_ SG_ 1520 USM_a152_timeSinceInit "USM ECU: a152 time since init";
CM_ SG_ 1520 USM_a152_timeSincePwrStateTransi "USM ECU: a152 time since pwr state transition";
CM_ SG_ 1520 USM_a152_numHwErrSinceInit "USM ECU: a152 num hw err since init";
CM_ SG_ 1520 USM_a153_inDrivePowerState "USM ECU: a153 in drive power state";
CM_ SG_ 1520 USM_a153_timeSinceInit "USM ECU: a153 time since init";
CM_ SG_ 1520 USM_a153_timeSincePwrStateTransi "USM ECU: a153 time since pwr state transition";
CM_ SG_ 1520 USM_a153_numHwErrSinceInit "USM ECU: a153 num hw err since init";
CM_ SG_ 1520 USM_a154_inDrivePowerState "USM ECU: a154 in drive power state";
CM_ SG_ 1520 USM_a154_timeSinceInit "USM ECU: a154 time since init";
CM_ SG_ 1520 USM_a154_timeSincePwrStateTransi "USM ECU: a154 time since pwr state transition";
CM_ SG_ 1520 USM_a154_numHwErrSinceInit "USM ECU: a154 num hw err since init";
CM_ SG_ 1520 USM_a155_temperature "USM ECU: a155 temperature";
CM_ SG_ 1520 USM_a156_temperature "USM ECU: a156 temperature";
CM_ SG_ 1520 USM_a157_temperature "USM ECU: a157 temperature";
CM_ SG_ 1520 USM_a158_temperature "USM ECU: a158 temperature";
CM_ SG_ 1520 USM_a159_temperature "USM ECU: a159 temperature";
CM_ SG_ 1520 USM_a160_temperature "USM ECU: a160 temperature";
CM_ SG_ 1520 USM_a161_temperature "USM ECU: a161 temperature";
CM_ SG_ 1520 USM_a162_temperature "USM ECU: a162 temperature";
CM_ SG_ 1520 USM_a163_temperature "USM ECU: a163 temperature";
CM_ SG_ 1520 USM_a164_temperature "USM ECU: a164 temperature";
CM_ SG_ 1520 USM_a165_temperature "USM ECU: a165 temperature";
CM_ SG_ 1520 USM_a166_temperature "USM ECU: a166 temperature";
CM_ SG_ 1520 USM_a177_rtmCompensated "USM ECU: a177 rtm compensated";
CM_ SG_ 1520 USM_a177_rtmOffset "USM ECU: a177 rtm offset";
CM_ SG_ 1520 USM_a177_rtmOffsetFromInit "USM ECU: a177 rtm offset from init";
CM_ SG_ 1520 USM_a177_ambientTemperature "USM ECU: a177 ambient temperature; raw 0 = signal not available (SNA)";
CM_ SG_ 1520 USM_a177_sensorTemperature "USM ECU: a177 sensor temperature";
CM_ SG_ 1520 USM_a178_rtmCompensated "USM ECU: a178 rtm compensated";
CM_ SG_ 1520 USM_a178_rtmOffset "USM ECU: a178 rtm offset";
CM_ SG_ 1520 USM_a178_rtmOffsetFromInit "USM ECU: a178 rtm offset from init";
CM_ SG_ 1520 USM_a178_ambientTemperature "USM ECU: a178 ambient temperature; raw 0 = signal not available (SNA)";
CM_ SG_ 1520 USM_a178_sensorTemperature "USM ECU: a178 sensor temperature";
CM_ SG_ 1520 USM_a179_rtmCompensated "USM ECU: a179 rtm compensated";
CM_ SG_ 1520 USM_a179_rtmOffset "USM ECU: a179 rtm offset";
CM_ SG_ 1520 USM_a179_rtmOffsetFromInit "USM ECU: a179 rtm offset from init";
CM_ SG_ 1520 USM_a179_ambientTemperature "USM ECU: a179 ambient temperature; raw 0 = signal not available (SNA)";
CM_ SG_ 1520 USM_a179_sensorTemperature "USM ECU: a179 sensor temperature";
CM_ SG_ 1520 USM_a180_rtmCompensated "USM ECU: a180 rtm compensated";
CM_ SG_ 1520 USM_a180_rtmOffset "USM ECU: a180 rtm offset";
CM_ SG_ 1520 USM_a180_rtmOffsetFromInit "USM ECU: a180 rtm offset from init";
CM_ SG_ 1520 USM_a180_ambientTemperature "USM ECU: a180 ambient temperature; raw 0 = signal not available (SNA)";
CM_ SG_ 1520 USM_a180_sensorTemperature "USM ECU: a180 sensor temperature";
CM_ SG_ 1520 USM_a181_rtmCompensated "USM ECU: a181 rtm compensated";
CM_ SG_ 1520 USM_a181_rtmOffset "USM ECU: a181 rtm offset";
CM_ SG_ 1520 USM_a181_rtmOffsetFromInit "USM ECU: a181 rtm offset from init";
CM_ SG_ 1520 USM_a181_ambientTemperature "USM ECU: a181 ambient temperature; raw 0 = signal not available (SNA)";
CM_ SG_ 1520 USM_a181_sensorTemperature "USM ECU: a181 sensor temperature";
CM_ SG_ 1520 USM_a182_rtmCompensated "USM ECU: a182 rtm compensated";
CM_ SG_ 1520 USM_a182_rtmOffset "USM ECU: a182 rtm offset";
CM_ SG_ 1520 USM_a182_rtmOffsetFromInit "USM ECU: a182 rtm offset from init";
CM_ SG_ 1520 USM_a182_ambientTemperature "USM ECU: a182 ambient temperature; raw 0 = signal not available (SNA)";
CM_ SG_ 1520 USM_a182_sensorTemperature "USM ECU: a182 sensor temperature";
CM_ SG_ 1520 USM_a183_rtmCompensated "USM ECU: a183 rtm compensated";
CM_ SG_ 1520 USM_a183_rtmOffset "USM ECU: a183 rtm offset";
CM_ SG_ 1520 USM_a183_rtmOffsetFromInit "USM ECU: a183 rtm offset from init";
CM_ SG_ 1520 USM_a183_ambientTemperature "USM ECU: a183 ambient temperature; raw 0 = signal not available (SNA)";
CM_ SG_ 1520 USM_a183_sensorTemperature "USM ECU: a183 sensor temperature";
CM_ SG_ 1520 USM_a184_rtmCompensated "USM ECU: a184 rtm compensated";
CM_ SG_ 1520 USM_a184_rtmOffset "USM ECU: a184 rtm offset";
CM_ SG_ 1520 USM_a184_rtmOffsetFromInit "USM ECU: a184 rtm offset from init";
CM_ SG_ 1520 USM_a184_ambientTemperature "USM ECU: a184 ambient temperature; raw 0 = signal not available (SNA)";
CM_ SG_ 1520 USM_a184_sensorTemperature "USM ECU: a184 sensor temperature";
CM_ SG_ 1520 USM_a185_rtmCompensated "USM ECU: a185 rtm compensated";
CM_ SG_ 1520 USM_a185_rtmOffset "USM ECU: a185 rtm offset";
CM_ SG_ 1520 USM_a185_rtmOffsetFromInit "USM ECU: a185 rtm offset from init";
CM_ SG_ 1520 USM_a185_ambientTemperature "USM ECU: a185 ambient temperature; raw 0 = signal not available (SNA)";
CM_ SG_ 1520 USM_a185_sensorTemperature "USM ECU: a185 sensor temperature";
CM_ SG_ 1520 USM_a186_rtmCompensated "USM ECU: a186 rtm compensated";
CM_ SG_ 1520 USM_a186_rtmOffset "USM ECU: a186 rtm offset";
CM_ SG_ 1520 USM_a186_rtmOffsetFromInit "USM ECU: a186 rtm offset from init";
CM_ SG_ 1520 USM_a186_ambientTemperature "USM ECU: a186 ambient temperature; raw 0 = signal not available (SNA)";
CM_ SG_ 1520 USM_a186_sensorTemperature "USM ECU: a186 sensor temperature";
CM_ SG_ 1520 USM_a187_rtmCompensated "USM ECU: a187 rtm compensated";
CM_ SG_ 1520 USM_a187_rtmOffset "USM ECU: a187 rtm offset";
CM_ SG_ 1520 USM_a187_rtmOffsetFromInit "USM ECU: a187 rtm offset from init";
CM_ SG_ 1520 USM_a187_ambientTemperature "USM ECU: a187 ambient temperature; raw 0 = signal not available (SNA)";
CM_ SG_ 1520 USM_a187_sensorTemperature "USM ECU: a187 sensor temperature";
CM_ SG_ 1520 USM_a188_rtmCompensated "USM ECU: a188 rtm compensated";
CM_ SG_ 1520 USM_a188_rtmOffset "USM ECU: a188 rtm offset";
CM_ SG_ 1520 USM_a188_rtmOffsetFromInit "USM ECU: a188 rtm offset from init";
CM_ SG_ 1520 USM_a188_ambientTemperature "USM ECU: a188 ambient temperature; raw 0 = signal not available (SNA)";
CM_ SG_ 1520 USM_a188_sensorTemperature "USM ECU: a188 sensor temperature";
CM_ SG_ 1520 USM_a201_channel "USM ECU: a201 channel";
CM_ SG_ 1520 USM_a201_OT "USM ECU: a201 OT";
CM_ SG_ 1520 USM_a201_VCCUV_RFCB "USM ECU: a201 VCCUV RFCB";
CM_ SG_ 1520 USM_a201_CLKREF_ERROR "USM ECU: a201 CLKREF ERROR";
CM_ SG_ 1520 USM_a201_CMD_INC "USM ECU: a201 CMD INC";
CM_ SG_ 1520 USM_a201_CRC_ERROR "USM ECU: a201 CRC ERROR";
CM_ SG_ 1520 USM_a201_UND_CMD "USM ECU: a201 UND CMD";
CM_ SG_ 1520 USM_a201_DSI1_CMD_OVR "USM ECU: a201 DSI1 CMD OVR";
CM_ SG_ 1520 USM_a201_DSI2_CMD_OVR "USM ECU: a201 DSI2 CMD OVR";
CM_ SG_ 1520 USM_a201_DSI1_UV "USM ECU: a201 DSI1 UV";
CM_ SG_ 1520 USM_a201_DSI2_UV "USM ECU: a201 DSI2 UV";
CM_ SG_ 1520 USM_a201_DSI1_ND "USM ECU: a201 DSI1 ND";
CM_ SG_ 1520 USM_a201_DSI2_ND "USM ECU: a201 DSI2 ND";
CM_ SG_ 1520 USM_a201_DSI1_OR "USM ECU: a201 DSI1 OR";
CM_ SG_ 1520 USM_a201_DSI2_OR "USM ECU: a201 DSI2 OR";
CM_ SG_ 1520 USM_a201_DSI1_DL "USM ECU: a201 DSI1 DL";
CM_ SG_ 1520 USM_a201_DSI2_DL "USM ECU: a201 DSI2 DL";
CM_ SG_ 1520 USM_a201_DSI1_PC "USM ECU: a201 DSI1 PC";
CM_ SG_ 1520 USM_a201_DSI2_PC "USM ECU: a201 DSI2 PC";
CM_ SG_ 1520 USM_a202_channel "USM ECU: a202 channel";
CM_ SG_ 1520 USM_a202_EE "USM ECU: a202 EE";
CM_ SG_ 1520 USM_a202_LE "USM ECU: a202 LE";
CM_ SG_ 1520 USM_a202_SC "USM ECU: a202 SC";
CM_ SG_ 1520 USM_a202_CR "USM ECU: a202 CR";
CM_ SG_ 1520 USM_a202_SP "USM ECU: a202 SP";
CM_ SG_ 1520 USM_a202_SE "USM ECU: a202 SE";
CM_ SG_ 1520 USM_a202_UV "USM ECU: a202 UV";
CM_ SG_ 1520 USM_a202_CE "USM ECU: a202 CE";
CM_ SG_ 1520 USM_a227_reset "USM ECU: a227 reset";
CM_ SG_ 1520 USM_a227_otpCrcError "USM ECU: a227 otp crc error";
CM_ SG_ 1520 USM_a227_trimRegParityErr "USM ECU: a227 trim reg parity err";
CM_ SG_ 1520 USM_a227_sramParityErr "USM ECU: a227 sram parity err";
CM_ SG_ 1520 USM_a227_crcMismatchInOtp "USM ECU: a227 crc mismatch in otp";
CM_ SG_ 1520 USM_a227_crcMismatchInSysrom "USM ECU: a227 crc mismatch in sysrom";
CM_ SG_ 1520 USM_a227_crcMismatchInEeprom "USM ECU: a227 crc mismatch in eeprom";
CM_ SG_ 1520 USM_a227_capLossVdddOutOfRange "USM ECU: a227 cap loss vddd out of range";
CM_ SG_ 1520 USM_a227_capLossVddaOutOfRange "USM ECU: a227 cap loss vdda out of range";
CM_ SG_ 1520 USM_a227_referenceVoltOutOfRange "USM ECU: a227 reference volt out of range";
CM_ SG_ 1520 USM_a227_vdddVoltOutOfRange "USM ECU: a227 vddd volt out of range";
CM_ SG_ 1520 USM_a227_vrefVoldOfOtpOutOfRange "USM ECU: a227 vref vold of otp out of range";
CM_ SG_ 1520 USM_a227_eepromProgFail "USM ECU: a227 eeprom prog fail";
CM_ SG_ 1520 USM_a227_eepromProgBuys "USM ECU: a227 eeprom prog buys";
CM_ SG_ 1520 USM_a227_vsupVoltOutOfRange "USM ECU: a227 vsup volt out of range";
CM_ SG_ 1520 USM_a227_tempSensOutOfRange "USM ECU: a227 temp sens out of range";
CM_ SG_ 1520 USM_a227_underVoltAtVtankDuringB "USM ECU: a227 under volt at vtank during burst";
CM_ SG_ 1520 USM_a227_overVoltAtVtankDuringBu "USM ECU: a227 over volt at vtank during burst";
CM_ SG_ 1520 USM_a227_drvsFailDuringBurst "USM ECU: a227 drvs fail during burst";
CM_ SG_ 1520 USM_a227_drv1FailDuringBurst "USM ECU: a227 drv1 fail during burst";
CM_ SG_ 1520 USM_a227_drv2FailDuringBurst "USM ECU: a227 drv2 fail during burst";
CM_ SG_ 1520 USM_a227_crcMismatchInRam "USM ECU: a227 crc mismatch in ram";
CM_ SG_ 1520 USM_a227_verificationOfConfigAnd "USM ECU: a227 verification of config and calc params fail";
CM_ SG_ 1520 USM_a227_wdgClockFreqOutOfRange "USM ECU: a227 wdg clock freq out of range";
CM_ SG_ 1520 USM_a227_atgNoiseMeasOutOfRange "USM ECU: a227 atg noise meas out of range";
CM_ SG_ 1520 USM_a227_syncCountError "USM ECU: a227 sync count error";
CM_ SG_ 1520 USM_a227_invalidStartEdge "USM ECU: a227 invalid start edge";
CM_ SG_ 1520 USM_a227_receiverReachedErrorSta "USM ECU: a227 receiver reached error state";
CM_ SG_ 1520 USM_a227_pdcmPulseInvalid "USM ECU: a227 pdcm pulse invalid";
CM_ SG_ 1520 USM_a227_crcOfReceivedCmdInvalid "USM ECU: a227 crc of received cmd invalid";
CM_ SG_ 1520 USM_a227_passwordWrong "USM ECU: a227 password wrong";
CM_ SG_ 1520 USM_a227_timeIntBetween2PulsesEr "USM ECU: a227 time int between2 pulses err";
CM_ SG_ 1520 USM_a227_numInvalidStartEdgeSinc "USM ECU: a227 num invalid start edge since init";
CM_ SG_ 1520 USM_a227_numAtgNoiseErrorsSinceI "USM ECU: a227 num atg noise errors since init";
CM_ SG_ 1520 USM_a228_reset "USM ECU: a228 reset";
CM_ SG_ 1520 USM_a228_otpCrcError "USM ECU: a228 otp crc error";
CM_ SG_ 1520 USM_a228_trimRegParityErr "USM ECU: a228 trim reg parity err";
CM_ SG_ 1520 USM_a228_sramParityErr "USM ECU: a228 sram parity err";
CM_ SG_ 1520 USM_a228_crcMismatchInOtp "USM ECU: a228 crc mismatch in otp";
CM_ SG_ 1520 USM_a228_crcMismatchInSysrom "USM ECU: a228 crc mismatch in sysrom";
CM_ SG_ 1520 USM_a228_crcMismatchInEeprom "USM ECU: a228 crc mismatch in eeprom";
CM_ SG_ 1520 USM_a228_capLossVdddOutOfRange "USM ECU: a228 cap loss vddd out of range";
CM_ SG_ 1520 USM_a228_capLossVddaOutOfRange "USM ECU: a228 cap loss vdda out of range";
CM_ SG_ 1520 USM_a228_referenceVoltOutOfRange "USM ECU: a228 reference volt out of range";
CM_ SG_ 1520 USM_a228_vdddVoltOutOfRange "USM ECU: a228 vddd volt out of range";
CM_ SG_ 1520 USM_a228_vrefVoldOfOtpOutOfRange "USM ECU: a228 vref vold of otp out of range";
CM_ SG_ 1520 USM_a228_eepromProgFail "USM ECU: a228 eeprom prog fail";
CM_ SG_ 1520 USM_a228_eepromProgBuys "USM ECU: a228 eeprom prog buys";
CM_ SG_ 1520 USM_a228_vsupVoltOutOfRange "USM ECU: a228 vsup volt out of range";
CM_ SG_ 1520 USM_a228_tempSensOutOfRange "USM ECU: a228 temp sens out of range";
CM_ SG_ 1520 USM_a228_underVoltAtVtankDuringB "USM ECU: a228 under volt at vtank during burst";
CM_ SG_ 1520 USM_a228_overVoltAtVtankDuringBu "USM ECU: a228 over volt at vtank during burst";
CM_ SG_ 1520 USM_a228_drvsFailDuringBurst "USM ECU: a228 drvs fail during burst";
CM_ SG_ 1520 USM_a228_drv1FailDuringBurst "USM ECU: a228 drv1 fail during burst";
CM_ SG_ 1520 USM_a228_drv2FailDuringBurst "USM ECU: a228 drv2 fail during burst";
CM_ SG_ 1520 USM_a228_crcMismatchInRam "USM ECU: a228 crc mismatch in ram";
CM_ SG_ 1520 USM_a228_verificationOfConfigAnd "USM ECU: a228 verification of config and calc params fail";
CM_ SG_ 1520 USM_a228_wdgClockFreqOutOfRange "USM ECU: a228 wdg clock freq out of range";
CM_ SG_ 1520 USM_a228_atgNoiseMeasOutOfRange "USM ECU: a228 atg noise meas out of range";
CM_ SG_ 1520 USM_a228_syncCountError "USM ECU: a228 sync count error";
CM_ SG_ 1520 USM_a228_invalidStartEdge "USM ECU: a228 invalid start edge";
CM_ SG_ 1520 USM_a228_receiverReachedErrorSta "USM ECU: a228 receiver reached error state";
CM_ SG_ 1520 USM_a228_pdcmPulseInvalid "USM ECU: a228 pdcm pulse invalid";
CM_ SG_ 1520 USM_a228_crcOfReceivedCmdInvalid "USM ECU: a228 crc of received cmd invalid";
CM_ SG_ 1520 USM_a228_passwordWrong "USM ECU: a228 password wrong";
CM_ SG_ 1520 USM_a228_timeIntBetween2PulsesEr "USM ECU: a228 time int between2 pulses err";
CM_ SG_ 1520 USM_a228_numInvalidStartEdgeSinc "USM ECU: a228 num invalid start edge since init";
CM_ SG_ 1520 USM_a228_numAtgNoiseErrorsSinceI "USM ECU: a228 num atg noise errors since init";
CM_ SG_ 1520 USM_a229_reset "USM ECU: a229 reset";
CM_ SG_ 1520 USM_a229_otpCrcError "USM ECU: a229 otp crc error";
CM_ SG_ 1520 USM_a229_trimRegParityErr "USM ECU: a229 trim reg parity err";
CM_ SG_ 1520 USM_a229_sramParityErr "USM ECU: a229 sram parity err";
CM_ SG_ 1520 USM_a229_crcMismatchInOtp "USM ECU: a229 crc mismatch in otp";
CM_ SG_ 1520 USM_a229_crcMismatchInSysrom "USM ECU: a229 crc mismatch in sysrom";
CM_ SG_ 1520 USM_a229_crcMismatchInEeprom "USM ECU: a229 crc mismatch in eeprom";
CM_ SG_ 1520 USM_a229_capLossVdddOutOfRange "USM ECU: a229 cap loss vddd out of range";
CM_ SG_ 1520 USM_a229_capLossVddaOutOfRange "USM ECU: a229 cap loss vdda out of range";
CM_ SG_ 1520 USM_a229_referenceVoltOutOfRange "USM ECU: a229 reference volt out of range";
CM_ SG_ 1520 USM_a229_vdddVoltOutOfRange "USM ECU: a229 vddd volt out of range";
CM_ SG_ 1520 USM_a229_vrefVoldOfOtpOutOfRange "USM ECU: a229 vref vold of otp out of range";
CM_ SG_ 1520 USM_a229_eepromProgFail "USM ECU: a229 eeprom prog fail";
CM_ SG_ 1520 USM_a229_eepromProgBuys "USM ECU: a229 eeprom prog buys";
CM_ SG_ 1520 USM_a229_vsupVoltOutOfRange "USM ECU: a229 vsup volt out of range";
CM_ SG_ 1520 USM_a229_tempSensOutOfRange "USM ECU: a229 temp sens out of range";
CM_ SG_ 1520 USM_a229_underVoltAtVtankDuringB "USM ECU: a229 under volt at vtank during burst";
CM_ SG_ 1520 USM_a229_overVoltAtVtankDuringBu "USM ECU: a229 over volt at vtank during burst";
CM_ SG_ 1520 USM_a229_drvsFailDuringBurst "USM ECU: a229 drvs fail during burst";
CM_ SG_ 1520 USM_a229_drv1FailDuringBurst "USM ECU: a229 drv1 fail during burst";
CM_ SG_ 1520 USM_a229_drv2FailDuringBurst "USM ECU: a229 drv2 fail during burst";
CM_ SG_ 1520 USM_a229_crcMismatchInRam "USM ECU: a229 crc mismatch in ram";
CM_ SG_ 1520 USM_a229_verificationOfConfigAnd "USM ECU: a229 verification of config and calc params fail";
CM_ SG_ 1520 USM_a229_wdgClockFreqOutOfRange "USM ECU: a229 wdg clock freq out of range";
CM_ SG_ 1520 USM_a229_atgNoiseMeasOutOfRange "USM ECU: a229 atg noise meas out of range";
CM_ SG_ 1520 USM_a229_syncCountError "USM ECU: a229 sync count error";
CM_ SG_ 1520 USM_a229_invalidStartEdge "USM ECU: a229 invalid start edge";
CM_ SG_ 1520 USM_a229_receiverReachedErrorSta "USM ECU: a229 receiver reached error state";
CM_ SG_ 1520 USM_a229_pdcmPulseInvalid "USM ECU: a229 pdcm pulse invalid";
CM_ SG_ 1520 USM_a229_crcOfReceivedCmdInvalid "USM ECU: a229 crc of received cmd invalid";
CM_ SG_ 1520 USM_a229_passwordWrong "USM ECU: a229 password wrong";
CM_ SG_ 1520 USM_a229_timeIntBetween2PulsesEr "USM ECU: a229 time int between2 pulses err";
CM_ SG_ 1520 USM_a229_numInvalidStartEdgeSinc "USM ECU: a229 num invalid start edge since init";
CM_ SG_ 1520 USM_a229_numAtgNoiseErrorsSinceI "USM ECU: a229 num atg noise errors since init";
CM_ SG_ 1520 USM_a230_reset "USM ECU: a230 reset";
CM_ SG_ 1520 USM_a230_otpCrcError "USM ECU: a230 otp crc error";
CM_ SG_ 1520 USM_a230_trimRegParityErr "USM ECU: a230 trim reg parity err";
CM_ SG_ 1520 USM_a230_sramParityErr "USM ECU: a230 sram parity err";
CM_ SG_ 1520 USM_a230_crcMismatchInOtp "USM ECU: a230 crc mismatch in otp";
CM_ SG_ 1520 USM_a230_crcMismatchInSysrom "USM ECU: a230 crc mismatch in sysrom";
CM_ SG_ 1520 USM_a230_crcMismatchInEeprom "USM ECU: a230 crc mismatch in eeprom";
CM_ SG_ 1520 USM_a230_capLossVdddOutOfRange "USM ECU: a230 cap loss vddd out of range";
CM_ SG_ 1520 USM_a230_capLossVddaOutOfRange "USM ECU: a230 cap loss vdda out of range";
CM_ SG_ 1520 USM_a230_referenceVoltOutOfRange "USM ECU: a230 reference volt out of range";
CM_ SG_ 1520 USM_a230_vdddVoltOutOfRange "USM ECU: a230 vddd volt out of range";
CM_ SG_ 1520 USM_a230_vrefVoldOfOtpOutOfRange "USM ECU: a230 vref vold of otp out of range";
CM_ SG_ 1520 USM_a230_eepromProgFail "USM ECU: a230 eeprom prog fail";
CM_ SG_ 1520 USM_a230_eepromProgBuys "USM ECU: a230 eeprom prog buys";
CM_ SG_ 1520 USM_a230_vsupVoltOutOfRange "USM ECU: a230 vsup volt out of range";
CM_ SG_ 1520 USM_a230_tempSensOutOfRange "USM ECU: a230 temp sens out of range";
CM_ SG_ 1520 USM_a230_underVoltAtVtankDuringB "USM ECU: a230 under volt at vtank during burst";
CM_ SG_ 1520 USM_a230_overVoltAtVtankDuringBu "USM ECU: a230 over volt at vtank during burst";
CM_ SG_ 1520 USM_a230_drvsFailDuringBurst "USM ECU: a230 drvs fail during burst";
CM_ SG_ 1520 USM_a230_drv1FailDuringBurst "USM ECU: a230 drv1 fail during burst";
CM_ SG_ 1520 USM_a230_drv2FailDuringBurst "USM ECU: a230 drv2 fail during burst";
CM_ SG_ 1520 USM_a230_crcMismatchInRam "USM ECU: a230 crc mismatch in ram";
CM_ SG_ 1520 USM_a230_verificationOfConfigAnd "USM ECU: a230 verification of config and calc params fail";
CM_ SG_ 1520 USM_a230_wdgClockFreqOutOfRange "USM ECU: a230 wdg clock freq out of range";
CM_ SG_ 1520 USM_a230_atgNoiseMeasOutOfRange "USM ECU: a230 atg noise meas out of range";
CM_ SG_ 1520 USM_a230_syncCountError "USM ECU: a230 sync count error";
CM_ SG_ 1520 USM_a230_invalidStartEdge "USM ECU: a230 invalid start edge";
CM_ SG_ 1520 USM_a230_receiverReachedErrorSta "USM ECU: a230 receiver reached error state";
CM_ SG_ 1520 USM_a230_pdcmPulseInvalid "USM ECU: a230 pdcm pulse invalid";
CM_ SG_ 1520 USM_a230_crcOfReceivedCmdInvalid "USM ECU: a230 crc of received cmd invalid";
CM_ SG_ 1520 USM_a230_passwordWrong "USM ECU: a230 password wrong";
CM_ SG_ 1520 USM_a230_timeIntBetween2PulsesEr "USM ECU: a230 time int between2 pulses err";
CM_ SG_ 1520 USM_a230_numInvalidStartEdgeSinc "USM ECU: a230 num invalid start edge since init";
CM_ SG_ 1520 USM_a230_numAtgNoiseErrorsSinceI "USM ECU: a230 num atg noise errors since init";
CM_ SG_ 1520 USM_a231_reset "USM ECU: a231 reset";
CM_ SG_ 1520 USM_a231_otpCrcError "USM ECU: a231 otp crc error";
CM_ SG_ 1520 USM_a231_trimRegParityErr "USM ECU: a231 trim reg parity err";
CM_ SG_ 1520 USM_a231_sramParityErr "USM ECU: a231 sram parity err";
CM_ SG_ 1520 USM_a231_crcMismatchInOtp "USM ECU: a231 crc mismatch in otp";
CM_ SG_ 1520 USM_a231_crcMismatchInSysrom "USM ECU: a231 crc mismatch in sysrom";
CM_ SG_ 1520 USM_a231_crcMismatchInEeprom "USM ECU: a231 crc mismatch in eeprom";
CM_ SG_ 1520 USM_a231_capLossVdddOutOfRange "USM ECU: a231 cap loss vddd out of range";
CM_ SG_ 1520 USM_a231_capLossVddaOutOfRange "USM ECU: a231 cap loss vdda out of range";
CM_ SG_ 1520 USM_a231_referenceVoltOutOfRange "USM ECU: a231 reference volt out of range";
CM_ SG_ 1520 USM_a231_vdddVoltOutOfRange "USM ECU: a231 vddd volt out of range";
CM_ SG_ 1520 USM_a231_vrefVoldOfOtpOutOfRange "USM ECU: a231 vref vold of otp out of range";
CM_ SG_ 1520 USM_a231_eepromProgFail "USM ECU: a231 eeprom prog fail";
CM_ SG_ 1520 USM_a231_eepromProgBuys "USM ECU: a231 eeprom prog buys";
CM_ SG_ 1520 USM_a231_vsupVoltOutOfRange "USM ECU: a231 vsup volt out of range";
CM_ SG_ 1520 USM_a231_tempSensOutOfRange "USM ECU: a231 temp sens out of range";
CM_ SG_ 1520 USM_a231_underVoltAtVtankDuringB "USM ECU: a231 under volt at vtank during burst";
CM_ SG_ 1520 USM_a231_overVoltAtVtankDuringBu "USM ECU: a231 over volt at vtank during burst";
CM_ SG_ 1520 USM_a231_drvsFailDuringBurst "USM ECU: a231 drvs fail during burst";
CM_ SG_ 1520 USM_a231_drv1FailDuringBurst "USM ECU: a231 drv1 fail during burst";
CM_ SG_ 1520 USM_a231_drv2FailDuringBurst "USM ECU: a231 drv2 fail during burst";
CM_ SG_ 1520 USM_a231_crcMismatchInRam "USM ECU: a231 crc mismatch in ram";
CM_ SG_ 1520 USM_a231_verificationOfConfigAnd "USM ECU: a231 verification of config and calc params fail";
CM_ SG_ 1520 USM_a231_wdgClockFreqOutOfRange "USM ECU: a231 wdg clock freq out of range";
CM_ SG_ 1520 USM_a231_atgNoiseMeasOutOfRange "USM ECU: a231 atg noise meas out of range";
CM_ SG_ 1520 USM_a231_syncCountError "USM ECU: a231 sync count error";
CM_ SG_ 1520 USM_a231_invalidStartEdge "USM ECU: a231 invalid start edge";
CM_ SG_ 1520 USM_a231_receiverReachedErrorSta "USM ECU: a231 receiver reached error state";
CM_ SG_ 1520 USM_a231_pdcmPulseInvalid "USM ECU: a231 pdcm pulse invalid";
CM_ SG_ 1520 USM_a231_crcOfReceivedCmdInvalid "USM ECU: a231 crc of received cmd invalid";
CM_ SG_ 1520 USM_a231_passwordWrong "USM ECU: a231 password wrong";
CM_ SG_ 1520 USM_a231_timeIntBetween2PulsesEr "USM ECU: a231 time int between2 pulses err";
CM_ SG_ 1520 USM_a231_numInvalidStartEdgeSinc "USM ECU: a231 num invalid start edge since init";
CM_ SG_ 1520 USM_a231_numAtgNoiseErrorsSinceI "USM ECU: a231 num atg noise errors since init";
CM_ SG_ 1520 USM_a232_reset "USM ECU: a232 reset";
CM_ SG_ 1520 USM_a232_otpCrcError "USM ECU: a232 otp crc error";
CM_ SG_ 1520 USM_a232_trimRegParityErr "USM ECU: a232 trim reg parity err";
CM_ SG_ 1520 USM_a232_sramParityErr "USM ECU: a232 sram parity err";
CM_ SG_ 1520 USM_a232_crcMismatchInOtp "USM ECU: a232 crc mismatch in otp";
CM_ SG_ 1520 USM_a232_crcMismatchInSysrom "USM ECU: a232 crc mismatch in sysrom";
CM_ SG_ 1520 USM_a232_crcMismatchInEeprom "USM ECU: a232 crc mismatch in eeprom";
CM_ SG_ 1520 USM_a232_capLossVdddOutOfRange "USM ECU: a232 cap loss vddd out of range";
CM_ SG_ 1520 USM_a232_capLossVddaOutOfRange "USM ECU: a232 cap loss vdda out of range";
CM_ SG_ 1520 USM_a232_referenceVoltOutOfRange "USM ECU: a232 reference volt out of range";
CM_ SG_ 1520 USM_a232_vdddVoltOutOfRange "USM ECU: a232 vddd volt out of range";
CM_ SG_ 1520 USM_a232_vrefVoldOfOtpOutOfRange "USM ECU: a232 vref vold of otp out of range";
CM_ SG_ 1520 USM_a232_eepromProgFail "USM ECU: a232 eeprom prog fail";
CM_ SG_ 1520 USM_a232_eepromProgBuys "USM ECU: a232 eeprom prog buys";
CM_ SG_ 1520 USM_a232_vsupVoltOutOfRange "USM ECU: a232 vsup volt out of range";
CM_ SG_ 1520 USM_a232_tempSensOutOfRange "USM ECU: a232 temp sens out of range";
CM_ SG_ 1520 USM_a232_underVoltAtVtankDuringB "USM ECU: a232 under volt at vtank during burst";
CM_ SG_ 1520 USM_a232_overVoltAtVtankDuringBu "USM ECU: a232 over volt at vtank during burst";
CM_ SG_ 1520 USM_a232_drvsFailDuringBurst "USM ECU: a232 drvs fail during burst";
CM_ SG_ 1520 USM_a232_drv1FailDuringBurst "USM ECU: a232 drv1 fail during burst";
CM_ SG_ 1520 USM_a232_drv2FailDuringBurst "USM ECU: a232 drv2 fail during burst";
CM_ SG_ 1520 USM_a232_crcMismatchInRam "USM ECU: a232 crc mismatch in ram";
CM_ SG_ 1520 USM_a232_verificationOfConfigAnd "USM ECU: a232 verification of config and calc params fail";
CM_ SG_ 1520 USM_a232_wdgClockFreqOutOfRange "USM ECU: a232 wdg clock freq out of range";
CM_ SG_ 1520 USM_a232_atgNoiseMeasOutOfRange "USM ECU: a232 atg noise meas out of range";
CM_ SG_ 1520 USM_a232_syncCountError "USM ECU: a232 sync count error";
CM_ SG_ 1520 USM_a232_invalidStartEdge "USM ECU: a232 invalid start edge";
CM_ SG_ 1520 USM_a232_receiverReachedErrorSta "USM ECU: a232 receiver reached error state";
CM_ SG_ 1520 USM_a232_pdcmPulseInvalid "USM ECU: a232 pdcm pulse invalid";
CM_ SG_ 1520 USM_a232_crcOfReceivedCmdInvalid "USM ECU: a232 crc of received cmd invalid";
CM_ SG_ 1520 USM_a232_passwordWrong "USM ECU: a232 password wrong";
CM_ SG_ 1520 USM_a232_timeIntBetween2PulsesEr "USM ECU: a232 time int between2 pulses err";
CM_ SG_ 1520 USM_a232_numInvalidStartEdgeSinc "USM ECU: a232 num invalid start edge since init";
CM_ SG_ 1520 USM_a232_numAtgNoiseErrorsSinceI "USM ECU: a232 num atg noise errors since init";
CM_ SG_ 1520 USM_a233_reset "USM ECU: a233 reset";
CM_ SG_ 1520 USM_a233_otpCrcError "USM ECU: a233 otp crc error";
CM_ SG_ 1520 USM_a233_trimRegParityErr "USM ECU: a233 trim reg parity err";
CM_ SG_ 1520 USM_a233_sramParityErr "USM ECU: a233 sram parity err";
CM_ SG_ 1520 USM_a233_crcMismatchInOtp "USM ECU: a233 crc mismatch in otp";
CM_ SG_ 1520 USM_a233_crcMismatchInSysrom "USM ECU: a233 crc mismatch in sysrom";
CM_ SG_ 1520 USM_a233_crcMismatchInEeprom "USM ECU: a233 crc mismatch in eeprom";
CM_ SG_ 1520 USM_a233_capLossVdddOutOfRange "USM ECU: a233 cap loss vddd out of range";
CM_ SG_ 1520 USM_a233_capLossVddaOutOfRange "USM ECU: a233 cap loss vdda out of range";
CM_ SG_ 1520 USM_a233_referenceVoltOutOfRange "USM ECU: a233 reference volt out of range";
CM_ SG_ 1520 USM_a233_vdddVoltOutOfRange "USM ECU: a233 vddd volt out of range";
CM_ SG_ 1520 USM_a233_vrefVoldOfOtpOutOfRange "USM ECU: a233 vref vold of otp out of range";
CM_ SG_ 1520 USM_a233_eepromProgFail "USM ECU: a233 eeprom prog fail";
CM_ SG_ 1520 USM_a233_eepromProgBuys "USM ECU: a233 eeprom prog buys";
CM_ SG_ 1520 USM_a233_vsupVoltOutOfRange "USM ECU: a233 vsup volt out of range";
CM_ SG_ 1520 USM_a233_tempSensOutOfRange "USM ECU: a233 temp sens out of range";
CM_ SG_ 1520 USM_a233_underVoltAtVtankDuringB "USM ECU: a233 under volt at vtank during burst";
CM_ SG_ 1520 USM_a233_overVoltAtVtankDuringBu "USM ECU: a233 over volt at vtank during burst";
CM_ SG_ 1520 USM_a233_drvsFailDuringBurst "USM ECU: a233 drvs fail during burst";
CM_ SG_ 1520 USM_a233_drv1FailDuringBurst "USM ECU: a233 drv1 fail during burst";
CM_ SG_ 1520 USM_a233_drv2FailDuringBurst "USM ECU: a233 drv2 fail during burst";
CM_ SG_ 1520 USM_a233_crcMismatchInRam "USM ECU: a233 crc mismatch in ram";
CM_ SG_ 1520 USM_a233_verificationOfConfigAnd "USM ECU: a233 verification of config and calc params fail";
CM_ SG_ 1520 USM_a233_wdgClockFreqOutOfRange "USM ECU: a233 wdg clock freq out of range";
CM_ SG_ 1520 USM_a233_atgNoiseMeasOutOfRange "USM ECU: a233 atg noise meas out of range";
CM_ SG_ 1520 USM_a233_syncCountError "USM ECU: a233 sync count error";
CM_ SG_ 1520 USM_a233_invalidStartEdge "USM ECU: a233 invalid start edge";
CM_ SG_ 1520 USM_a233_receiverReachedErrorSta "USM ECU: a233 receiver reached error state";
CM_ SG_ 1520 USM_a233_pdcmPulseInvalid "USM ECU: a233 pdcm pulse invalid";
CM_ SG_ 1520 USM_a233_crcOfReceivedCmdInvalid "USM ECU: a233 crc of received cmd invalid";
CM_ SG_ 1520 USM_a233_passwordWrong "USM ECU: a233 password wrong";
CM_ SG_ 1520 USM_a233_timeIntBetween2PulsesEr "USM ECU: a233 time int between2 pulses err";
CM_ SG_ 1520 USM_a233_numInvalidStartEdgeSinc "USM ECU: a233 num invalid start edge since init";
CM_ SG_ 1520 USM_a233_numAtgNoiseErrorsSinceI "USM ECU: a233 num atg noise errors since init";
CM_ SG_ 1520 USM_a234_reset "USM ECU: a234 reset";
CM_ SG_ 1520 USM_a234_otpCrcError "USM ECU: a234 otp crc error";
CM_ SG_ 1520 USM_a234_trimRegParityErr "USM ECU: a234 trim reg parity err";
CM_ SG_ 1520 USM_a234_sramParityErr "USM ECU: a234 sram parity err";
CM_ SG_ 1520 USM_a234_crcMismatchInOtp "USM ECU: a234 crc mismatch in otp";
CM_ SG_ 1520 USM_a234_crcMismatchInSysrom "USM ECU: a234 crc mismatch in sysrom";
CM_ SG_ 1520 USM_a234_crcMismatchInEeprom "USM ECU: a234 crc mismatch in eeprom";
CM_ SG_ 1520 USM_a234_capLossVdddOutOfRange "USM ECU: a234 cap loss vddd out of range";
CM_ SG_ 1520 USM_a234_capLossVddaOutOfRange "USM ECU: a234 cap loss vdda out of range";
CM_ SG_ 1520 USM_a234_referenceVoltOutOfRange "USM ECU: a234 reference volt out of range";
CM_ SG_ 1520 USM_a234_vdddVoltOutOfRange "USM ECU: a234 vddd volt out of range";
CM_ SG_ 1520 USM_a234_vrefVoldOfOtpOutOfRange "USM ECU: a234 vref vold of otp out of range";
CM_ SG_ 1520 USM_a234_eepromProgFail "USM ECU: a234 eeprom prog fail";
CM_ SG_ 1520 USM_a234_eepromProgBuys "USM ECU: a234 eeprom prog buys";
CM_ SG_ 1520 USM_a234_vsupVoltOutOfRange "USM ECU: a234 vsup volt out of range";
CM_ SG_ 1520 USM_a234_tempSensOutOfRange "USM ECU: a234 temp sens out of range";
CM_ SG_ 1520 USM_a234_underVoltAtVtankDuringB "USM ECU: a234 under volt at vtank during burst";
CM_ SG_ 1520 USM_a234_overVoltAtVtankDuringBu "USM ECU: a234 over volt at vtank during burst";
CM_ SG_ 1520 USM_a234_drvsFailDuringBurst "USM ECU: a234 drvs fail during burst";
CM_ SG_ 1520 USM_a234_drv1FailDuringBurst "USM ECU: a234 drv1 fail during burst";
CM_ SG_ 1520 USM_a234_drv2FailDuringBurst "USM ECU: a234 drv2 fail during burst";
CM_ SG_ 1520 USM_a234_crcMismatchInRam "USM ECU: a234 crc mismatch in ram";
CM_ SG_ 1520 USM_a234_verificationOfConfigAnd "USM ECU: a234 verification of config and calc params fail";
CM_ SG_ 1520 USM_a234_wdgClockFreqOutOfRange "USM ECU: a234 wdg clock freq out of range";
CM_ SG_ 1520 USM_a234_atgNoiseMeasOutOfRange "USM ECU: a234 atg noise meas out of range";
CM_ SG_ 1520 USM_a234_syncCountError "USM ECU: a234 sync count error";
CM_ SG_ 1520 USM_a234_invalidStartEdge "USM ECU: a234 invalid start edge";
CM_ SG_ 1520 USM_a234_receiverReachedErrorSta "USM ECU: a234 receiver reached error state";
CM_ SG_ 1520 USM_a234_pdcmPulseInvalid "USM ECU: a234 pdcm pulse invalid";
CM_ SG_ 1520 USM_a234_crcOfReceivedCmdInvalid "USM ECU: a234 crc of received cmd invalid";
CM_ SG_ 1520 USM_a234_passwordWrong "USM ECU: a234 password wrong";
CM_ SG_ 1520 USM_a234_timeIntBetween2PulsesEr "USM ECU: a234 time int between2 pulses err";
CM_ SG_ 1520 USM_a234_numInvalidStartEdgeSinc "USM ECU: a234 num invalid start edge since init";
CM_ SG_ 1520 USM_a234_numAtgNoiseErrorsSinceI "USM ECU: a234 num atg noise errors since init";
CM_ SG_ 1520 USM_a235_reset "USM ECU: a235 reset";
CM_ SG_ 1520 USM_a235_otpCrcError "USM ECU: a235 otp crc error";
CM_ SG_ 1520 USM_a235_trimRegParityErr "USM ECU: a235 trim reg parity err";
CM_ SG_ 1520 USM_a235_sramParityErr "USM ECU: a235 sram parity err";
CM_ SG_ 1520 USM_a235_crcMismatchInOtp "USM ECU: a235 crc mismatch in otp";
CM_ SG_ 1520 USM_a235_crcMismatchInSysrom "USM ECU: a235 crc mismatch in sysrom";
CM_ SG_ 1520 USM_a235_crcMismatchInEeprom "USM ECU: a235 crc mismatch in eeprom";
CM_ SG_ 1520 USM_a235_capLossVdddOutOfRange "USM ECU: a235 cap loss vddd out of range";
CM_ SG_ 1520 USM_a235_capLossVddaOutOfRange "USM ECU: a235 cap loss vdda out of range";
CM_ SG_ 1520 USM_a235_referenceVoltOutOfRange "USM ECU: a235 reference volt out of range";
CM_ SG_ 1520 USM_a235_vdddVoltOutOfRange "USM ECU: a235 vddd volt out of range";
CM_ SG_ 1520 USM_a235_vrefVoldOfOtpOutOfRange "USM ECU: a235 vref vold of otp out of range";
CM_ SG_ 1520 USM_a235_eepromProgFail "USM ECU: a235 eeprom prog fail";
CM_ SG_ 1520 USM_a235_eepromProgBuys "USM ECU: a235 eeprom prog buys";
CM_ SG_ 1520 USM_a235_vsupVoltOutOfRange "USM ECU: a235 vsup volt out of range";
CM_ SG_ 1520 USM_a235_tempSensOutOfRange "USM ECU: a235 temp sens out of range";
CM_ SG_ 1520 USM_a235_underVoltAtVtankDuringB "USM ECU: a235 under volt at vtank during burst";
CM_ SG_ 1520 USM_a235_overVoltAtVtankDuringBu "USM ECU: a235 over volt at vtank during burst";
CM_ SG_ 1520 USM_a235_drvsFailDuringBurst "USM ECU: a235 drvs fail during burst";
CM_ SG_ 1520 USM_a235_drv1FailDuringBurst "USM ECU: a235 drv1 fail during burst";
CM_ SG_ 1520 USM_a235_drv2FailDuringBurst "USM ECU: a235 drv2 fail during burst";
CM_ SG_ 1520 USM_a235_crcMismatchInRam "USM ECU: a235 crc mismatch in ram";
CM_ SG_ 1520 USM_a235_verificationOfConfigAnd "USM ECU: a235 verification of config and calc params fail";
CM_ SG_ 1520 USM_a235_wdgClockFreqOutOfRange "USM ECU: a235 wdg clock freq out of range";
CM_ SG_ 1520 USM_a235_atgNoiseMeasOutOfRange "USM ECU: a235 atg noise meas out of range";
CM_ SG_ 1520 USM_a235_syncCountError "USM ECU: a235 sync count error";
CM_ SG_ 1520 USM_a235_invalidStartEdge "USM ECU: a235 invalid start edge";
CM_ SG_ 1520 USM_a235_receiverReachedErrorSta "USM ECU: a235 receiver reached error state";
CM_ SG_ 1520 USM_a235_pdcmPulseInvalid "USM ECU: a235 pdcm pulse invalid";
CM_ SG_ 1520 USM_a235_crcOfReceivedCmdInvalid "USM ECU: a235 crc of received cmd invalid";
CM_ SG_ 1520 USM_a235_passwordWrong "USM ECU: a235 password wrong";
CM_ SG_ 1520 USM_a235_timeIntBetween2PulsesEr "USM ECU: a235 time int between2 pulses err";
CM_ SG_ 1520 USM_a235_numInvalidStartEdgeSinc "USM ECU: a235 num invalid start edge since init";
CM_ SG_ 1520 USM_a235_numAtgNoiseErrorsSinceI "USM ECU: a235 num atg noise errors since init";
CM_ SG_ 1520 USM_a236_reset "USM ECU: a236 reset";
CM_ SG_ 1520 USM_a236_otpCrcError "USM ECU: a236 otp crc error";
CM_ SG_ 1520 USM_a236_trimRegParityErr "USM ECU: a236 trim reg parity err";
CM_ SG_ 1520 USM_a236_sramParityErr "USM ECU: a236 sram parity err";
CM_ SG_ 1520 USM_a236_crcMismatchInOtp "USM ECU: a236 crc mismatch in otp";
CM_ SG_ 1520 USM_a236_crcMismatchInSysrom "USM ECU: a236 crc mismatch in sysrom";
CM_ SG_ 1520 USM_a236_crcMismatchInEeprom "USM ECU: a236 crc mismatch in eeprom";
CM_ SG_ 1520 USM_a236_capLossVdddOutOfRange "USM ECU: a236 cap loss vddd out of range";
CM_ SG_ 1520 USM_a236_capLossVddaOutOfRange "USM ECU: a236 cap loss vdda out of range";
CM_ SG_ 1520 USM_a236_referenceVoltOutOfRange "USM ECU: a236 reference volt out of range";
CM_ SG_ 1520 USM_a236_vdddVoltOutOfRange "USM ECU: a236 vddd volt out of range";
CM_ SG_ 1520 USM_a236_vrefVoldOfOtpOutOfRange "USM ECU: a236 vref vold of otp out of range";
CM_ SG_ 1520 USM_a236_eepromProgFail "USM ECU: a236 eeprom prog fail";
CM_ SG_ 1520 USM_a236_eepromProgBuys "USM ECU: a236 eeprom prog buys";
CM_ SG_ 1520 USM_a236_vsupVoltOutOfRange "USM ECU: a236 vsup volt out of range";
CM_ SG_ 1520 USM_a236_tempSensOutOfRange "USM ECU: a236 temp sens out of range";
CM_ SG_ 1520 USM_a236_underVoltAtVtankDuringB "USM ECU: a236 under volt at vtank during burst";
CM_ SG_ 1520 USM_a236_overVoltAtVtankDuringBu "USM ECU: a236 over volt at vtank during burst";
CM_ SG_ 1520 USM_a236_drvsFailDuringBurst "USM ECU: a236 drvs fail during burst";
CM_ SG_ 1520 USM_a236_drv1FailDuringBurst "USM ECU: a236 drv1 fail during burst";
CM_ SG_ 1520 USM_a236_drv2FailDuringBurst "USM ECU: a236 drv2 fail during burst";
CM_ SG_ 1520 USM_a236_crcMismatchInRam "USM ECU: a236 crc mismatch in ram";
CM_ SG_ 1520 USM_a236_verificationOfConfigAnd "USM ECU: a236 verification of config and calc params fail";
CM_ SG_ 1520 USM_a236_wdgClockFreqOutOfRange "USM ECU: a236 wdg clock freq out of range";
CM_ SG_ 1520 USM_a236_atgNoiseMeasOutOfRange "USM ECU: a236 atg noise meas out of range";
CM_ SG_ 1520 USM_a236_syncCountError "USM ECU: a236 sync count error";
CM_ SG_ 1520 USM_a236_invalidStartEdge "USM ECU: a236 invalid start edge";
CM_ SG_ 1520 USM_a236_receiverReachedErrorSta "USM ECU: a236 receiver reached error state";
CM_ SG_ 1520 USM_a236_pdcmPulseInvalid "USM ECU: a236 pdcm pulse invalid";
CM_ SG_ 1520 USM_a236_crcOfReceivedCmdInvalid "USM ECU: a236 crc of received cmd invalid";
CM_ SG_ 1520 USM_a236_passwordWrong "USM ECU: a236 password wrong";
CM_ SG_ 1520 USM_a236_timeIntBetween2PulsesEr "USM ECU: a236 time int between2 pulses err";
CM_ SG_ 1520 USM_a236_numInvalidStartEdgeSinc "USM ECU: a236 num invalid start edge since init";
CM_ SG_ 1520 USM_a236_numAtgNoiseErrorsSinceI "USM ECU: a236 num atg noise errors since init";
CM_ SG_ 1520 USM_a237_reset "USM ECU: a237 reset";
CM_ SG_ 1520 USM_a237_otpCrcError "USM ECU: a237 otp crc error";
CM_ SG_ 1520 USM_a237_trimRegParityErr "USM ECU: a237 trim reg parity err";
CM_ SG_ 1520 USM_a237_sramParityErr "USM ECU: a237 sram parity err";
CM_ SG_ 1520 USM_a237_crcMismatchInOtp "USM ECU: a237 crc mismatch in otp";
CM_ SG_ 1520 USM_a237_crcMismatchInSysrom "USM ECU: a237 crc mismatch in sysrom";
CM_ SG_ 1520 USM_a237_crcMismatchInEeprom "USM ECU: a237 crc mismatch in eeprom";
CM_ SG_ 1520 USM_a237_capLossVdddOutOfRange "USM ECU: a237 cap loss vddd out of range";
CM_ SG_ 1520 USM_a237_capLossVddaOutOfRange "USM ECU: a237 cap loss vdda out of range";
CM_ SG_ 1520 USM_a237_referenceVoltOutOfRange "USM ECU: a237 reference volt out of range";
CM_ SG_ 1520 USM_a237_vdddVoltOutOfRange "USM ECU: a237 vddd volt out of range";
CM_ SG_ 1520 USM_a237_vrefVoldOfOtpOutOfRange "USM ECU: a237 vref vold of otp out of range";
CM_ SG_ 1520 USM_a237_eepromProgFail "USM ECU: a237 eeprom prog fail";
CM_ SG_ 1520 USM_a237_eepromProgBuys "USM ECU: a237 eeprom prog buys";
CM_ SG_ 1520 USM_a237_vsupVoltOutOfRange "USM ECU: a237 vsup volt out of range";
CM_ SG_ 1520 USM_a237_tempSensOutOfRange "USM ECU: a237 temp sens out of range";
CM_ SG_ 1520 USM_a237_underVoltAtVtankDuringB "USM ECU: a237 under volt at vtank during burst";
CM_ SG_ 1520 USM_a237_overVoltAtVtankDuringBu "USM ECU: a237 over volt at vtank during burst";
CM_ SG_ 1520 USM_a237_drvsFailDuringBurst "USM ECU: a237 drvs fail during burst";
CM_ SG_ 1520 USM_a237_drv1FailDuringBurst "USM ECU: a237 drv1 fail during burst";
CM_ SG_ 1520 USM_a237_drv2FailDuringBurst "USM ECU: a237 drv2 fail during burst";
CM_ SG_ 1520 USM_a237_crcMismatchInRam "USM ECU: a237 crc mismatch in ram";
CM_ SG_ 1520 USM_a237_verificationOfConfigAnd "USM ECU: a237 verification of config and calc params fail";
CM_ SG_ 1520 USM_a237_wdgClockFreqOutOfRange "USM ECU: a237 wdg clock freq out of range";
CM_ SG_ 1520 USM_a237_atgNoiseMeasOutOfRange "USM ECU: a237 atg noise meas out of range";
CM_ SG_ 1520 USM_a237_syncCountError "USM ECU: a237 sync count error";
CM_ SG_ 1520 USM_a237_invalidStartEdge "USM ECU: a237 invalid start edge";
CM_ SG_ 1520 USM_a237_receiverReachedErrorSta "USM ECU: a237 receiver reached error state";
CM_ SG_ 1520 USM_a237_pdcmPulseInvalid "USM ECU: a237 pdcm pulse invalid";
CM_ SG_ 1520 USM_a237_crcOfReceivedCmdInvalid "USM ECU: a237 crc of received cmd invalid";
CM_ SG_ 1520 USM_a237_passwordWrong "USM ECU: a237 password wrong";
CM_ SG_ 1520 USM_a237_timeIntBetween2PulsesEr "USM ECU: a237 time int between2 pulses err";
CM_ SG_ 1520 USM_a237_numInvalidStartEdgeSinc "USM ECU: a237 num invalid start edge since init";
CM_ SG_ 1520 USM_a237_numAtgNoiseErrorsSinceI "USM ECU: a237 num atg noise errors since init";
CM_ SG_ 1520 USM_a238_reset "USM ECU: a238 reset";
CM_ SG_ 1520 USM_a238_otpCrcError "USM ECU: a238 otp crc error";
CM_ SG_ 1520 USM_a238_trimRegParityErr "USM ECU: a238 trim reg parity err";
CM_ SG_ 1520 USM_a238_sramParityErr "USM ECU: a238 sram parity err";
CM_ SG_ 1520 USM_a238_crcMismatchInOtp "USM ECU: a238 crc mismatch in otp";
CM_ SG_ 1520 USM_a238_crcMismatchInSysrom "USM ECU: a238 crc mismatch in sysrom";
CM_ SG_ 1520 USM_a238_crcMismatchInEeprom "USM ECU: a238 crc mismatch in eeprom";
CM_ SG_ 1520 USM_a238_capLossVdddOutOfRange "USM ECU: a238 cap loss vddd out of range";
CM_ SG_ 1520 USM_a238_capLossVddaOutOfRange "USM ECU: a238 cap loss vdda out of range";
CM_ SG_ 1520 USM_a238_referenceVoltOutOfRange "USM ECU: a238 reference volt out of range";
CM_ SG_ 1520 USM_a238_vdddVoltOutOfRange "USM ECU: a238 vddd volt out of range";
CM_ SG_ 1520 USM_a238_vrefVoldOfOtpOutOfRange "USM ECU: a238 vref vold of otp out of range";
CM_ SG_ 1520 USM_a238_eepromProgFail "USM ECU: a238 eeprom prog fail";
CM_ SG_ 1520 USM_a238_eepromProgBuys "USM ECU: a238 eeprom prog buys";
CM_ SG_ 1520 USM_a238_vsupVoltOutOfRange "USM ECU: a238 vsup volt out of range";
CM_ SG_ 1520 USM_a238_tempSensOutOfRange "USM ECU: a238 temp sens out of range";
CM_ SG_ 1520 USM_a238_underVoltAtVtankDuringB "USM ECU: a238 under volt at vtank during burst";
CM_ SG_ 1520 USM_a238_overVoltAtVtankDuringBu "USM ECU: a238 over volt at vtank during burst";
CM_ SG_ 1520 USM_a238_drvsFailDuringBurst "USM ECU: a238 drvs fail during burst";
CM_ SG_ 1520 USM_a238_drv1FailDuringBurst "USM ECU: a238 drv1 fail during burst";
CM_ SG_ 1520 USM_a238_drv2FailDuringBurst "USM ECU: a238 drv2 fail during burst";
CM_ SG_ 1520 USM_a238_crcMismatchInRam "USM ECU: a238 crc mismatch in ram";
CM_ SG_ 1520 USM_a238_verificationOfConfigAnd "USM ECU: a238 verification of config and calc params fail";
CM_ SG_ 1520 USM_a238_wdgClockFreqOutOfRange "USM ECU: a238 wdg clock freq out of range";
CM_ SG_ 1520 USM_a238_atgNoiseMeasOutOfRange "USM ECU: a238 atg noise meas out of range";
CM_ SG_ 1520 USM_a238_syncCountError "USM ECU: a238 sync count error";
CM_ SG_ 1520 USM_a238_invalidStartEdge "USM ECU: a238 invalid start edge";
CM_ SG_ 1520 USM_a238_receiverReachedErrorSta "USM ECU: a238 receiver reached error state";
CM_ SG_ 1520 USM_a238_pdcmPulseInvalid "USM ECU: a238 pdcm pulse invalid";
CM_ SG_ 1520 USM_a238_crcOfReceivedCmdInvalid "USM ECU: a238 crc of received cmd invalid";
CM_ SG_ 1520 USM_a238_passwordWrong "USM ECU: a238 password wrong";
CM_ SG_ 1520 USM_a238_timeIntBetween2PulsesEr "USM ECU: a238 time int between2 pulses err";
CM_ SG_ 1520 USM_a238_numInvalidStartEdgeSinc "USM ECU: a238 num invalid start edge since init";
CM_ SG_ 1520 USM_a238_numAtgNoiseErrorsSinceI "USM ECU: a238 num atg noise errors since init";
CM_ BO_ 609 "Front body controller message: 12 v battery status";
CM_ SG_ 609 VCFRONT_12VBatteryStatusIndex "Front body controller: 12 v battery status index";
CM_ SG_ 609 VCFRONT_good12VforUpdate "Indicates the Low Voltage (LV) battery health as it pertains to permitting an Over-The-Air (OTA) update.";
CM_ SG_ 609 VCFRONT_LVLoadRequest "Controls the loading of the Low Voltage (LV) battery for diagnostic purposes.";
CM_ SG_ 609 VCFRONT_12VBatteryStatusCounter "Front body controller: 12 v battery status counter";
CM_ SG_ 609 VCFRONT_12VBatteryStatusChecksum "Front body controller: 12 v battery status checksum";
CM_ SG_ 609 VCFRONT_batterySupportRequest "Reports the request to the Power Conversion System (PCS) to supply power to the Low Voltage (LV) battery.";
CM_ SG_ 609 VCFRONT_batterySMState "Reports the Low Voltage (LV) battery maintenance state machine state.";
CM_ SG_ 609 VCFRONT_eFuseRecoveryStateDBG "Reports the state of the Low Voltage (LV) battery eFuse recovery state machine.";
CM_ SG_ 609 VCFRONT_batteryLINScheduleDBG "Front body controller: battery LIN schedule DBG; raw 7 = signal not available (SNA)";
CM_ SG_ 609 VCFRONT_resistanceEstimationTest "Front body controller: resistance estimation test counter";
CM_ SG_ 609 VCFRONT_IBSCurrent "Electrical current into the 12V battery";
CM_ SG_ 609 VCFRONT_IBSVoltage "Voltage of the 12V battery; raw 4095 = signal not available (SNA)";
CM_ SG_ 609 VCFRONT_reverseBatteryFault "Indicates a fault on the reverse battery eFuse.";
CM_ SG_ 609 VCFRONT_LVBatterySupported "Indicates whether the Low Voltage (LV) battery is being supported.";
CM_ SG_ 609 VCFRONT_LVBatteryCannotSupportVe "Front body controller: LV battery cannot support vehicle";
CM_ SG_ 609 VCFRONT_goodTemp12VforUpdate "Front body controller: good temp12 vfor update";
CM_ SG_ 609 VCFRONT_12VBatteryTargetVoltage "Reports the target Low Voltage (LV) battery voltage.";
CM_ SG_ 609 VCFRONT_IBSTemperature "Front body controller: IBS temperature; raw 2047 = signal not available (SNA)";
CM_ SG_ 609 VCFRONT_currentSensorMismatchLea "Front body controller: current sensor mismatch leaky bkt pct DBG";
CM_ SG_ 609 VCFRONT_LVBatteryEnergyRemaining "Reports the percentage of energy remaining in the Low Voltage (LV) battery.";
CM_ SG_ 609 VCFRONT_LVBatteryStatusForDrive "Indicates the Low Voltage (LV) battery health status as it pertains to drive readiness. May trigger a Graceful Power Off (GPO) and block drive.";
CM_ SG_ 609 VCFRONT_LVBatteryType "Reports the type of Low Voltage (LV) battery that the firmware is configured for.";
CM_ SG_ 609 VCFRONT_resistanceEstimationNeed "Indication that the conditions which require a resistance estimation test to be performed have been met";
CM_ SG_ 609 VCFRONT_IBSVoltageFiltered "Measures the filtered voltage of the Low Voltage (LV) bus; raw 16383 = signal not available (SNA)";
CM_ SG_ 609 VCFRONT_LVBMS_LVBusVoltageSource "Reports the source of the Low Voltage (LV) bus voltage used for the Low Voltage Battery Management System (LVBMS).";
CM_ SG_ 609 VCFRONT_LVBMS_LVPackCurrentSourc "Reports the source of the Low Voltage (LV) pack current used for LV battery charge regulation.";
CM_ SG_ 609 VCFRONT_LVBatterySupportRqrdTrig "Reports what caused the Low Voltage (LV) battery support required trigger when the vehicle wakes to charge.";
CM_ SG_ 609 VCFRONT_goodForPCSPowerCycleLeak "Front body controller: good for PCS power cycle leaky bkt DBG";
CM_ SG_ 609 VCFRONT_LVBusControlsFutile "Indicates that a required condition is not met for the Low Voltage (LV) bus controllers to operate properly.";
CM_ SG_ 609 VCFRONT_resistanceEstimatio_0001 "Front body controller: resistance estimation test valid";
CM_ SG_ 609 VCFRONT_resistanceEstimatio_0002 "Front body controller: resistance estimation tests expended";
CM_ SG_ 609 VCFRONT_goodLVChargeForUpdate "Indicates that the Low Voltage (LV) battery charge is sufficient to permit an Over-The-Air (OTA) update.";
CM_ SG_ 609 VCFRONT_opportunisticDCRTestNeed "Front body controller: opportunistic DCR test needed";
CM_ SG_ 609 VCFRONT_voltageProfile "Indicates which voltage profile is used to support the 12V battery";
CM_ SG_ 609 VCFRONT_IBSAmpHours "Measures the energy state of the Low Voltage (LV) battery in amp hours.";
CM_ SG_ 609 VCFRONT_IBSVoltageRawDBG "Front body controller: IBS voltage raw DBG; raw 16383 = signal not available (SNA)";
CM_ SG_ 609 VCFRONT_LVBatteryLINCommsDetecte "Front body controller: LV battery LIN comms detected DBG";
CM_ SG_ 609 VCFRONT_voltageSensorMismatchLea "Front body controller: voltage sensor mismatch leaky bkt pct DBG";
CM_ SG_ 609 VCFRONT_LVBatteryFctryLimOverrid "Front body controller: LV battery fctry lim override ok";
CM_ SG_ 609 VCFRONT_LVBatterySPICommsDetecte "Front body controller: LV battery SPI comms detected DBG";
CM_ SG_ 609 VCFRONT_targetCurrent "Reports the target current set by the Low Voltage Battery Management System (LVBMS).";
CM_ SG_ 609 VCFRONT_PCSMia "Indicates that the Power Conversion System (PCS) is not communicating on CAN.";
CM_ SG_ 609 VCFRONT_chargeNeeded "Indicates that the Low Voltage (LV) battery needs to be charged.";
CM_ SG_ 609 VCFRONT_voltageControlLoopIntegr "Front body controller: voltage control loop integration val";
CM_ SG_ 609 VCFRONT_currentControlLoopIntegr "Front body controller: current control loop integration val";
CM_ BO_ 2017 "Front body controller message: LV health";
CM_ SG_ 2017 VCFRONT_LVHealthStatus "Health status of the LV system";
CM_ SG_ 2017 VCFRONT_LVStatusForDrive "Front body controller: LV status for drive";
CM_ SG_ 2017 VCFRONT_LVPowerSecondsToSafeHarb "Reports the amount of time (in seconds) the Low Voltage (LV) power system indicates the vehicle has to achieve safe harbor.";
CM_ SG_ 2017 VCFRONT_LVHealthCounter "Front body controller: LV health counter";
CM_ SG_ 2017 VCFRONT_LVHealthChecksum "Front body controller: LV health checksum";
BA_DEF_ BO_ "GenMsgCycleTime" INT 0 3600000;
BA_DEF_ BO_ "GenMsgSendType" ENUM "Cyclic","NotUsed","NotUsed","NotUsed","NotUsed","NotUsed","NotUsed","IfActive","NoMsgSendType","NotUsed";
BA_DEF_ BO_ "VFrameFormat" ENUM "StandardCAN","ExtendedCAN","reserved","J1939PG","reserved","reserved","reserved","reserved","reserved","reserved","reserved","reserved","reserved","reserved","StandardCAN_FD","ExtendedCAN_FD";
BA_DEF_ BO_ "CANFD_BRS" ENUM "0","1";
BA_DEF_ SG_ "GenSigSNA" STRING;
BA_DEF_ SG_ "SystemSignalLongSymbol" STRING;
BA_DEF_ SG_ "Confidence" ENUM "validated","plausible","layout-only","contradicted";
BA_DEF_DEF_ "GenMsgCycleTime" 0;
BA_DEF_DEF_ "GenMsgSendType" "NoMsgSendType";
BA_DEF_DEF_ "VFrameFormat" "StandardCAN";
BA_DEF_DEF_ "CANFD_BRS" "1";
BA_DEF_DEF_ "GenSigSNA" "";
BA_DEF_DEF_ "SystemSignalLongSymbol" "";
BA_DEF_DEF_ "Confidence" "layout-only";
BA_ "GenMsgCycleTime" BO_ 609 16;
BA_ "GenMsgSendType" BO_ 609 0;
BA_ "GenMsgCycleTime" BO_ 2017 100;
BA_ "GenMsgSendType" BO_ 2017 0;
BA_ "Confidence" SG_ 1520 USM_alertID 1;
BA_ "Confidence" SG_ 1520 USM_alertState 1;
BA_ "Confidence" SG_ 1520 USM_a059_voltageDrop 1;
BA_ "Confidence" SG_ 1520 USM_a059_resistanceEstimate 1;
BA_ "Confidence" SG_ 1520 USM_a059_current 1;
BA_ "Confidence" SG_ 1520 USM_a063_ADCVoltage 1;
BA_ "SystemSignalLongSymbol" SG_ 1520 USM_a101_LIPC_externalWatchdogHe "USM_a101_LIPC_externalWatchdogHeartBeat";
BA_ "SystemSignalLongSymbol" SG_ 1520 USM_a115_UI_corianderVehicleCont "USM_a115_UI_corianderVehicleControl";
BA_ "SystemSignalLongSymbol" SG_ 1520 USM_a117_VEH_intrusionSensorStat "USM_a117_VEH_intrusionSensorStatus";
BA_ "SystemSignalLongSymbol" SG_ 1520 USM_a118_PARTY_AP_vehicleState1H "USM_a118_PARTY_AP_vehicleState1HzMuxed";
BA_ "SystemSignalLongSymbol" SG_ 1520 USM_a118_BDY_AP_vehicleState1HzM "USM_a118_BDY_AP_vehicleState1HzMuxed";
BA_ "SystemSignalLongSymbol" SG_ 1520 USM_a120_PARTY_aggregatedAxleSpe "USM_a120_PARTY_aggregatedAxleSpeed";
BA_ "SystemSignalLongSymbol" SG_ 1520 USM_a120_PARTY_stalklessInterfac "USM_a120_PARTY_stalklessInterfaces";
BA_ "Confidence" SG_ 1520 USM_a131_timeSinceInit 1;
BA_ "Confidence" SG_ 1520 USM_a131_timeSincePwrStateTransi 1;
BA_ "SystemSignalLongSymbol" SG_ 1520 USM_a131_timeSincePwrStateTransi "USM_a131_timeSincePwrStateTransition";
BA_ "Confidence" SG_ 1520 USM_a132_timeSinceInit 1;
BA_ "Confidence" SG_ 1520 USM_a132_timeSincePwrStateTransi 1;
BA_ "SystemSignalLongSymbol" SG_ 1520 USM_a132_timeSincePwrStateTransi "USM_a132_timeSincePwrStateTransition";
BA_ "Confidence" SG_ 1520 USM_a133_timeSinceInit 1;
BA_ "Confidence" SG_ 1520 USM_a133_timeSincePwrStateTransi 1;
BA_ "SystemSignalLongSymbol" SG_ 1520 USM_a133_timeSincePwrStateTransi "USM_a133_timeSincePwrStateTransition";
BA_ "Confidence" SG_ 1520 USM_a134_timeSinceInit 1;
BA_ "Confidence" SG_ 1520 USM_a134_timeSincePwrStateTransi 1;
BA_ "SystemSignalLongSymbol" SG_ 1520 USM_a134_timeSincePwrStateTransi "USM_a134_timeSincePwrStateTransition";
BA_ "Confidence" SG_ 1520 USM_a135_timeSinceInit 1;
BA_ "Confidence" SG_ 1520 USM_a135_timeSincePwrStateTransi 1;
BA_ "SystemSignalLongSymbol" SG_ 1520 USM_a135_timeSincePwrStateTransi "USM_a135_timeSincePwrStateTransition";
BA_ "Confidence" SG_ 1520 USM_a136_timeSinceInit 1;
BA_ "Confidence" SG_ 1520 USM_a136_timeSincePwrStateTransi 1;
BA_ "SystemSignalLongSymbol" SG_ 1520 USM_a136_timeSincePwrStateTransi "USM_a136_timeSincePwrStateTransition";
BA_ "Confidence" SG_ 1520 USM_a137_timeSinceInit 1;
BA_ "Confidence" SG_ 1520 USM_a137_timeSincePwrStateTransi 1;
BA_ "SystemSignalLongSymbol" SG_ 1520 USM_a137_timeSincePwrStateTransi "USM_a137_timeSincePwrStateTransition";
BA_ "Confidence" SG_ 1520 USM_a138_timeSinceInit 1;
BA_ "Confidence" SG_ 1520 USM_a138_timeSincePwrStateTransi 1;
BA_ "SystemSignalLongSymbol" SG_ 1520 USM_a138_timeSincePwrStateTransi "USM_a138_timeSincePwrStateTransition";
BA_ "Confidence" SG_ 1520 USM_a139_timeSinceInit 1;
BA_ "Confidence" SG_ 1520 USM_a139_timeSincePwrStateTransi 1;
BA_ "SystemSignalLongSymbol" SG_ 1520 USM_a139_timeSincePwrStateTransi "USM_a139_timeSincePwrStateTransition";
BA_ "Confidence" SG_ 1520 USM_a140_timeSinceInit 1;
BA_ "Confidence" SG_ 1520 USM_a140_timeSincePwrStateTransi 1;
BA_ "SystemSignalLongSymbol" SG_ 1520 USM_a140_timeSincePwrStateTransi "USM_a140_timeSincePwrStateTransition";
BA_ "Confidence" SG_ 1520 USM_a141_timeSinceInit 1;
BA_ "Confidence" SG_ 1520 USM_a141_timeSincePwrStateTransi 1;
BA_ "SystemSignalLongSymbol" SG_ 1520 USM_a141_timeSincePwrStateTransi "USM_a141_timeSincePwrStateTransition";
BA_ "Confidence" SG_ 1520 USM_a142_timeSinceInit 1;
BA_ "Confidence" SG_ 1520 USM_a142_timeSincePwrStateTransi 1;
BA_ "SystemSignalLongSymbol" SG_ 1520 USM_a142_timeSincePwrStateTransi "USM_a142_timeSincePwrStateTransition";
BA_ "Confidence" SG_ 1520 USM_a143_timeSinceInit 1;
BA_ "Confidence" SG_ 1520 USM_a143_timeSincePwrStateTransi 1;
BA_ "SystemSignalLongSymbol" SG_ 1520 USM_a143_timeSincePwrStateTransi "USM_a143_timeSincePwrStateTransition";
BA_ "Confidence" SG_ 1520 USM_a144_timeSinceInit 1;
BA_ "Confidence" SG_ 1520 USM_a144_timeSincePwrStateTransi 1;
BA_ "SystemSignalLongSymbol" SG_ 1520 USM_a144_timeSincePwrStateTransi "USM_a144_timeSincePwrStateTransition";
BA_ "Confidence" SG_ 1520 USM_a145_timeSinceInit 1;
BA_ "Confidence" SG_ 1520 USM_a145_timeSincePwrStateTransi 1;
BA_ "SystemSignalLongSymbol" SG_ 1520 USM_a145_timeSincePwrStateTransi "USM_a145_timeSincePwrStateTransition";
BA_ "Confidence" SG_ 1520 USM_a146_timeSinceInit 1;
BA_ "Confidence" SG_ 1520 USM_a146_timeSincePwrStateTransi 1;
BA_ "SystemSignalLongSymbol" SG_ 1520 USM_a146_timeSincePwrStateTransi "USM_a146_timeSincePwrStateTransition";
BA_ "Confidence" SG_ 1520 USM_a147_timeSinceInit 1;
BA_ "Confidence" SG_ 1520 USM_a147_timeSincePwrStateTransi 1;
BA_ "SystemSignalLongSymbol" SG_ 1520 USM_a147_timeSincePwrStateTransi "USM_a147_timeSincePwrStateTransition";
BA_ "Confidence" SG_ 1520 USM_a148_timeSinceInit 1;
BA_ "Confidence" SG_ 1520 USM_a148_timeSincePwrStateTransi 1;
BA_ "SystemSignalLongSymbol" SG_ 1520 USM_a148_timeSincePwrStateTransi "USM_a148_timeSincePwrStateTransition";
BA_ "Confidence" SG_ 1520 USM_a149_timeSinceInit 1;
BA_ "Confidence" SG_ 1520 USM_a149_timeSincePwrStateTransi 1;
BA_ "SystemSignalLongSymbol" SG_ 1520 USM_a149_timeSincePwrStateTransi "USM_a149_timeSincePwrStateTransition";
BA_ "Confidence" SG_ 1520 USM_a150_timeSinceInit 1;
BA_ "Confidence" SG_ 1520 USM_a150_timeSincePwrStateTransi 1;
BA_ "SystemSignalLongSymbol" SG_ 1520 USM_a150_timeSincePwrStateTransi "USM_a150_timeSincePwrStateTransition";
BA_ "Confidence" SG_ 1520 USM_a151_timeSinceInit 1;
BA_ "Confidence" SG_ 1520 USM_a151_timeSincePwrStateTransi 1;
BA_ "SystemSignalLongSymbol" SG_ 1520 USM_a151_timeSincePwrStateTransi "USM_a151_timeSincePwrStateTransition";
BA_ "Confidence" SG_ 1520 USM_a152_timeSinceInit 1;
BA_ "Confidence" SG_ 1520 USM_a152_timeSincePwrStateTransi 1;
BA_ "SystemSignalLongSymbol" SG_ 1520 USM_a152_timeSincePwrStateTransi "USM_a152_timeSincePwrStateTransition";
BA_ "Confidence" SG_ 1520 USM_a153_timeSinceInit 1;
BA_ "Confidence" SG_ 1520 USM_a153_timeSincePwrStateTransi 1;
BA_ "SystemSignalLongSymbol" SG_ 1520 USM_a153_timeSincePwrStateTransi "USM_a153_timeSincePwrStateTransition";
BA_ "Confidence" SG_ 1520 USM_a154_timeSinceInit 1;
BA_ "Confidence" SG_ 1520 USM_a154_timeSincePwrStateTransi 1;
BA_ "SystemSignalLongSymbol" SG_ 1520 USM_a154_timeSincePwrStateTransi "USM_a154_timeSincePwrStateTransition";
BA_ "Confidence" SG_ 1520 USM_a155_temperature 1;
BA_ "Confidence" SG_ 1520 USM_a156_temperature 1;
BA_ "Confidence" SG_ 1520 USM_a157_temperature 1;
BA_ "Confidence" SG_ 1520 USM_a158_temperature 1;
BA_ "Confidence" SG_ 1520 USM_a159_temperature 1;
BA_ "Confidence" SG_ 1520 USM_a160_temperature 1;
BA_ "Confidence" SG_ 1520 USM_a161_temperature 1;
BA_ "Confidence" SG_ 1520 USM_a162_temperature 1;
BA_ "Confidence" SG_ 1520 USM_a163_temperature 1;
BA_ "Confidence" SG_ 1520 USM_a164_temperature 1;
BA_ "Confidence" SG_ 1520 USM_a165_temperature 1;
BA_ "Confidence" SG_ 1520 USM_a166_temperature 1;
BA_ "Confidence" SG_ 1520 USM_a177_rtmCompensated 1;
BA_ "Confidence" SG_ 1520 USM_a177_rtmOffset 1;
BA_ "Confidence" SG_ 1520 USM_a177_ambientTemperature 1;
BA_ "GenSigSNA" SG_ 1520 USM_a177_ambientTemperature "0";
BA_ "Confidence" SG_ 1520 USM_a177_sensorTemperature 1;
BA_ "Confidence" SG_ 1520 USM_a178_rtmCompensated 1;
BA_ "Confidence" SG_ 1520 USM_a178_rtmOffset 1;
BA_ "Confidence" SG_ 1520 USM_a178_ambientTemperature 1;
BA_ "GenSigSNA" SG_ 1520 USM_a178_ambientTemperature "0";
BA_ "Confidence" SG_ 1520 USM_a178_sensorTemperature 1;
BA_ "Confidence" SG_ 1520 USM_a179_rtmCompensated 1;
BA_ "Confidence" SG_ 1520 USM_a179_rtmOffset 1;
BA_ "Confidence" SG_ 1520 USM_a179_ambientTemperature 1;
BA_ "GenSigSNA" SG_ 1520 USM_a179_ambientTemperature "0";
BA_ "Confidence" SG_ 1520 USM_a179_sensorTemperature 1;
BA_ "Confidence" SG_ 1520 USM_a180_rtmCompensated 1;
BA_ "Confidence" SG_ 1520 USM_a180_rtmOffset 1;
BA_ "Confidence" SG_ 1520 USM_a180_ambientTemperature 1;
BA_ "GenSigSNA" SG_ 1520 USM_a180_ambientTemperature "0";
BA_ "Confidence" SG_ 1520 USM_a180_sensorTemperature 1;
BA_ "Confidence" SG_ 1520 USM_a181_rtmCompensated 1;
BA_ "Confidence" SG_ 1520 USM_a181_rtmOffset 1;
BA_ "Confidence" SG_ 1520 USM_a181_ambientTemperature 1;
BA_ "GenSigSNA" SG_ 1520 USM_a181_ambientTemperature "0";
BA_ "Confidence" SG_ 1520 USM_a181_sensorTemperature 1;
BA_ "Confidence" SG_ 1520 USM_a182_rtmCompensated 1;
BA_ "Confidence" SG_ 1520 USM_a182_rtmOffset 1;
BA_ "Confidence" SG_ 1520 USM_a182_ambientTemperature 1;
BA_ "GenSigSNA" SG_ 1520 USM_a182_ambientTemperature "0";
BA_ "Confidence" SG_ 1520 USM_a182_sensorTemperature 1;
BA_ "Confidence" SG_ 1520 USM_a183_rtmCompensated 1;
BA_ "Confidence" SG_ 1520 USM_a183_rtmOffset 1;
BA_ "Confidence" SG_ 1520 USM_a183_ambientTemperature 1;
BA_ "GenSigSNA" SG_ 1520 USM_a183_ambientTemperature "0";
BA_ "Confidence" SG_ 1520 USM_a183_sensorTemperature 1;
BA_ "Confidence" SG_ 1520 USM_a184_rtmCompensated 1;
BA_ "Confidence" SG_ 1520 USM_a184_rtmOffset 1;
BA_ "Confidence" SG_ 1520 USM_a184_ambientTemperature 1;
BA_ "GenSigSNA" SG_ 1520 USM_a184_ambientTemperature "0";
BA_ "Confidence" SG_ 1520 USM_a184_sensorTemperature 1;
BA_ "Confidence" SG_ 1520 USM_a185_rtmCompensated 1;
BA_ "Confidence" SG_ 1520 USM_a185_rtmOffset 1;
BA_ "Confidence" SG_ 1520 USM_a185_ambientTemperature 1;
BA_ "GenSigSNA" SG_ 1520 USM_a185_ambientTemperature "0";
BA_ "Confidence" SG_ 1520 USM_a185_sensorTemperature 1;
BA_ "Confidence" SG_ 1520 USM_a186_rtmCompensated 1;
BA_ "Confidence" SG_ 1520 USM_a186_rtmOffset 1;
BA_ "Confidence" SG_ 1520 USM_a186_ambientTemperature 1;
BA_ "GenSigSNA" SG_ 1520 USM_a186_ambientTemperature "0";
BA_ "Confidence" SG_ 1520 USM_a186_sensorTemperature 1;
BA_ "Confidence" SG_ 1520 USM_a187_rtmCompensated 1;
BA_ "Confidence" SG_ 1520 USM_a187_rtmOffset 1;
BA_ "Confidence" SG_ 1520 USM_a187_ambientTemperature 1;
BA_ "GenSigSNA" SG_ 1520 USM_a187_ambientTemperature "0";
BA_ "Confidence" SG_ 1520 USM_a187_sensorTemperature 1;
BA_ "Confidence" SG_ 1520 USM_a188_rtmCompensated 1;
BA_ "Confidence" SG_ 1520 USM_a188_rtmOffset 1;
BA_ "Confidence" SG_ 1520 USM_a188_ambientTemperature 1;
BA_ "GenSigSNA" SG_ 1520 USM_a188_ambientTemperature "0";
BA_ "Confidence" SG_ 1520 USM_a188_sensorTemperature 1;
BA_ "SystemSignalLongSymbol" SG_ 1520 USM_a227_underVoltAtVtankDuringB "USM_a227_underVoltAtVtankDuringBurst";
BA_ "SystemSignalLongSymbol" SG_ 1520 USM_a227_overVoltAtVtankDuringBu "USM_a227_overVoltAtVtankDuringBurst";
BA_ "SystemSignalLongSymbol" SG_ 1520 USM_a227_verificationOfConfigAnd "USM_a227_verificationOfConfigAndCalcParamsFail";
BA_ "SystemSignalLongSymbol" SG_ 1520 USM_a227_receiverReachedErrorSta "USM_a227_receiverReachedErrorState";
BA_ "SystemSignalLongSymbol" SG_ 1520 USM_a227_timeIntBetween2PulsesEr "USM_a227_timeIntBetween2PulsesErr";
BA_ "SystemSignalLongSymbol" SG_ 1520 USM_a227_numInvalidStartEdgeSinc "USM_a227_numInvalidStartEdgeSinceInit";
BA_ "SystemSignalLongSymbol" SG_ 1520 USM_a227_numAtgNoiseErrorsSinceI "USM_a227_numAtgNoiseErrorsSinceInit";
BA_ "SystemSignalLongSymbol" SG_ 1520 USM_a228_underVoltAtVtankDuringB "USM_a228_underVoltAtVtankDuringBurst";
BA_ "SystemSignalLongSymbol" SG_ 1520 USM_a228_overVoltAtVtankDuringBu "USM_a228_overVoltAtVtankDuringBurst";
BA_ "SystemSignalLongSymbol" SG_ 1520 USM_a228_verificationOfConfigAnd "USM_a228_verificationOfConfigAndCalcParamsFail";
BA_ "SystemSignalLongSymbol" SG_ 1520 USM_a228_receiverReachedErrorSta "USM_a228_receiverReachedErrorState";
BA_ "SystemSignalLongSymbol" SG_ 1520 USM_a228_timeIntBetween2PulsesEr "USM_a228_timeIntBetween2PulsesErr";
BA_ "SystemSignalLongSymbol" SG_ 1520 USM_a228_numInvalidStartEdgeSinc "USM_a228_numInvalidStartEdgeSinceInit";
BA_ "SystemSignalLongSymbol" SG_ 1520 USM_a228_numAtgNoiseErrorsSinceI "USM_a228_numAtgNoiseErrorsSinceInit";
BA_ "SystemSignalLongSymbol" SG_ 1520 USM_a229_underVoltAtVtankDuringB "USM_a229_underVoltAtVtankDuringBurst";
BA_ "SystemSignalLongSymbol" SG_ 1520 USM_a229_overVoltAtVtankDuringBu "USM_a229_overVoltAtVtankDuringBurst";
BA_ "SystemSignalLongSymbol" SG_ 1520 USM_a229_verificationOfConfigAnd "USM_a229_verificationOfConfigAndCalcParamsFail";
BA_ "SystemSignalLongSymbol" SG_ 1520 USM_a229_receiverReachedErrorSta "USM_a229_receiverReachedErrorState";
BA_ "SystemSignalLongSymbol" SG_ 1520 USM_a229_timeIntBetween2PulsesEr "USM_a229_timeIntBetween2PulsesErr";
BA_ "SystemSignalLongSymbol" SG_ 1520 USM_a229_numInvalidStartEdgeSinc "USM_a229_numInvalidStartEdgeSinceInit";
BA_ "SystemSignalLongSymbol" SG_ 1520 USM_a229_numAtgNoiseErrorsSinceI "USM_a229_numAtgNoiseErrorsSinceInit";
BA_ "SystemSignalLongSymbol" SG_ 1520 USM_a230_underVoltAtVtankDuringB "USM_a230_underVoltAtVtankDuringBurst";
BA_ "SystemSignalLongSymbol" SG_ 1520 USM_a230_overVoltAtVtankDuringBu "USM_a230_overVoltAtVtankDuringBurst";
BA_ "SystemSignalLongSymbol" SG_ 1520 USM_a230_verificationOfConfigAnd "USM_a230_verificationOfConfigAndCalcParamsFail";
BA_ "SystemSignalLongSymbol" SG_ 1520 USM_a230_receiverReachedErrorSta "USM_a230_receiverReachedErrorState";
BA_ "SystemSignalLongSymbol" SG_ 1520 USM_a230_timeIntBetween2PulsesEr "USM_a230_timeIntBetween2PulsesErr";
BA_ "SystemSignalLongSymbol" SG_ 1520 USM_a230_numInvalidStartEdgeSinc "USM_a230_numInvalidStartEdgeSinceInit";
BA_ "SystemSignalLongSymbol" SG_ 1520 USM_a230_numAtgNoiseErrorsSinceI "USM_a230_numAtgNoiseErrorsSinceInit";
BA_ "SystemSignalLongSymbol" SG_ 1520 USM_a231_underVoltAtVtankDuringB "USM_a231_underVoltAtVtankDuringBurst";
BA_ "SystemSignalLongSymbol" SG_ 1520 USM_a231_overVoltAtVtankDuringBu "USM_a231_overVoltAtVtankDuringBurst";
BA_ "SystemSignalLongSymbol" SG_ 1520 USM_a231_verificationOfConfigAnd "USM_a231_verificationOfConfigAndCalcParamsFail";
BA_ "SystemSignalLongSymbol" SG_ 1520 USM_a231_receiverReachedErrorSta "USM_a231_receiverReachedErrorState";
BA_ "SystemSignalLongSymbol" SG_ 1520 USM_a231_timeIntBetween2PulsesEr "USM_a231_timeIntBetween2PulsesErr";
BA_ "SystemSignalLongSymbol" SG_ 1520 USM_a231_numInvalidStartEdgeSinc "USM_a231_numInvalidStartEdgeSinceInit";
BA_ "SystemSignalLongSymbol" SG_ 1520 USM_a231_numAtgNoiseErrorsSinceI "USM_a231_numAtgNoiseErrorsSinceInit";
BA_ "SystemSignalLongSymbol" SG_ 1520 USM_a232_underVoltAtVtankDuringB "USM_a232_underVoltAtVtankDuringBurst";
BA_ "SystemSignalLongSymbol" SG_ 1520 USM_a232_overVoltAtVtankDuringBu "USM_a232_overVoltAtVtankDuringBurst";
BA_ "SystemSignalLongSymbol" SG_ 1520 USM_a232_verificationOfConfigAnd "USM_a232_verificationOfConfigAndCalcParamsFail";
BA_ "SystemSignalLongSymbol" SG_ 1520 USM_a232_receiverReachedErrorSta "USM_a232_receiverReachedErrorState";
BA_ "SystemSignalLongSymbol" SG_ 1520 USM_a232_timeIntBetween2PulsesEr "USM_a232_timeIntBetween2PulsesErr";
BA_ "SystemSignalLongSymbol" SG_ 1520 USM_a232_numInvalidStartEdgeSinc "USM_a232_numInvalidStartEdgeSinceInit";
BA_ "SystemSignalLongSymbol" SG_ 1520 USM_a232_numAtgNoiseErrorsSinceI "USM_a232_numAtgNoiseErrorsSinceInit";
BA_ "SystemSignalLongSymbol" SG_ 1520 USM_a233_underVoltAtVtankDuringB "USM_a233_underVoltAtVtankDuringBurst";
BA_ "SystemSignalLongSymbol" SG_ 1520 USM_a233_overVoltAtVtankDuringBu "USM_a233_overVoltAtVtankDuringBurst";
BA_ "SystemSignalLongSymbol" SG_ 1520 USM_a233_verificationOfConfigAnd "USM_a233_verificationOfConfigAndCalcParamsFail";
BA_ "SystemSignalLongSymbol" SG_ 1520 USM_a233_receiverReachedErrorSta "USM_a233_receiverReachedErrorState";
BA_ "SystemSignalLongSymbol" SG_ 1520 USM_a233_timeIntBetween2PulsesEr "USM_a233_timeIntBetween2PulsesErr";
BA_ "SystemSignalLongSymbol" SG_ 1520 USM_a233_numInvalidStartEdgeSinc "USM_a233_numInvalidStartEdgeSinceInit";
BA_ "SystemSignalLongSymbol" SG_ 1520 USM_a233_numAtgNoiseErrorsSinceI "USM_a233_numAtgNoiseErrorsSinceInit";
BA_ "SystemSignalLongSymbol" SG_ 1520 USM_a234_underVoltAtVtankDuringB "USM_a234_underVoltAtVtankDuringBurst";
BA_ "SystemSignalLongSymbol" SG_ 1520 USM_a234_overVoltAtVtankDuringBu "USM_a234_overVoltAtVtankDuringBurst";
BA_ "SystemSignalLongSymbol" SG_ 1520 USM_a234_verificationOfConfigAnd "USM_a234_verificationOfConfigAndCalcParamsFail";
BA_ "SystemSignalLongSymbol" SG_ 1520 USM_a234_receiverReachedErrorSta "USM_a234_receiverReachedErrorState";
BA_ "SystemSignalLongSymbol" SG_ 1520 USM_a234_timeIntBetween2PulsesEr "USM_a234_timeIntBetween2PulsesErr";
BA_ "SystemSignalLongSymbol" SG_ 1520 USM_a234_numInvalidStartEdgeSinc "USM_a234_numInvalidStartEdgeSinceInit";
BA_ "SystemSignalLongSymbol" SG_ 1520 USM_a234_numAtgNoiseErrorsSinceI "USM_a234_numAtgNoiseErrorsSinceInit";
BA_ "SystemSignalLongSymbol" SG_ 1520 USM_a235_underVoltAtVtankDuringB "USM_a235_underVoltAtVtankDuringBurst";
BA_ "SystemSignalLongSymbol" SG_ 1520 USM_a235_overVoltAtVtankDuringBu "USM_a235_overVoltAtVtankDuringBurst";
BA_ "SystemSignalLongSymbol" SG_ 1520 USM_a235_verificationOfConfigAnd "USM_a235_verificationOfConfigAndCalcParamsFail";
BA_ "SystemSignalLongSymbol" SG_ 1520 USM_a235_receiverReachedErrorSta "USM_a235_receiverReachedErrorState";
BA_ "SystemSignalLongSymbol" SG_ 1520 USM_a235_timeIntBetween2PulsesEr "USM_a235_timeIntBetween2PulsesErr";
BA_ "SystemSignalLongSymbol" SG_ 1520 USM_a235_numInvalidStartEdgeSinc "USM_a235_numInvalidStartEdgeSinceInit";
BA_ "SystemSignalLongSymbol" SG_ 1520 USM_a235_numAtgNoiseErrorsSinceI "USM_a235_numAtgNoiseErrorsSinceInit";
BA_ "SystemSignalLongSymbol" SG_ 1520 USM_a236_underVoltAtVtankDuringB "USM_a236_underVoltAtVtankDuringBurst";
BA_ "SystemSignalLongSymbol" SG_ 1520 USM_a236_overVoltAtVtankDuringBu "USM_a236_overVoltAtVtankDuringBurst";
BA_ "SystemSignalLongSymbol" SG_ 1520 USM_a236_verificationOfConfigAnd "USM_a236_verificationOfConfigAndCalcParamsFail";
BA_ "SystemSignalLongSymbol" SG_ 1520 USM_a236_receiverReachedErrorSta "USM_a236_receiverReachedErrorState";
BA_ "SystemSignalLongSymbol" SG_ 1520 USM_a236_timeIntBetween2PulsesEr "USM_a236_timeIntBetween2PulsesErr";
BA_ "SystemSignalLongSymbol" SG_ 1520 USM_a236_numInvalidStartEdgeSinc "USM_a236_numInvalidStartEdgeSinceInit";
BA_ "SystemSignalLongSymbol" SG_ 1520 USM_a236_numAtgNoiseErrorsSinceI "USM_a236_numAtgNoiseErrorsSinceInit";
BA_ "SystemSignalLongSymbol" SG_ 1520 USM_a237_underVoltAtVtankDuringB "USM_a237_underVoltAtVtankDuringBurst";
BA_ "SystemSignalLongSymbol" SG_ 1520 USM_a237_overVoltAtVtankDuringBu "USM_a237_overVoltAtVtankDuringBurst";
BA_ "SystemSignalLongSymbol" SG_ 1520 USM_a237_verificationOfConfigAnd "USM_a237_verificationOfConfigAndCalcParamsFail";
BA_ "SystemSignalLongSymbol" SG_ 1520 USM_a237_receiverReachedErrorSta "USM_a237_receiverReachedErrorState";
BA_ "SystemSignalLongSymbol" SG_ 1520 USM_a237_timeIntBetween2PulsesEr "USM_a237_timeIntBetween2PulsesErr";
BA_ "SystemSignalLongSymbol" SG_ 1520 USM_a237_numInvalidStartEdgeSinc "USM_a237_numInvalidStartEdgeSinceInit";
BA_ "SystemSignalLongSymbol" SG_ 1520 USM_a237_numAtgNoiseErrorsSinceI "USM_a237_numAtgNoiseErrorsSinceInit";
BA_ "SystemSignalLongSymbol" SG_ 1520 USM_a238_underVoltAtVtankDuringB "USM_a238_underVoltAtVtankDuringBurst";
BA_ "SystemSignalLongSymbol" SG_ 1520 USM_a238_overVoltAtVtankDuringBu "USM_a238_overVoltAtVtankDuringBurst";
BA_ "SystemSignalLongSymbol" SG_ 1520 USM_a238_verificationOfConfigAnd "USM_a238_verificationOfConfigAndCalcParamsFail";
BA_ "SystemSignalLongSymbol" SG_ 1520 USM_a238_receiverReachedErrorSta "USM_a238_receiverReachedErrorState";
BA_ "SystemSignalLongSymbol" SG_ 1520 USM_a238_timeIntBetween2PulsesEr "USM_a238_timeIntBetween2PulsesErr";
BA_ "SystemSignalLongSymbol" SG_ 1520 USM_a238_numInvalidStartEdgeSinc "USM_a238_numInvalidStartEdgeSinceInit";
BA_ "SystemSignalLongSymbol" SG_ 1520 USM_a238_numAtgNoiseErrorsSinceI "USM_a238_numAtgNoiseErrorsSinceInit";
BA_ "Confidence" SG_ 609 VCFRONT_12VBatteryStatusIndex 1;
BA_ "Confidence" SG_ 609 VCFRONT_good12VforUpdate 1;
BA_ "Confidence" SG_ 609 VCFRONT_LVLoadRequest 1;
BA_ "Confidence" SG_ 609 VCFRONT_12VBatteryStatusCounter 1;
BA_ "Confidence" SG_ 609 VCFRONT_12VBatteryStatusChecksum 0;
BA_ "Confidence" SG_ 609 VCFRONT_batterySupportRequest 1;
BA_ "Confidence" SG_ 609 VCFRONT_batterySMState 1;
BA_ "Confidence" SG_ 609 VCFRONT_eFuseRecoveryStateDBG 1;
BA_ "Confidence" SG_ 609 VCFRONT_batteryLINScheduleDBG 1;
BA_ "GenSigSNA" SG_ 609 VCFRONT_batteryLINScheduleDBG "7";
BA_ "Confidence" SG_ 609 VCFRONT_resistanceEstimationTest 1;
BA_ "SystemSignalLongSymbol" SG_ 609 VCFRONT_resistanceEstimationTest "VCFRONT_resistanceEstimationTestCounter";
BA_ "Confidence" SG_ 609 VCFRONT_IBSCurrent 1;
BA_ "Confidence" SG_ 609 VCFRONT_IBSVoltage 0;
BA_ "GenSigSNA" SG_ 609 VCFRONT_IBSVoltage "4095";
BA_ "Confidence" SG_ 609 VCFRONT_reverseBatteryFault 1;
BA_ "Confidence" SG_ 609 VCFRONT_LVBatterySupported 1;
BA_ "Confidence" SG_ 609 VCFRONT_LVBatteryCannotSupportVe 1;
BA_ "SystemSignalLongSymbol" SG_ 609 VCFRONT_LVBatteryCannotSupportVe "VCFRONT_LVBatteryCannotSupportVehicle";
BA_ "Confidence" SG_ 609 VCFRONT_goodTemp12VforUpdate 1;
BA_ "Confidence" SG_ 609 VCFRONT_12VBatteryTargetVoltage 1;
BA_ "Confidence" SG_ 609 VCFRONT_IBSTemperature 1;
BA_ "GenSigSNA" SG_ 609 VCFRONT_IBSTemperature "2047";
BA_ "Confidence" SG_ 609 VCFRONT_currentSensorMismatchLea 1;
BA_ "SystemSignalLongSymbol" SG_ 609 VCFRONT_currentSensorMismatchLea "VCFRONT_currentSensorMismatchLeakyBktPctDBG";
BA_ "Confidence" SG_ 609 VCFRONT_LVBatteryEnergyRemaining 1;
BA_ "SystemSignalLongSymbol" SG_ 609 VCFRONT_LVBatteryEnergyRemaining "VCFRONT_LVBatteryEnergyRemainingPCT";
BA_ "Confidence" SG_ 609 VCFRONT_LVBatteryStatusForDrive 1;
BA_ "Confidence" SG_ 609 VCFRONT_LVBatteryType 1;
BA_ "Confidence" SG_ 609 VCFRONT_resistanceEstimationNeed 1;
BA_ "SystemSignalLongSymbol" SG_ 609 VCFRONT_resistanceEstimationNeed "VCFRONT_resistanceEstimationNeeded";
BA_ "Confidence" SG_ 609 VCFRONT_IBSVoltageFiltered 0;
BA_ "GenSigSNA" SG_ 609 VCFRONT_IBSVoltageFiltered "16383";
BA_ "Confidence" SG_ 609 VCFRONT_LVBMS_LVBusVoltageSource 1;
BA_ "SystemSignalLongSymbol" SG_ 609 VCFRONT_LVBMS_LVBusVoltageSource "VCFRONT_LVBMS_LVBusVoltageSourceDBG";
BA_ "Confidence" SG_ 609 VCFRONT_LVBMS_LVPackCurrentSourc 1;
BA_ "SystemSignalLongSymbol" SG_ 609 VCFRONT_LVBMS_LVPackCurrentSourc "VCFRONT_LVBMS_LVPackCurrentSourceDBG";
BA_ "Confidence" SG_ 609 VCFRONT_LVBatterySupportRqrdTrig 1;
BA_ "SystemSignalLongSymbol" SG_ 609 VCFRONT_LVBatterySupportRqrdTrig "VCFRONT_LVBatterySupportRqrdTrigger";
BA_ "Confidence" SG_ 609 VCFRONT_goodForPCSPowerCycleLeak 1;
BA_ "SystemSignalLongSymbol" SG_ 609 VCFRONT_goodForPCSPowerCycleLeak "VCFRONT_goodForPCSPowerCycleLeakyBktDBG";
BA_ "Confidence" SG_ 609 VCFRONT_LVBusControlsFutile 1;
BA_ "Confidence" SG_ 609 VCFRONT_resistanceEstimatio_0001 1;
BA_ "SystemSignalLongSymbol" SG_ 609 VCFRONT_resistanceEstimatio_0001 "VCFRONT_resistanceEstimationTestValid";
BA_ "Confidence" SG_ 609 VCFRONT_resistanceEstimatio_0002 1;
BA_ "SystemSignalLongSymbol" SG_ 609 VCFRONT_resistanceEstimatio_0002 "VCFRONT_resistanceEstimationTestsExpended";
BA_ "Confidence" SG_ 609 VCFRONT_goodLVChargeForUpdate 1;
BA_ "Confidence" SG_ 609 VCFRONT_opportunisticDCRTestNeed 1;
BA_ "SystemSignalLongSymbol" SG_ 609 VCFRONT_opportunisticDCRTestNeed "VCFRONT_opportunisticDCRTestNeeded";
BA_ "Confidence" SG_ 609 VCFRONT_voltageProfile 1;
BA_ "Confidence" SG_ 609 VCFRONT_IBSAmpHours 1;
BA_ "Confidence" SG_ 609 VCFRONT_IBSVoltageRawDBG 0;
BA_ "GenSigSNA" SG_ 609 VCFRONT_IBSVoltageRawDBG "16383";
BA_ "Confidence" SG_ 609 VCFRONT_LVBatteryLINCommsDetecte 1;
BA_ "SystemSignalLongSymbol" SG_ 609 VCFRONT_LVBatteryLINCommsDetecte "VCFRONT_LVBatteryLINCommsDetectedDBG";
BA_ "Confidence" SG_ 609 VCFRONT_voltageSensorMismatchLea 1;
BA_ "SystemSignalLongSymbol" SG_ 609 VCFRONT_voltageSensorMismatchLea "VCFRONT_voltageSensorMismatchLeakyBktPctDBG";
BA_ "Confidence" SG_ 609 VCFRONT_LVBatteryFctryLimOverrid 1;
BA_ "SystemSignalLongSymbol" SG_ 609 VCFRONT_LVBatteryFctryLimOverrid "VCFRONT_LVBatteryFctryLimOverrideOk";
BA_ "Confidence" SG_ 609 VCFRONT_LVBatterySPICommsDetecte 1;
BA_ "SystemSignalLongSymbol" SG_ 609 VCFRONT_LVBatterySPICommsDetecte "VCFRONT_LVBatterySPICommsDetectedDBG";
BA_ "Confidence" SG_ 609 VCFRONT_targetCurrent 1;
BA_ "Confidence" SG_ 609 VCFRONT_PCSMia 1;
BA_ "Confidence" SG_ 609 VCFRONT_chargeNeeded 1;
BA_ "Confidence" SG_ 609 VCFRONT_voltageControlLoopIntegr 1;
BA_ "SystemSignalLongSymbol" SG_ 609 VCFRONT_voltageControlLoopIntegr "VCFRONT_voltageControlLoopIntegrationVal";
BA_ "Confidence" SG_ 609 VCFRONT_currentControlLoopIntegr 1;
BA_ "SystemSignalLongSymbol" SG_ 609 VCFRONT_currentControlLoopIntegr "VCFRONT_currentControlLoopIntegrationVal";
BA_ "Confidence" SG_ 2017 VCFRONT_LVHealthStatus 1;
BA_ "Confidence" SG_ 2017 VCFRONT_LVStatusForDrive 1;
BA_ "Confidence" SG_ 2017 VCFRONT_LVPowerSecondsToSafeHarb 1;
BA_ "SystemSignalLongSymbol" SG_ 2017 VCFRONT_LVPowerSecondsToSafeHarb "VCFRONT_LVPowerSecondsToSafeHarbor";
VAL_ 1520 USM_alertID 255 "a255_rearSensorsOvercurrent" 254 "a254_frontSensorsOvercurrent" 253 "a253_anyHwErrorSet" 252 "a252_anyComErrorSet" 251 "a251_s12HwComErrDiagnostics" 250 "a250_s11HwComErrDiagnostics" 249 "a249_s10HwComErrDiagnostics" 248 "a248_s9HwComErrDiagnostics" 247 "a247_s8HwComErrDiagnostics" 246 "a246_s7HwComErrDiagnostics" 245 "a245_s6HwComErrDiagnostics" 244 "a244_s5HwComErrDiagnostics" 243 "a243_s4HwComErrDiagnostics" 242 "a242_s3HwComErrDiagnostics" 241 "a241_s2HwComErrDiagnostics" 240 "a240_s1HwComErrDiagnostics" 238 "a238_s12InitError" 237 "a237_s11InitError" 236 "a236_s10InitError" 235 "a235_s9InitError" 234 "a234_s8InitError" 233 "a233_s7InitError" 232 "a232_s6InitError" 231 "a231_s5InitError" 230 "a230_s4InitError" 229 "a229_s3InitError" 228 "a228_s2InitError" 227 "a227_s1InitError" 226 "a226_s12DebugEepromInvalid" 225 "a225_s11DebugEepromInvalid" 224 "a224_s10DebugEepromInvalid" 223 "a223_s9DebugEepromInvalid" 222 "a222_s8DebugEepromInvalid" 221 "a221_s7DebugEepromInvalid" 220 "a220_s6DebugEepromInvalid" 219 "a219_s5DebugEepromInvalid" 218 "a218_s4DebugEepromInvalid" 217 "a217_s3DebugEepromInvalid" 216 "a216_s2DebugEepromInvalid" 215 "a215_s1DebugEepromInvalid" 214 "a214_s12NearFieldDetected" 213 "a213_s11NearFieldDetected" 212 "a212_s10NearFieldDetected" 211 "a211_s9NearFieldDetected" 210 "a210_s8NearFieldDetected" 209 "a209_s7NearFieldDetected" 208 "a208_s6NearFieldDetected" 207 "a207_s5NearFieldDetected" 206 "a206_s4NearFieldDetected" 205 "a205_s3NearFieldDetected" 204 "a204_s2NearFieldDetected" 203 "a203_s1NearFieldDetected" 202 "a202_e52417Fault" 201 "a201_e52142Fault" 200 "a200_s12Disconnected" 199 "a199_s11Disconnected" 198 "a198_s10Disconnected" 197 "a197_s9Disconnected" 196 "a196_s8Disconnected" 195 "a195_s7Disconnected" 194 "a194_s6Disconnected" 193 "a193_s5Disconnected" 192 "a192_s4Disconnected" 191 "a191_s3Disconnected" 190 "a190_s2Disconnected" 189 "a189_s1Disconnected" 188 "a188_s12Blocked" 187 "a187_s11Blocked" 186 "a186_s10Blocked" 185 "a185_s9Blocked" 184 "a184_s8Blocked" 183 "a183_s7Blocked" 182 "a182_s6Blocked" 181 "a181_s5Blocked" 180 "a180_s4Blocked" 179 "a179_s3Blocked" 178 "a178_s2Blocked" 177 "a177_s1Blocked" 166 "a166_s12OverTemp" 165 "a165_s11OverTemp" 164 "a164_s10OverTemp" 163 "a163_s9OverTemp" 162 "a162_s8OverTemp" 161 "a161_s7OverTemp" 160 "a160_s6OverTemp" 159 "a159_s5OverTemp" 158 "a158_s4OverTemp" 157 "a157_s3OverTemp" 156 "a156_s2OverTemp" 155 "a155_s1OverTemp" 154 "a154_s12HwError" 153 "a153_s11HwError" 152 "a152_s10HwError" 151 "a151_s9HwError" 150 "a150_s8HwError" 149 "a149_s7HwError" 148 "a148_s6HwError" 147 "a147_s5HwError" 146 "a146_s4HwError" 145 "a145_s3HwError" 144 "a144_s2HwError" 143 "a143_s1HwError" 142 "a142_s12ComError" 141 "a141_s11ComError" 140 "a140_s10ComError" 139 "a139_s9ComError" 138 "a138_s8ComError" 137 "a137_s7ComError" 136 "a136_s6ComError" 135 "a135_s5ComError" 134 "a134_s4ComError" 133 "a133_s3ComError" 132 "a132_s2ComError" 131 "a131_s1ComError" 120 "a120_DI_DRIVE_MIA" 119 "a119_SCCM_MIA" 118 "a118_VCFRONT_MIA" 117 "a117_VCLEFT_MIA" 116 "a116_VCRIGHT_MIA" 115 "a115_VCSEC_MIA" 114 "a114_ESP_MIA" 113 "a113_UI_MIA" 112 "a112_EPBL_MIA" 111 "a111_EPBR_MIA" 110 "a110_GTW_MIA" 109 "a109_RCM_MIA" 108 "a108_DIF_MIA" 107 "a107_BMS_MIA" 106 "a106_PCS_MIA" 105 "a105_TAS_MIA" 104 "a104_DAS_MIA" 103 "a103_CP_MIA" 102 "a102_PTC_MIA" 101 "a101_PM_MIA" 100 "a100_CANbus_MIA" 99 "a099_PARK_MIA" 98 "a098_DIR_MIA" 97 "a097_CMP_MIA" 96 "a096_OCS1P_MIA" 95 "a095_CHG_MIA" 94 "a094_EPAS3P_MIA" 93 "a093_VCSEATP_MIA" 92 "a092_VCSEATD_MIA" 91 "a091_CMPD_MIA" 90 "a090_APS_MIA" 89 "a089_IBST_MIA" 88 "a088_DIRER_MIA" 87 "a087_DIREL_MIA" 86 "a086_VCBATT_MIA" 85 "a085_CCCM_MIA" 84 "a084_TPMS_MIA" 83 "a083_VCLEFT_IPC_MIA" 82 "a082_VCRIGHT_IPC_MIA" 64 "a064_busSleepReqTimeout" 63 "a063_SwitchFault" 62 "a062_XCPWasConnected" 61 "a061_XCPConnected" 60 "a060_engineeringBuild" 59 "a059_inputResistanceHigh" 58 "a058_inputRHighSyncDebug" 57 "a057_HVP_MIA" 46 "a046_Task1000msError" 45 "a045_Task100msError" 44 "a044_Task10msError" 43 "a043_Task1msError" 42 "a042_HighStackUsage" 41 "a041_HighCPULoad" 31 "a031_UDSActive" 30 "a030_ECULogUploadRequest" 29 "a029_CoreDump" 22 "a022_TaskInitError" 21 "a021_TaskSchedulerError" 16 "a016_NVMMRecordError" 15 "a015_NVMMError" 13 "a013_AlertManagerFault" 12 "a012_CPUReset" 6 "a006_CANTX_cyclicError" 5 "a005_CANTXError" 3 "a003_SWAssertion" 2 "a002_PowerLossReset" 1 "a001_WatchdogReset" 0 "ALERT_DO_NOT_USE_ZERO" ;
VAL_ 1520 USM_alertState 1 "SET" 0 "CLEARED" ;
VAL_ 1520 USM_a177_ambientTemperature 0 "SNA" ;
VAL_ 1520 USM_a178_ambientTemperature 0 "SNA" ;
VAL_ 1520 USM_a179_ambientTemperature 0 "SNA" ;
VAL_ 1520 USM_a180_ambientTemperature 0 "SNA" ;
VAL_ 1520 USM_a181_ambientTemperature 0 "SNA" ;
VAL_ 1520 USM_a182_ambientTemperature 0 "SNA" ;
VAL_ 1520 USM_a183_ambientTemperature 0 "SNA" ;
VAL_ 1520 USM_a184_ambientTemperature 0 "SNA" ;
VAL_ 1520 USM_a185_ambientTemperature 0 "SNA" ;
VAL_ 1520 USM_a186_ambientTemperature 0 "SNA" ;
VAL_ 1520 USM_a187_ambientTemperature 0 "SNA" ;
VAL_ 1520 USM_a188_ambientTemperature 0 "SNA" ;
VAL_ 609 VCFRONT_12VBatteryStatusIndex 5 "Mux5" 4 "Mux4" 3 "Mux3" 2 "Mux2" 1 "Mux1" 0 "Mux0" ;
VAL_ 609 VCFRONT_batterySMState 10 "BATTERY_SM_STATE_EXTERNAL_LV_BUS_CONTROL" 9 "BATTERY_SM_STATE_RECOVERY" 8 "BATTERY_SM_STATE_FAULT" 7 "BATTERY_SM_STATE_SHORTED_CELL_TEST" 6 "BATTERY_SM_STATE_DISCONNECTED_BATTERY_TEST" 5 "BATTERY_SM_STATE_OTA_STANDBY" 4 "BATTERY_SM_STATE_RESISTANCE_ESTIMATION" 3 "BATTERY_SM_STATE_STANDBY" 2 "BATTERY_SM_STATE_DISCHARGE" 1 "BATTERY_SM_STATE_CHARGE" 0 "BATTERY_SM_STATE_INIT" ;
VAL_ 609 VCFRONT_eFuseRecoveryStateDBG 4 "VC_LVBMB_EFUSE_RECOVERY_STATE_BLOCKED" 3 "VC_LVBMB_EFUSE_RECOVERY_STATE_FINISH" 2 "VC_LVBMB_EFUSE_RECOVERY_STATE_CONNECT" 1 "VC_LVBMB_EFUSE_RECOVERY_STATE_SETUP" 0 "VC_LVBMB_EFUSE_RECOVERY_STATE_INACTIVE" ;
VAL_ 609 VCFRONT_batteryLINScheduleDBG 7 "VC_LVBMS_LIN_SCHEDULE_SNA" 6 "VC_LVBMS_LIN_SCHEDULE_OTHER" 4 "VC_LVBMS_LIN_SCHEDULE_DEFAULT_2" 3 "VC_LVBMS_LIN_SCHEDULE_DEFAULT_1" 2 "VC_LVBMS_LIN_SCHEDULE_DIAGNOSTIC" 1 "VC_LVBMS_LIN_SCHEDULE_RESET" 0 "VC_LVBMS_LIN_SCHEDULE_OFF" ;
VAL_ 609 VCFRONT_IBSVoltage 4095 "SNA" ;
VAL_ 609 VCFRONT_IBSTemperature 2047 "IBS_TEMPERATURE_SNA" ;
VAL_ 609 VCFRONT_LVBatteryStatusForDrive 2 "LV_BATTERY_EXIT_DRIVE_REQUESTED" 1 "LV_BATTERY_READY_FOR_DRIVE" 0 "LV_BATTERY_NOT_READY_FOR_DRIVE" ;
VAL_ 609 VCFRONT_LVBatteryType 5 "LV_BATTERY_TYPE_TESLA_48V_LI_ION" 4 "LV_BATTERY_TYPE_TESLA_16V_LI_ION" 3 "LV_BATTERY_TYPE_CATL_LI_ION" 2 "LV_BATTERY_TYPE_CLARIOS_B24_FLOODED" 1 "LV_BATTERY_TYPE_ATLASBX_B24_FLOODED" 0 "LV_BATTERY_TYPE_UNKNOWN" ;
VAL_ 609 VCFRONT_IBSVoltageFiltered 16383 "SNA" 16382 "MAX" 16381 "MIN" ;
VAL_ 609 VCFRONT_LVBMS_LVBusVoltageSource 3 "VC_LVBMS_VOLTAGE_SOURCE_LVBMS" 2 "VC_LVBMS_VOLTAGE_SOURCE_VBAT_MONITOR" 1 "VC_LVBMS_VOLTAGE_SOURCE_IBS" 0 "VC_LVBMS_VOLTAGE_SOURCE_NONE" ;
VAL_ 609 VCFRONT_LVBMS_LVPackCurrentSourc 2 "VC_LV_PACK_CURRENT_SOURCE_LVBMS" 1 "VC_LV_PACK_CURRENT_SOURCE_IBS" 0 "VC_LV_PACK_CURRENT_SOURCE_NONE" ;
VAL_ 609 VCFRONT_LVBatterySupportRqrdTrig 14336 "LV_BATTERY_SUPPORT_REQUIRED_TRIGGER_SOC_IMBALANCE_AND_CORRECTION" 12288 "LV_BATTERY_SUPPORT_REQUIRED_TRIGGER_IMBALANCE_AND_CORRECTION" 10240 "LV_BATTERY_SUPPORT_REQUIRED_TRIGGER_SOC_AND_CORRECTION" 8192 "LV_BATTERY_SUPPORT_REQUIRED_TRIGGER_CORRECTION" 6144 "LV_BATTERY_SUPPORT_REQUIRED_TRIGGER_SOC_AND_IMBALANCE" 4096 "LV_BATTERY_SUPPORT_REQUIRED_TRIGGER_IMBALANCE" 2048 "LV_BATTERY_SUPPORT_REQUIRED_TRIGGER_SOC" 1024 "LV_BATTERY_SUPPORT_REQUIRED_TRIGGER_POST_OTA" 512 "LV_BATTERY_SUPPORT_REQUIRED_TRIGGER_EXIT_TRANSPORT_MODE" 256 "LV_BATTERY_SUPPORT_REQUIRED_TRIGGER_POWER_ON_RESET" 128 "LV_BATTERY_SUPPORT_REQUIRED_TRIGGER_PERIODIC_CHARGE" 64 "LV_BATTERY_SUPPORT_REQUIRED_TRIGGER_AH_COUNT" 32 "LV_BATTERY_SUPPORT_REQUIRED_TRIGGER_UNKNOWN_VOLTAGE" 20 "LV_BATTERY_SUPPORT_REQUIRED_TRIGGER_RAW_VC_VOLTAGES" 16 "LV_BATTERY_SUPPORT_REQUIRED_TRIGGER_VBAT_RAW_VOLTAGE" 12 "LV_BATTERY_SUPPORT_REQUIRED_TRIGGER_RAW_BATTERY_VOLTAGES" 10 "LV_BATTERY_SUPPORT_REQUIRED_TRIGGER_PACK_VOLTAGES" 8 "LV_BATTERY_SUPPORT_REQUIRED_TRIGGER_PACK_RAW_VOLTAGE" 5 "LV_BATTERY_SUPPORT_REQUIRED_TRIGGER_IBS_VOLTAGES" 4 "LV_BATTERY_SUPPORT_REQUIRED_TRIGGER_IBS_RAW_VOLTAGE" 3 "LV_BATTERY_SUPPORT_REQUIRED_TRIGGER_FILTERED_VOLTAGES" 2 "LV_BATTERY_SUPPORT_REQUIRED_TRIGGER_PACK_FILTERED_VOLTAGE" 1 "LV_BATTERY_SUPPORT_REQUIRED_TRIGGER_IBS_FILTERED_VOLTAGE" 0 "LV_BATTERY_SUPPORT_REQUIRED_TRIGGER_NONE" ;
VAL_ 609 VCFRONT_voltageProfile 3 "VOLTAGE_PROFILE_ALWAYS_CLOSED_CONTACTORS" 2 "VOLTAGE_PROFILE_REDUCED_FLOAT" 1 "VOLTAGE_PROFILE_FLOAT" 0 "VOLTAGE_PROFILE_CHARGE" ;
VAL_ 609 VCFRONT_IBSVoltageRawDBG 16383 "SNA" 16382 "MAX" 16381 "MIN" ;
VAL_ 2017 VCFRONT_LVHealthStatus 3 "BACKUP_COMPROMISED" 2 "LATENT_FAULT" 1 "HEALTHY_LIMITED" 0 "DOMAIN_HEALTHY" ;
VAL_ 2017 VCFRONT_LVStatusForDrive 6 "STATUS_FOR_DRIVE_ACTIVE_DECEL" 5 "STATUS_FOR_DRIVE_PULL_TO_SHOULDER" 4 "STATUS_FOR_DRIVE_LIMP" 3 "STATUS_FOR_DRIVE_RETURN_TO_SERVICE" 2 "STATUS_FOR_DRIVE_READY_LIMITED" 1 "STATUS_FOR_DRIVE_READY" 0 "STATUS_FOR_DRIVE_NOT_READY" ;
VAL_ 2017 VCFRONT_LVPowerSecondsToSafeHarb 65535 "INDEFINITE" ;
